[part 6 of 12: package /Cluster]
AUTOSAR XML (schema 4-3-0)
package /Cluster  (continued)
  can cluster HCP5_CANFD01: baudrate=500000, protocol-name=CAN, protocol-version=2.0, bus-off-recovery={bor-counter-l-1-to-l-2=1, bor-time-l-1=0.05, bor-time-l-2=0.2}, can-fd-baudrate=2000000  (continued)
    can physical channel CHNL: comm-connectors=CN_HCP5_CANFD01  (continued)
      frame NM_SACID_1_XIX_HCP5_CANFD01: id 0x1B00011B, to BMC_HV, frame-length=24, can-addressing-mode=EXTENDED, can-frame-rx-behavior=CAN-FD, can-frame-tx-behavior=CAN-FD, rx-identifier-range={lower-can-id=452984832, upper-can-id=452985855}
        nm pdu NM_SACID_1_XIX_HCP5_CANFD01: length=24, unused-bit-pattern=0
          signal NM_SACID_1_CBV_AWB_XIX_NM_SACID_1_XIX_HCP5_CANFD01: start 4, 1 bit, little-endian, data-type-policy=OVERRIDE, i-signal-type=PRIMITIVE, init-value=0, base-type=BT_NM_SACID_1_CBV_AWB, compu {0=Cx0_Passiver_WakeUp (CM_NM_SACID_1_CBV_AWB_Cx0_Passiver_WakeUp), 1=Cx1_Aktiver_WakeUp (CM_NM_SACID_1_CBV_AWB_Cx1_Aktiver_WakeUp)}, range raw 0..1, transfer-property=TRIGGERED  # Das Signal ist zu setzen, wenn das SG aktiv den Bus geweckt hat 0 = Passiver_WakeUp = SG hat das Netzwerk nicht aktiv geweckt 1 = Akitiver_WakeUp = SG hat das Netzwerk aktiv geweckt
          signal NM_SACID_1_CBV_CRI_XIX_NM_SACID_1_XIX_HCP5_CANFD01: start 6, 1 bit, little-endian, data-type-policy=OVERRIDE, i-signal-type=PRIMITIVE, init-value=1, base-type=BT_NM_SACID_1_CBV_CRI, compu {0=Cx0_NM_ohne_Clusteranforderungen (CM_NM_SACID_1_CBV_CRI_Cx0_NM_ohne_Clusteranforderungen), 1=Cx1_NM_mit_Clusteranforderungen (CM_NM_SACID_1_CBV_CRI_Cx1_NM_mit_Clusteranforderungen)}, range raw 0..1, transfer-property=TRIGGERED  # Das Signal ist dauerhaft gesetzt, wenn das NM-Layout Cluster- Anforderungen enthält
          signal NM_SACID_1_FCAB_XIX_NM_SACID_1_XIX_HCP5_CANFD01: start 8, 56 bit, opaque, data-type-policy=OVERRIDE, i-signal-type=ARRAY, init-value=7 x 0b00000000, base-type=BT_NM_SACID_1_FCAB, compu {0=Cx0_Init (CM_NM_SACID_1_FCAB_Cx0_Init), 1=Cx1_01_CarWakeUp (CM_NM_SACID_1_FCAB_Cx1_01_CarWakeUp), 2=Cx2_02_Basefunction_Powertrain (CM_NM_SACID_1_FCAB_Cx2_02_Basefunction_Powertrain), 4=Cx4_03_Basefunction_Chassis (CM_NM_SACID_1_FCAB_Cx4_03_Basefunction_Chassis), 8=Cx8_04_Basefunction_DrivingAssistance (CM_NM_SACID_1_FCAB_Cx8_04_Basefunction_DrivingAssistance), 16=Cx10_05_Basefunction_Infotainment (CM_NM_SACID_1_FCAB_Cx10_05_Basefunction_Infotainment), 32=Cx20_06_Basefunction_ComfortLight (CM_NM_SACID_1_FCAB_Cx20_06_Basefunction_ComfortLight), 64=Cx40_07_Basefunction_CrossSection (CM_NM_SACID_1_FCAB_Cx40_07_Basefunction_CrossSection), 128=Cx80_08_Basefunction_Connectivity (CM_NM_SACID_1_FCAB_Cx80_08_Basefunction_Connectivity), 256=Cx100_09_Basefunction_DrivingAssistanceCore (CM_NM_SACID_1_FCAB_Cx100_09_Basefunction_DrivingAssistanceCore), 512=Cx200_10_Powertrain (CM_NM_SACID_1_FCAB_Cx200_10_Powertrain), 1024=Cx400_11_Chassis (CM_NM_SACID_1_FCAB_Cx400_11_Chassis), 2048=Cx800_12_GearSelector (CM_NM_SACID_1_FCAB_Cx800_12_GearSelector), 4096=Cx1000_13_Airbag (CM_NM_SACID_1_FCAB_Cx1000_13_Airbag), 8192=Cx2000_14_InfotainmentExtensions (CM_NM_SACID_1_FCAB_Cx2000_14_InfotainmentExtensions), 16384=Cx4000_15_InstrumentclusterDisplay (CM_NM_SACID_1_FCAB_Cx4000_15_InstrumentclusterDisplay), 32768=Cx8000_16_InfotainmentDisplay (CM_NM_SACID_1_FCAB_Cx8000_16_InfotainmentDisplay), 65536=Cx10000_17_Audio (CM_NM_SACID_1_FCAB_Cx10000_17_Audio), 131072=Cx20000_18_VirtualSideMirrors (CM_NM_SACID_1_FCAB_Cx20000_18_VirtualSideMirrors), 262144=Cx40000_19_Doors_Hatches (CM_NM_SACID_1_FCAB_Cx40000_19_Doors_Hatches), 524288=Cx80000_20_OptionalComfort (CM_NM_SACID_1_FCAB_Cx80000_20_OptionalComfort), 1048576=Cx100000_21_AirSuspension (CM_NM_SACID_1_FCAB_Cx100000_21_AirSuspension), 2097152=Cx200000_22_ExteriorLights (CM_NM_SACID_1_FCAB_Cx200000_22_ExteriorLights), 4194304=Cx400000_23_Climate (CM_NM_SACID_1_FCAB_Cx400000_23_Climate), 8388608=Cx800000_24_ThermoManagement (CM_NM_SACID_1_FCAB_Cx800000_24_ThermoManagement), 16777216=Cx1000000_25_AccessSystemSensors (CM_NM_SACID_1_FCAB_Cx1000000_25_AccessSystemSensors), 33554432=Cx2000000_26_HighVoltage_Charging (CM_NM_SACID_1_FCAB_Cx2000000_26_HighVoltage_Charging), 67108864=Cx4000000_27_Timemaster_Timer (CM_NM_SACID_1_FCAB_Cx4000000_27_Timemaster_Timer), 134217728=Cx8000000_28_OnboardTester_DataCollector (CM_NM_SACID_1_FCAB_Cx8000000_28_OnboardTester_DataCollector), 268435456=Cx10000000_29_SteeringColumnLock (CM_NM_SACID_1_FCAB_Cx10000000_29_SteeringColumnLock), 536870912=Cx20000000_30_EnergyManagement (CM_NM_SACID_1_FCAB_Cx20000000_30_EnergyManagement), 1073741824=Cx40000000_31_MultifunctionalSteeringWheel (CM_NM_SACID_1_FCAB_Cx40000000_31_MultifunctionalSteeringWheel), 2147483648=Cx80000000_32_OnlineAccess (CM_NM_SACID_1_FCAB_Cx80000000_32_OnlineAccess), 4294967296=Cx100000000_33_ExternalWirelessCommunication (CM_NM_SACID_1_FCAB_Cx100000000_33_ExternalWirelessCommunication), 8589934592=Cx200000000_34_GPS_Localization (CM_NM_SACID_1_FCAB_Cx200000000_34_GPS_Localization), 17179869184=Cx400000000_35_ExteriorSound (CM_NM_SACID_1_FCAB_Cx400000000_35_ExteriorSound), 34359738368=Cx800000000_36_Preheater (CM_NM_SACID_1_FCAB_Cx800000000_36_Preheater), 68719476736=Cx1000000000_37_HighVoltage_WirelessChargingStation (CM_NM_SACID_1_FCAB_Cx1000000000_37_HighVoltage_WirelessChargingStation), 549755813888=Cx8000000000_40_Diagnosis_Energy (CM_NM_SACID_1_FCAB_Cx8000000000_40_Diagnosis_Energy), 1099511627776=Cx10000000000_41_Diagnosis_Powertrain (CM_NM_SACID_1_FCAB_Cx10000000000_41_Diagnosis_Powertrain), 2199023255552=Cx20000000000_42_Diagnosis_FlexRay (CM_NM_SACID_1_FCAB_Cx20000000000_42_Diagnosis_FlexRay), 4398046511104=Cx40000000000_43_Diagnosis_DrivingAssistance (CM_NM_SACID_1_FCAB_Cx40000000000_43_Diagnosis_DrivingAssistance), 8796093022208=Cx80000000000_44_Diagnosis_Infotainment (CM_NM_SACID_1_FCAB_Cx80000000000_44_Diagnosis_Infotainment), 17592186044416=Cx100000000000_45_Diagnosis_Comfort (CM_NM_SACID_1_FCAB_Cx100000000000_45_Diagnosis_Comfort), 35184372088832=Cx200000000000_46_Diagnosis_Light (CM_NM_SACID_1_FCAB_Cx200000000000_46_Diagnosis_Light), 70368744177664=Cx400000000000_47_Diagnosis_ComfortLINs (CM_NM_SACID_1_FCAB_Cx400000000000_47_Diagnosis_ComfortLINs), 140737488355328=Cx800000000000_48_Diagnosis_ClimateTmeLINs (CM_NM_SACID_1_FCAB_Cx800000000000_48_Diagnosis_ClimateTmeLINs), 281474976710656=Cx1000000000000_49_reserved (CM_NM_SACID_1_FCAB_Cx1000000000000_49_reserved) (49_<reserved>), 4503599627370500.0=Cx10000000000000_53_Lock_Unlock (CM_NM_SACID_1_FCAB_Cx10000000000000_53_Lock_Unlock), 9007199254740990.0=Cx20000000000000_54_reserved (CM_NM_SACID_1_FCAB_Cx20000000000000_54_reserved) (54_<reserved>), 1.8014398509482e+16=Cx40000000000000_55_Dimming (CM_NM_SACID_1_FCAB_Cx40000000000000_55_Dimming), 3.6028797018964e+16=Cx80000000000000_56_ChargingStatus (CM_NM_SACID_1_FCAB_Cx80000000000000_56_ChargingStatus)}, range raw 0..36028797018963968, transfer-property=TRIGGERED-ON-CHANGE, to BMC_HV(timeout 2 s)  # FCAB = Funktions-Cluster-Aktiv-Bits
          signal NM_SACID_1_SNI_10_XIX_NM_SACID_1_XIX_HCP5_CANFD01: start 128, 10 bit, little-endian, data-type-policy=OVERRIDE, i-signal-type=PRIMITIVE, init-value=283, base-type=BT_NM_SACID_1_SNI_10, compu {283=Cx11b_SACID_1_SNI (CM_NM_SACID_1_SNI_10_Cx11b_SACID_1_SNI)}, range raw 283, transfer-property=TRIGGERED  # Source Node-Identifier (SNI) identifiziert den Sender der NM-Botschaft (Knotenadresse) eindeutig im Fahrzeug
          signal NM_SACID_1_NM_State_XIX_NM_SACID_1_XIX_HCP5_CANFD01: start 144, 6 bit, little-endian, data-type-policy=OVERRIDE, i-signal-type=PRIMITIVE, init-value=0, base-type=BT_NM_SACID_1_NM_State, compu {0=Cx0_Init (CM_NM_SACID_1_NM_State_Cx0_Init), 1=Cx1_NM_RM_aus_BSM (CM_NM_SACID_1_NM_State_Cx1_NM_RM_aus_BSM), 2=Cx2_NM_RM_aus_PBSM (CM_NM_SACID_1_NM_State_Cx2_NM_RM_aus_PBSM), 4=Cx4_NM_NO_aus_RM (CM_NM_SACID_1_NM_State_Cx4_NM_NO_aus_RM), 8=Cx8_NM_NO_aus_RS (CM_NM_SACID_1_NM_State_Cx8_NM_NO_aus_RS), 16=Cx10_reserved (CM_NM_SACID_1_NM_State_Cx10_reserved), 32=Cx20_reserved (CM_NM_SACID_1_NM_State_Cx20_reserved)}, range raw 0..32, transfer-property=TRIGGERED  # 1 = Zustand Repeat Message (<-- Bus-Sleep Mode) 2 = Zustand Repeat Message (<-- Prepare Bus-Sleep Mode) 4 = Zustand Normal Operation (<-- Repeat Message) 8 = Zustand Normal Operation (<-- Ready Sleep)
          signal NM_SACID_1_UDS_CC_XIX_NM_SACID_1_XIX_HCP5_CANFD01: start 151, 1 bit, little-endian, data-type-policy=OVERRIDE, i-signal-type=PRIMITIVE, init-value=0, base-type=BT_NM_SACID_1_UDS_CC, compu {0=Cx0_Inaktiv (CM_NM_SACID_1_UDS_CC_Cx0_Inaktiv), 1=Cx1_CC_aktiv (CM_NM_SACID_1_UDS_CC_Cx1_CC_aktiv)}, range raw 0..1, transfer-property=TRIGGERED  # Funktionseinschränkung aufgrund aktivem UDS-Communication Control, siehe VW80124
          signal NM_SACID_1_Wakeup_V12_XIX_NM_SACID_1_XIX_HCP5_CANFD01: start 152, 8 bit, little-endian, data-type-policy=OVERRIDE, i-signal-type=PRIMITIVE, init-value=0, base-type=BT_NM_SACID_1_Wakeup_V12, compu {0=Cx0_Peripherie_Wakeup_Ursache_nicht_bekannt (CM_NM_SACID_1_Wakeup_V12_Cx0_Peripherie_Wakeup_Ursache_nicht_bekannt), 1=Cx1_Bus_Wakeup (CM_NM_SACID_1_Wakeup_V12_Cx1_Bus_Wakeup), 2=Cx2_KL15_HW (CM_NM_SACID_1_Wakeup_V12_Cx2_KL15_HW), 4=Cx4_Bedienung_an_Ladedose (CM_NM_SACID_1_Wakeup_V12_Cx4_Bedienung_an_Ladedose), 5=Cx5_Stecker_erkannt (CM_NM_SACID_1_Wakeup_V12_Cx5_Stecker_erkannt), 6=Cx6_SmartCharging_Aktualisierung (CM_NM_SACID_1_Wakeup_V12_Cx6_SmartCharging_Aktualisierung)}, range raw 0..6, transfer-property=TRIGGERED  # enthält die Weckursache; stehen mehrere Weckursachen parallel an, dann muss der kleinste Wert übertragen werden
          signal NM_SACID_1_NM_aktiv_KL15_XIX_NM_SACID_1_XIX_HCP5_CANFD01: start 160, 1 bit, little-endian, data-type-policy=OVERRIDE, i-signal-type=PRIMITIVE, init-value=0, base-type=BT_NM_SACID_1_NM_aktiv_KL15, compu {0=Cx0_Inaktiv (CM_NM_SACID_1_NM_aktiv_KL15_Cx0_Inaktiv), 1=Cx1_KL15_EIN (CM_NM_SACID_1_NM_aktiv_KL15_Cx1_KL15_EIN)}, range raw 0..1, transfer-property=TRIGGERED  # Steuergerät hat KL15-EIN erkannt
          signal NM_SACID_1_NM_aktiv_Diag_XIX_NM_SACID_1_XIX_HCP5_CANFD01: start 161, 1 bit, little-endian, data-type-policy=OVERRIDE, i-signal-type=PRIMITIVE, init-value=0, base-type=BT_NM_SACID_1_NM_aktiv_Diag, compu {0=Cx0_Inaktiv (CM_NM_SACID_1_NM_aktiv_Diag_Cx0_Inaktiv), 1=Cx1_Diagnose_aktiv (CM_NM_SACID_1_NM_aktiv_Diag_Cx1_Diagnose_aktiv)}, range raw 0..1, transfer-property=TRIGGERED  # Diagnose befindet sich nach VW80124 in einer NonDefaultDiagnostic-Session, z.B. ExtendedDiagnostic-Session
          signal NM_SACID_1_NM_aktiv_Tmin_XIX_NM_SACID_1_XIX_HCP5_CANFD01: start 162, 1 bit, little-endian, data-type-policy=OVERRIDE, i-signal-type=PRIMITIVE, init-value=0, base-type=BT_NM_SACID_1_NM_aktiv_Tmin, compu {0=Cx0_Inaktiv (CM_NM_SACID_1_NM_aktiv_Tmin_Cx0_Inaktiv), 1=Cx1_Mindestaktivzeit (CM_NM_SACID_1_NM_aktiv_Tmin_Cx1_Mindestaktivzeit)}, range raw 0..1, transfer-property=TRIGGERED  # Mindestaktivzeit ist noch nicht abgelaufen (bei jedem Weckereignis wird die Mindestaktivzeit neu gestartet)
          signal NM_aktiv_Bedienung_an_Ladedose_1_XIX_NM_SACID_1_XIX_HCP5_CANFD01: start 163, 1 bit, little-endian, data-type-policy=OVERRIDE, i-signal-type=PRIMITIVE, init-value=0, base-type=BT_NM_aktiv_Bedienung_an_Ladedose_1, compu {0=Cx0_Inaktiv (CM_NM_aktiv_Bedienung_an_Ladedose_1_Cx0_Inaktiv), 1=Cx1_Aktiv (CM_NM_aktiv_Bedienung_an_Ladedose_1_Cx1_Aktiv)}, range raw 0..1, transfer-property=TRIGGERED  # Für die verschiedenen Bedienelemente an der Ladedose muss die HV-Ladefunktion im HCP5 geweckt werden um den Status zu erhalten und ggf. weitere Steuergeräte zu wecken
          signal NM_aktiv_Ladestecker_erkannt_1_XIX_NM_SACID_1_XIX_HCP5_CANFD01: start 164, 1 bit, little-endian, data-type-policy=OVERRIDE, i-signal-type=PRIMITIVE, init-value=0, base-type=BT_NM_aktiv_Ladestecker_erkannt_1, compu {0=Cx0_Inaktiv (CM_NM_aktiv_Ladestecker_erkannt_1_Cx0_Inaktiv), 1=Cx1_Aktiv (CM_NM_aktiv_Ladestecker_erkannt_1_Cx1_Aktiv)}, range raw 0..1, transfer-property=TRIGGERED  # Ladestecker erkannt und Absetzen der Information an das Hochvolt-Lademanagement
          signal NM_aktiv_SmartCharging_Aktiv_XIX_NM_SACID_1_XIX_HCP5_CANFD01: start 165, 1 bit, little-endian, data-type-policy=OVERRIDE, i-signal-type=PRIMITIVE, init-value=0, base-type=BT_NM_aktiv_SmartCharging_Aktiv, compu {0=Cx0_Inaktiv (CM_NM_aktiv_SmartCharging_Aktiv_Cx0_Inaktiv), 1=Cx1_Aktiv (CM_NM_aktiv_SmartCharging_Aktiv_Cx1_Aktiv)}, range raw 0..1, transfer-property=TRIGGERED  # Wenn eine Verbindung zum Smart Home's HEMS über die ConMod via WLAN aufgebaut wurde, dann muss das SACID 1 die Verbindugn so lange aktiv halten bis alle Daten empfangen wurden.
      frame NM_SACID_2_XIX_HCP5_CANFD01: id 0x1B00011C, to BMC_HV, frame-length=24, can-addressing-mode=EXTENDED, can-frame-rx-behavior=CAN-FD, can-frame-tx-behavior=CAN-FD, rx-identifier-range={lower-can-id=452984832, upper-can-id=452985855}
        nm pdu NM_SACID_2_XIX_HCP5_CANFD01: length=24, unused-bit-pattern=0
          signal NM_SACID_2_CBV_AWB_XIX_NM_SACID_2_XIX_HCP5_CANFD01: start 4, 1 bit, little-endian, data-type-policy=OVERRIDE, i-signal-type=PRIMITIVE, init-value=0, base-type=BT_NM_SACID_2_CBV_AWB, compu {0=Cx0_Passiver_WakeUp (CM_NM_SACID_2_CBV_AWB_Cx0_Passiver_WakeUp), 1=Cx1_Aktiver_WakeUp (CM_NM_SACID_2_CBV_AWB_Cx1_Aktiver_WakeUp)}, range raw 0..1, transfer-property=TRIGGERED  # Das Signal ist zu setzen, wenn das SG aktiv den Bus geweckt hat 0 = Passiver_WakeUp = SG hat das Netzwerk nicht aktiv geweckt 1 = Akitiver_WakeUp = SG hat das Netzwerk aktiv geweckt
          signal NM_SACID_2_CBV_CRI_XIX_NM_SACID_2_XIX_HCP5_CANFD01: start 6, 1 bit, little-endian, data-type-policy=OVERRIDE, i-signal-type=PRIMITIVE, init-value=1, base-type=BT_NM_SACID_2_CBV_CRI, compu {0=Cx0_NM_ohne_Clusteranforderungen (CM_NM_SACID_2_CBV_CRI_Cx0_NM_ohne_Clusteranforderungen), 1=Cx1_NM_mit_Clusteranforderungen (CM_NM_SACID_2_CBV_CRI_Cx1_NM_mit_Clusteranforderungen)}, range raw 0..1, transfer-property=TRIGGERED  # Das Signal ist dauerhaft gesetzt, wenn das NM-Layout Cluster- Anforderungen enthält
          signal NM_SACID_2_FCAB_XIX_NM_SACID_2_XIX_HCP5_CANFD01: start 8, 56 bit, opaque, data-type-policy=OVERRIDE, i-signal-type=ARRAY, init-value=7 x 0b00000000, base-type=BT_NM_SACID_2_FCAB, compu {0=Cx0_Init (CM_NM_SACID_2_FCAB_Cx0_Init), 1=Cx1_01_CarWakeUp (CM_NM_SACID_2_FCAB_Cx1_01_CarWakeUp), 2=Cx2_02_Basefunction_Powertrain (CM_NM_SACID_2_FCAB_Cx2_02_Basefunction_Powertrain), 4=Cx4_03_Basefunction_Chassis (CM_NM_SACID_2_FCAB_Cx4_03_Basefunction_Chassis), 8=Cx8_04_Basefunction_DrivingAssistance (CM_NM_SACID_2_FCAB_Cx8_04_Basefunction_DrivingAssistance), 16=Cx10_05_Basefunction_Infotainment (CM_NM_SACID_2_FCAB_Cx10_05_Basefunction_Infotainment), 32=Cx20_06_Basefunction_ComfortLight (CM_NM_SACID_2_FCAB_Cx20_06_Basefunction_ComfortLight), 64=Cx40_07_Basefunction_CrossSection (CM_NM_SACID_2_FCAB_Cx40_07_Basefunction_CrossSection), 128=Cx80_08_Basefunction_Connectivity (CM_NM_SACID_2_FCAB_Cx80_08_Basefunction_Connectivity), 256=Cx100_09_Basefunction_DrivingAssistanceCore (CM_NM_SACID_2_FCAB_Cx100_09_Basefunction_DrivingAssistanceCore), 512=Cx200_10_Powertrain (CM_NM_SACID_2_FCAB_Cx200_10_Powertrain), 1024=Cx400_11_Chassis (CM_NM_SACID_2_FCAB_Cx400_11_Chassis), 2048=Cx800_12_GearSelector (CM_NM_SACID_2_FCAB_Cx800_12_GearSelector), 4096=Cx1000_13_Airbag (CM_NM_SACID_2_FCAB_Cx1000_13_Airbag), 8192=Cx2000_14_InfotainmentExtensions (CM_NM_SACID_2_FCAB_Cx2000_14_InfotainmentExtensions), 16384=Cx4000_15_InstrumentclusterDisplay (CM_NM_SACID_2_FCAB_Cx4000_15_InstrumentclusterDisplay), 32768=Cx8000_16_InfotainmentDisplay (CM_NM_SACID_2_FCAB_Cx8000_16_InfotainmentDisplay), 65536=Cx10000_17_Audio (CM_NM_SACID_2_FCAB_Cx10000_17_Audio), 131072=Cx20000_18_VirtualSideMirrors (CM_NM_SACID_2_FCAB_Cx20000_18_VirtualSideMirrors), 262144=Cx40000_19_Doors_Hatches (CM_NM_SACID_2_FCAB_Cx40000_19_Doors_Hatches), 524288=Cx80000_20_OptionalComfort (CM_NM_SACID_2_FCAB_Cx80000_20_OptionalComfort), 1048576=Cx100000_21_AirSuspension (CM_NM_SACID_2_FCAB_Cx100000_21_AirSuspension), 2097152=Cx200000_22_ExteriorLights (CM_NM_SACID_2_FCAB_Cx200000_22_ExteriorLights), 4194304=Cx400000_23_Climate (CM_NM_SACID_2_FCAB_Cx400000_23_Climate), 8388608=Cx800000_24_ThermoManagement (CM_NM_SACID_2_FCAB_Cx800000_24_ThermoManagement), 16777216=Cx1000000_25_AccessSystemSensors (CM_NM_SACID_2_FCAB_Cx1000000_25_AccessSystemSensors), 33554432=Cx2000000_26_HighVoltage_Charging (CM_NM_SACID_2_FCAB_Cx2000000_26_HighVoltage_Charging), 67108864=Cx4000000_27_Timemaster_Timer (CM_NM_SACID_2_FCAB_Cx4000000_27_Timemaster_Timer), 134217728=Cx8000000_28_OnboardTester_DataCollector (CM_NM_SACID_2_FCAB_Cx8000000_28_OnboardTester_DataCollector), 268435456=Cx10000000_29_SteeringColumnLock (CM_NM_SACID_2_FCAB_Cx10000000_29_SteeringColumnLock), 536870912=Cx20000000_30_EnergyManagement (CM_NM_SACID_2_FCAB_Cx20000000_30_EnergyManagement), 1073741824=Cx40000000_31_MultifunctionalSteeringWheel (CM_NM_SACID_2_FCAB_Cx40000000_31_MultifunctionalSteeringWheel), 2147483648=Cx80000000_32_OnlineAccess (CM_NM_SACID_2_FCAB_Cx80000000_32_OnlineAccess), 4294967296=Cx100000000_33_ExternalWirelessCommunication (CM_NM_SACID_2_FCAB_Cx100000000_33_ExternalWirelessCommunication), 8589934592=Cx200000000_34_GPS_Localization (CM_NM_SACID_2_FCAB_Cx200000000_34_GPS_Localization), 17179869184=Cx400000000_35_ExteriorSound (CM_NM_SACID_2_FCAB_Cx400000000_35_ExteriorSound), 34359738368=Cx800000000_36_Preheater (CM_NM_SACID_2_FCAB_Cx800000000_36_Preheater), 68719476736=Cx1000000000_37_HighVoltage_WirelessChargingStation (CM_NM_SACID_2_FCAB_Cx1000000000_37_HighVoltage_WirelessChargingStation), 549755813888=Cx8000000000_40_Diagnosis_Energy (CM_NM_SACID_2_FCAB_Cx8000000000_40_Diagnosis_Energy), 1099511627776=Cx10000000000_41_Diagnosis_Powertrain (CM_NM_SACID_2_FCAB_Cx10000000000_41_Diagnosis_Powertrain), 2199023255552=Cx20000000000_42_Diagnosis_FlexRay (CM_NM_SACID_2_FCAB_Cx20000000000_42_Diagnosis_FlexRay), 4398046511104=Cx40000000000_43_Diagnosis_DrivingAssistance (CM_NM_SACID_2_FCAB_Cx40000000000_43_Diagnosis_DrivingAssistance), 8796093022208=Cx80000000000_44_Diagnosis_Infotainment (CM_NM_SACID_2_FCAB_Cx80000000000_44_Diagnosis_Infotainment), 17592186044416=Cx100000000000_45_Diagnosis_Comfort (CM_NM_SACID_2_FCAB_Cx100000000000_45_Diagnosis_Comfort), 35184372088832=Cx200000000000_46_Diagnosis_Light (CM_NM_SACID_2_FCAB_Cx200000000000_46_Diagnosis_Light), 70368744177664=Cx400000000000_47_Diagnosis_ComfortLINs (CM_NM_SACID_2_FCAB_Cx400000000000_47_Diagnosis_ComfortLINs), 140737488355328=Cx800000000000_48_Diagnosis_ClimateTmeLINs (CM_NM_SACID_2_FCAB_Cx800000000000_48_Diagnosis_ClimateTmeLINs), 281474976710656=Cx1000000000000_49_reserved (CM_NM_SACID_2_FCAB_Cx1000000000000_49_reserved) (49_<reserved>), 4503599627370500.0=Cx10000000000000_53_Lock_Unlock (CM_NM_SACID_2_FCAB_Cx10000000000000_53_Lock_Unlock), 9007199254740990.0=Cx20000000000000_54_reserved (CM_NM_SACID_2_FCAB_Cx20000000000000_54_reserved) (54_<reserved>), 1.8014398509482e+16=Cx40000000000000_55_Dimming (CM_NM_SACID_2_FCAB_Cx40000000000000_55_Dimming), 3.6028797018964e+16=Cx80000000000000_56_ChargingStatus (CM_NM_SACID_2_FCAB_Cx80000000000000_56_ChargingStatus)}, range raw 0..36028797018963968, transfer-property=TRIGGERED-ON-CHANGE, to BMC_HV(timeout 2 s)  # FCAB = Funktions-Cluster-Aktiv-Bits
          signal NM_SACID_2_SNI_10_XIX_NM_SACID_2_XIX_HCP5_CANFD01: start 128, 10 bit, little-endian, data-type-policy=OVERRIDE, i-signal-type=PRIMITIVE, init-value=284, base-type=BT_NM_SACID_2_SNI_10, compu {284=Cx11c_SACID_2_SNI (CM_NM_SACID_2_SNI_10_Cx11c_SACID_2_SNI)}, range raw 284, transfer-property=TRIGGERED  # Source Node-Identifier (SNI) identifiziert den Sender der NM-Botschaft (Knotenadresse) eindeutig im Fahrzeug
          signal NM_SACID_2_NM_State_XIX_NM_SACID_2_XIX_HCP5_CANFD01: start 144, 6 bit, little-endian, data-type-policy=OVERRIDE, i-signal-type=PRIMITIVE, init-value=0, base-type=BT_NM_SACID_2_NM_State, compu {0=Cx0_Init (CM_NM_SACID_2_NM_State_Cx0_Init), 1=Cx1_NM_RM_aus_BSM (CM_NM_SACID_2_NM_State_Cx1_NM_RM_aus_BSM), 2=Cx2_NM_RM_aus_PBSM (CM_NM_SACID_2_NM_State_Cx2_NM_RM_aus_PBSM), 4=Cx4_NM_NO_aus_RM (CM_NM_SACID_2_NM_State_Cx4_NM_NO_aus_RM), 8=Cx8_NM_NO_aus_RS (CM_NM_SACID_2_NM_State_Cx8_NM_NO_aus_RS), 16=Cx10_reserved (CM_NM_SACID_2_NM_State_Cx10_reserved), 32=Cx20_reserved (CM_NM_SACID_2_NM_State_Cx20_reserved)}, range raw 0..32, transfer-property=TRIGGERED  # 1 = Zustand Repeat Message (<-- Bus-Sleep Mode) 2 = Zustand Repeat Message (<-- Prepare Bus-Sleep Mode) 4 = Zustand Normal Operation (<-- Repeat Message) 8 = Zustand Normal Operation (<-- Ready Sleep)
          signal NM_SACID_2_UDS_CC_XIX_NM_SACID_2_XIX_HCP5_CANFD01: start 151, 1 bit, little-endian, data-type-policy=OVERRIDE, i-signal-type=PRIMITIVE, init-value=0, base-type=BT_NM_SACID_2_UDS_CC, compu {0=Cx0_Inaktiv (CM_NM_SACID_2_UDS_CC_Cx0_Inaktiv), 1=Cx1_CC_aktiv (CM_NM_SACID_2_UDS_CC_Cx1_CC_aktiv)}, range raw 0..1, transfer-property=TRIGGERED  # Funktionseinschränkung aufgrund aktivem UDS-Communication Control, siehe VW80124
          signal NM_SACID_2_Wakeup_V12_XIX_NM_SACID_2_XIX_HCP5_CANFD01: start 152, 8 bit, little-endian, data-type-policy=OVERRIDE, i-signal-type=PRIMITIVE, init-value=0, base-type=BT_NM_SACID_2_Wakeup_V12, compu {0=Cx0_Peripherie_Wakeup_Ursache_nicht_bekannt (CM_NM_SACID_2_Wakeup_V12_Cx0_Peripherie_Wakeup_Ursache_nicht_bekannt), 1=Cx1_Bus_Wakeup (CM_NM_SACID_2_Wakeup_V12_Cx1_Bus_Wakeup), 2=Cx2_KL15_HW (CM_NM_SACID_2_Wakeup_V12_Cx2_KL15_HW), 4=Cx4_Bedienung_an_Ladedose (CM_NM_SACID_2_Wakeup_V12_Cx4_Bedienung_an_Ladedose), 5=Cx5_Stecker_erkannt (CM_NM_SACID_2_Wakeup_V12_Cx5_Stecker_erkannt)}, range raw 0..5, transfer-property=TRIGGERED  # enthält die Weckursache; stehen mehrere Weckursachen parallel an, dann muss der kleinste Wert übertragen werden
          signal NM_SACID_2_NM_aktiv_KL15_XIX_NM_SACID_2_XIX_HCP5_CANFD01: start 160, 1 bit, little-endian, data-type-policy=OVERRIDE, i-signal-type=PRIMITIVE, init-value=0, base-type=BT_NM_SACID_2_NM_aktiv_KL15, compu {0=Cx0_Inaktiv (CM_NM_SACID_2_NM_aktiv_KL15_Cx0_Inaktiv), 1=Cx1_KL15_EIN (CM_NM_SACID_2_NM_aktiv_KL15_Cx1_KL15_EIN)}, range raw 0..1, transfer-property=TRIGGERED  # Steuergerät hat KL15-EIN erkannt
          signal NM_SACID_2_NM_aktiv_Diag_XIX_NM_SACID_2_XIX_HCP5_CANFD01: start 161, 1 bit, little-endian, data-type-policy=OVERRIDE, i-signal-type=PRIMITIVE, init-value=0, base-type=BT_NM_SACID_2_NM_aktiv_Diag, compu {0=Cx0_Inaktiv (CM_NM_SACID_2_NM_aktiv_Diag_Cx0_Inaktiv), 1=Cx1_Diagnose_aktiv (CM_NM_SACID_2_NM_aktiv_Diag_Cx1_Diagnose_aktiv)}, range raw 0..1, transfer-property=TRIGGERED  # Diagnose befindet sich nach VW80124 in einer NonDefaultDiagnostic-Session, z.B. ExtendedDiagnostic-Session
          signal NM_SACID_2_NM_aktiv_Tmin_XIX_NM_SACID_2_XIX_HCP5_CANFD01: start 162, 1 bit, little-endian, data-type-policy=OVERRIDE, i-signal-type=PRIMITIVE, init-value=0, base-type=BT_NM_SACID_2_NM_aktiv_Tmin, compu {0=Cx0_Inaktiv (CM_NM_SACID_2_NM_aktiv_Tmin_Cx0_Inaktiv), 1=Cx1_Mindestaktivzeit (CM_NM_SACID_2_NM_aktiv_Tmin_Cx1_Mindestaktivzeit)}, range raw 0..1, transfer-property=TRIGGERED  # Mindestaktivzeit ist noch nicht abgelaufen (bei jedem Weckereignis wird die Mindestaktivzeit neu gestartet)
          signal NM_aktiv_Bedienung_an_Ladedose_2_XIX_NM_SACID_2_XIX_HCP5_CANFD01: start 163, 1 bit, little-endian, data-type-policy=OVERRIDE, i-signal-type=PRIMITIVE, init-value=0, base-type=BT_NM_aktiv_Bedienung_an_Ladedose_2, compu {0=Cx0_Inaktiv (CM_NM_aktiv_Bedienung_an_Ladedose_2_Cx0_Inaktiv), 1=Cx1_Aktiv (CM_NM_aktiv_Bedienung_an_Ladedose_2_Cx1_Aktiv)}, range raw 0..1, transfer-property=TRIGGERED  # Für die verschiedenen Bedienelemente an der Ladedose muss die HV-Ladefunktion im HCP5 geweckt werden um den Status zu erhalten und ggf. weitere Steuergeräte zu wecken
          signal NM_aktiv_Ladestecker_erkannt_2_XIX_NM_SACID_2_XIX_HCP5_CANFD01: start 164, 1 bit, little-endian, data-type-policy=OVERRIDE, i-signal-type=PRIMITIVE, init-value=0, base-type=BT_NM_aktiv_Ladestecker_erkannt_2, compu {0=Cx0_Inaktiv (CM_NM_aktiv_Ladestecker_erkannt_2_Cx0_Inaktiv), 1=Cx1_Aktiv (CM_NM_aktiv_Ladestecker_erkannt_2_Cx1_Aktiv)}, range raw 0..1, transfer-property=TRIGGERED  # Ladestecker erkannt und Absetzen der Information an das Hochvolt-Lademanagement
      frame NVEM_12_XIX_HCP5_CANFD01: id 0x237, to BMC_HV, frame-length=12, can-addressing-mode=STANDARD, can-frame-rx-behavior=CAN-FD, can-frame-tx-behavior=CAN-FD
        pdu NVEM_12_XIX_HCP5_CANFD01: length=12, transmission-mode-true-timing=cyclic-timing={time-offset=0, time-period=0.1}, unused-bit-pattern=0
          signal NVEM_12_CRC_XIX_NVEM_12_XIX_HCP5_CANFD01: start 0, 8 bit, little-endian, data-type-policy=OVERRIDE, i-signal-type=PRIMITIVE, init-value=0, base-type=BT_NVEM_12_CRC, compu {phys=raw for raw 0..255}, range phys 0..255, raw 0..255, transfer-property=PENDING  # Für MLB: Berechnung siehe Lastenheft "Kommunikationsabsicherung für FlexRay und CAN" Ab MQB und MLBevo: Berechnung siehe Lastenheft "End-to-End Kommunikationsabsicherung" Endwerte siehe Begleitdokument "S-PDU Kennungsfolgen"
          signal NVEM_12_BZ_XIX_NVEM_12_XIX_HCP5_CANFD01: start 8, 4 bit, little-endian, data-type-policy=OVERRIDE, i-signal-type=PRIMITIVE, init-value=0, base-type=BT_NVEM_12_BZ, compu {phys=raw for raw 0..15}, range phys 0..15, raw 0..15, transfer-property=PENDING  # 4bit Botschaftszähler, wird mit jeder Sendebotschaft inkrementiert
          signal NVEM_Bordnetzdiagnose_XIX_NVEM_12_XIX_HCP5_CANFD01: start 12, 2 bit, little-endian, data-type-policy=OVERRIDE, i-signal-type=PRIMITIVE, init-value=0, base-type=BT_NVEM_Bordnetzdiagnose, compu {0=Cx0_kein_Fehler (CM_NVEM_Bordnetzdiagnose_Cx0_kein_Fehler), 1=Cx1_Warnung_1 (CM_NVEM_Bordnetzdiagnose_Cx1_Warnung_1), 2=Cx2_Warnung_2 (CM_NVEM_Bordnetzdiagnose_Cx2_Warnung_2), 3=Cx3_Warnung_3 (CM_NVEM_Bordnetzdiagnose_Cx3_Warnung_3)}, range raw 0..3, transfer-property=PENDING  # Wird vom NVEM im NV-Netz ein Bordnetz-Fehler erkannt, so soll dies zu einer mehrstufigen Anzeige führen.
          signal NVEM_Last_Anf_XIX_NVEM_12_XIX_HCP5_CANFD01: start 14, 2 bit, little-endian, data-type-policy=OVERRIDE, i-signal-type=PRIMITIVE, init-value=0, base-type=BT_NVEM_Last_Anf, compu {0=Cx0_keine_Anforderung (CM_NVEM_Last_Anf_Cx0_keine_Anforderung) (keine Anforderung), 1=Cx1_Verbraucher_Anforderung_Stufe_1 (CM_NVEM_Last_Anf_Cx1_Verbraucher_Anforderung_Stufe_1), 2=Cx2_Verbraucher_Anforderung_Stufe_2 (CM_NVEM_Last_Anf_Cx2_Verbraucher_Anforderung_Stufe_2), 3=Cx3_Verbraucher_Anforderung_Stufe_3 (CM_NVEM_Last_Anf_Cx3_Verbraucher_Anforderung_Stufe_3)}, range raw 0..3, transfer-property=PENDING  # Das NVEM fordert für die Batteriediagnose einen Lastimpuls vom Fahrzeug an, der durch kontrollierte Verbraucherzuschaltungen (z. B. Aktivierung Heckscheibenheizung) generiert wird
          signal BEM_HL_Regelung_Status_XIX_NVEM_12_XIX_HCP5_CANFD01: start 16, 3 bit, little-endian, data-type-policy=OVERRIDE, i-signal-type=PRIMITIVE, init-value=0, base-type=BT_BEM_HL_Regelung_Status, compu {0=Cx0_HL_Regelung_inaktiv_vor_und_waehrend_Motorstart (CM_BEM_HL_Regelung_Status_Cx0_HL_Regelung_inaktiv_vor_und_waehrend_Motorstart) (HL_Regelung_inaktiv_(vor_und_waehrend_Motorstart)), 1=Cx1_HL_Regelung_Stufe_1 (CM_BEM_HL_Regelung_Status_Cx1_HL_Regelung_Stufe_1), 2=Cx2_HL_Regelung_Stufe_2 (CM_BEM_HL_Regelung_Status_Cx2_HL_Regelung_Stufe_2), 3=Cx3_HL_Regelung_Stufe_3 (CM_BEM_HL_Regelung_Status_Cx3_HL_Regelung_Stufe_3), 4=Cx4_Verbrauchernotabschaltung_VNA (CM_BEM_HL_Regelung_Status_Cx4_Verbrauchernotabschaltung_VNA) (Verbrauchernotabschaltung_(VNA)), 5=Cx5_HL_Regelung_Stufe_5 (CM_BEM_HL_Regelung_Status_Cx5_HL_Regelung_Stufe_5), 7=Cx7_Default (CM_BEM_HL_Regelung_Status_Cx7_Default)}, range raw 0..7, transfer-property=PENDING  # Status Regelung Heizleistung
          signal NVEM_Abschaltstufe_XIX_NVEM_12_XIX_HCP5_CANFD01: start 19, 2 bit, little-endian, data-type-policy=OVERRIDE, i-signal-type=PRIMITIVE, init-value=0, base-type=BT_NVEM_Abschaltstufe, compu {0=Cx0_Stufe_0_keine_Einschraenkung (CM_NVEM_Abschaltstufe_Cx0_Stufe_0_keine_Einschraenkung), 1=Cx1_Stufe_1 (CM_NVEM_Abschaltstufe_Cx1_Stufe_1), 2=Cx2_Stufe_2 (CM_NVEM_Abschaltstufe_Cx2_Stufe_2), 3=Cx3_Stufe_3 (CM_NVEM_Abschaltstufe_Cx3_Stufe_3)}, range raw 0..3, transfer-property=PENDING, to BMC_HV(timeout 1 s)  # Abschaltstufe aus dem Ruheenergiemanagement Maßnahmen des Empfängers werden im QLAH Ruhestrommanagement definiert
          signal NVEM_NV_BAT_ZellStatus_Index_Anf_XIX_NVEM_12_XIX_HCP5_CANFD01: start 21, 4 bit, little-endian, data-type-policy=OVERRIDE, i-signal-type=PRIMITIVE, init-value=0, base-type=BT_NVEM_NV_BAT_ZellStatus_Index_Anf, compu {0=Cx0_Cell_Nr_1 (CM_NVEM_NV_BAT_ZellStatus_Index_Anf_Cx0_Cell_Nr_1), 1=Cx1_Cell_Nr_2 (CM_NVEM_NV_BAT_ZellStatus_Index_Anf_Cx1_Cell_Nr_2), 2=Cx2_Cell_Nr_3 (CM_NVEM_NV_BAT_ZellStatus_Index_Anf_Cx2_Cell_Nr_3), 3=Cx3_Cell_Nr_4 (CM_NVEM_NV_BAT_ZellStatus_Index_Anf_Cx3_Cell_Nr_4), 4=Cx4_Cell_Nr_5 (CM_NVEM_NV_BAT_ZellStatus_Index_Anf_Cx4_Cell_Nr_5), 5=Cx5_Cell_Nr_6 (CM_NVEM_NV_BAT_ZellStatus_Index_Anf_Cx5_Cell_Nr_6), 6=Cx6_Cell_Nr_7 (CM_NVEM_NV_BAT_ZellStatus_Index_Anf_Cx6_Cell_Nr_7), 7=Cx7_Cell_Nr_8 (CM_NVEM_NV_BAT_ZellStatus_Index_Anf_Cx7_Cell_Nr_8), 8=Cx8_Cell_Nr_9 (CM_NVEM_NV_BAT_ZellStatus_Index_Anf_Cx8_Cell_Nr_9), 9=Cx9_Cell_Nr_10 (CM_NVEM_NV_BAT_ZellStatus_Index_Anf_Cx9_Cell_Nr_10), 10=Cxa_Cell_Nr_11 (CM_NVEM_NV_BAT_ZellStatus_Index_Anf_Cxa_Cell_Nr_11), 11=Cxb_Cell_Nr_12 (CM_NVEM_NV_BAT_ZellStatus_Index_Anf_Cxb_Cell_Nr_12), 12=Cxc_Cell_Nr_13 (CM_NVEM_NV_BAT_ZellStatus_Index_Anf_Cxc_Cell_Nr_13), 13=Cxd_Cell_Nr_14 (CM_NVEM_NV_BAT_ZellStatus_Index_Anf_Cxd_Cell_Nr_14), 14=Cxe_Cell_Nr_15 (CM_NVEM_NV_BAT_ZellStatus_Index_Anf_Cxe_Cell_Nr_15), 15=Cxf_Cell_Nr_16 (CM_NVEM_NV_BAT_ZellStatus_Index_Anf_Cxf_Cell_Nr_16)}, range raw 0..15, transfer-property=PENDING  # Multiplex signal for cell number of low voltage battery.
          signal NVEM_NV_BAT_ZellStatus_Typ_Anf_XIX_NVEM_12_XIX_HCP5_CANFD01: start 25, 3 bit, little-endian, data-type-policy=OVERRIDE, i-signal-type=PRIMITIVE, init-value=0, base-type=BT_NVEM_NV_BAT_ZellStatus_Typ_Anf, compu {0=Cx0_Init (CM_NVEM_NV_BAT_ZellStatus_Typ_Anf_Cx0_Init), 1=Cx1_Voltage (CM_NVEM_NV_BAT_ZellStatus_Typ_Anf_Cx1_Voltage), 2=Cx2_Temperature (CM_NVEM_NV_BAT_ZellStatus_Typ_Anf_Cx2_Temperature), 3=Cx3_Voltage_limit (CM_NVEM_NV_BAT_ZellStatus_Typ_Anf_Cx3_Voltage_limit) (Voltage limit), 4=Cx4_SoF (CM_NVEM_NV_BAT_ZellStatus_Typ_Anf_Cx4_SoF), 5=Cx5_SoH_C (CM_NVEM_NV_BAT_ZellStatus_Typ_Anf_Cx5_SoH_C), 6=Cx6_reserved (CM_NVEM_NV_BAT_ZellStatus_Typ_Anf_Cx6_reserved), 7=Cx7_reserved (CM_NVEM_NV_BAT_ZellStatus_Typ_Anf_Cx7_reserved)}, range raw 0..7, transfer-property=PENDING  # Multiplex signal for cell status of low voltage battery.
          signal NVEM_Freigabe_OTA_XIX_NVEM_12_XIX_HCP5_CANFD01: start 28, 2 bit, little-endian, data-type-policy=OVERRIDE, i-signal-type=PRIMITIVE, init-value=0, base-type=BT_NVEM_Freigabe_OTA, compu {0=Cx0_Init (CM_NVEM_Freigabe_OTA_Cx0_Init), 1=Cx1_Keine_Freigabe (CM_NVEM_Freigabe_OTA_Cx1_Keine_Freigabe), 2=Cx2_Freigabe (CM_NVEM_Freigabe_OTA_Cx2_Freigabe)}, range raw 0..2, transfer-property=PENDING  # Bestätigung oder Ablehnung eines konkreten, angefragten Online-Updates durch das Energiemangement
          signal BEM_Generatordiagnose_XIX_NVEM_12_XIX_HCP5_CANFD01: start 30, 2 bit, little-endian, data-type-policy=OVERRIDE, i-signal-type=PRIMITIVE, init-value=0, base-type=BT_BEM_Generatordiagnose, compu {0=Cx0_keine_Anzeige (CM_BEM_Generatordiagnose_Cx0_keine_Anzeige) (keine Anzeige), 1=Cx1_Ladekontrollanzeige_ein_Vorhalt (CM_BEM_Generatordiagnose_Cx1_Ladekontrollanzeige_ein_Vorhalt) (Ladekontrollanzeige ein (Vorhalt)), 2=Cx2_rotes_Batteriesymbol_und_Text_Generator_defekt (CM_BEM_Generatordiagnose_Cx2_rotes_Batteriesymbol_und_Text_Generator_defekt) (rotes Batteriesymbol und Text (Generator defekt)), 3=Cx3_Hybrid_DCDC_Wandler_defekt (CM_BEM_Generatordiagnose_Cx3_Hybrid_DCDC_Wandler_defekt)}, range raw 0..3, transfer-property=PENDING  # Ansteuerung Generatorwarnleuchte im Kombi
          signal NVEM_DC_uSoll_NV_XIX_NVEM_12_XIX_HCP5_CANFD01: start 32, 8 bit, little-endian, data-type-policy=OVERRIDE, i-signal-type=PRIMITIVE, init-value=116, base-type=BT_NVEM_DC_uSoll_NV, invalid-value=Invalid_NVEM_DC_uSoll_NV_XIX_NVEM_12_XIX_HCP5_CANFD01:255, compu {phys=raw*0.025+10.6 for raw 0..216, 255=Cxff_Fehler (CM_NVEM_DC_uSoll_NV_Cxff_Fehler); unit Unit_Volt}, range phys 10.6..16 Unit_Volt, raw 0..255, unit=Unit_Volt, transfer-property=PENDING  # Sollspannung 12V Seite des DC Wandlers, feine Auflösung
          signal NVEM_DC_iSoll_NV_XIX_NVEM_12_XIX_HCP5_CANFD01: start 40, 8 bit, little-endian, data-type-policy=OVERRIDE, i-signal-type=PRIMITIVE, init-value=254, base-type=BT_NVEM_DC_iSoll_NV, invalid-value=Invalid_NVEM_DC_iSoll_NV_XIX_NVEM_12_XIX_HCP5_CANFD01:255, compu {phys=raw-253 for raw 0..253, 254=Cxfe_Init (CM_NVEM_DC_iSoll_NV_Cxfe_Init), 255=Cxff_Fehler (CM_NVEM_DC_iSoll_NV_Cxff_Fehler); unit Unit_Amper}, range phys -253..0 Unit_Amper, raw 0..255, unit=Unit_Amper, transfer-property=PENDING  # Soll-Entladestrom 12V Seite des DCDC Wandlers
          signal BEM_Batt_Ab_XIX_NVEM_12_XIX_HCP5_CANFD01: start 48, 1 bit, little-endian, data-type-policy=OVERRIDE, i-signal-type=PRIMITIVE, init-value=0, base-type=BT_BEM_Batt_Ab, compu {0=Cx0_verbunden (CM_BEM_Batt_Ab_Cx0_verbunden), 1=Cx1_nicht_verbunden (CM_BEM_Batt_Ab_Cx1_nicht_verbunden)}, range raw 0..1, transfer-property=PENDING  # Batterieverbindungskontrolle: 0x0: Batterie am Bordnetz 0x1: Batterie ab erkannt
          signal BEM_Red_Innengeblaese_XIX_NVEM_12_XIX_HCP5_CANFD01: start 49, 2 bit, little-endian, data-type-policy=OVERRIDE, i-signal-type=PRIMITIVE, init-value=0, base-type=BT_BEM_Red_Innengeblaese, compu {0=Cx0_keine_Reduzierung (CM_BEM_Red_Innengeblaese_Cx0_keine_Reduzierung) (keine Reduzierung), 1=Cx1_Reduzierung_Stufe_1 (CM_BEM_Red_Innengeblaese_Cx1_Reduzierung_Stufe_1) (Reduzierung Stufe 1), 2=Cx2_Reduzierung_Stufe_2 (CM_BEM_Red_Innengeblaese_Cx2_Reduzierung_Stufe_2) (Reduzierung Stufe 2), 3=Cx3_Reduzierung_Stufe_2_und_Abschaltung_Kompressor (CM_BEM_Red_Innengeblaese_Cx3_Reduzierung_Stufe_2_und_Abschaltung_Kompressor) (Reduzierung Stufe 2 und Abschaltung Kompressor)}, range raw 0..3, transfer-property=PENDING  # Reduzierung Innengebläse
          signal NVEM_MV_DC_uMinLV_XIX_NVEM_12_XIX_HCP5_CANFD01: start 51, 7 bit, little-endian, data-type-policy=OVERRIDE, i-signal-type=PRIMITIVE, init-value=126, base-type=BT_NVEM_MV_DC_uMinLV, invalid-value=Invalid_NVEM_MV_DC_uMinLV_XIX_NVEM_12_XIX_HCP5_CANFD01:127, compu {phys=raw*0.1+3.5 for raw 0..125, 126=Cx7e_Init (CM_NVEM_MV_DC_uMinLV_Cx7e_Init), 127=Cx7f_Fehler (CM_NVEM_MV_DC_uMinLV_Cx7f_Fehler); unit Unit_Volt}, range phys 3.5..16 Unit_Volt, raw 0..127, unit=Unit_Volt, transfer-property=PENDING  # Abregelgrenze: minimal erlaubte Bordnetzspannung im Hochsetzbetrieb vom 12V-Bordnetz ins 48V-Netz
          signal NVEM_MV_DC_uSollLV_XIX_NVEM_12_XIX_HCP5_CANFD01: start 58, 7 bit, little-endian, data-type-policy=OVERRIDE, i-signal-type=PRIMITIVE, init-value=126, base-type=BT_NVEM_MV_DC_uSollLV, invalid-value=Invalid_NVEM_MV_DC_uSollLV_XIX_NVEM_12_XIX_HCP5_CANFD01:127, compu {phys=raw*0.05+10.6 for raw 0..108, 126=Cx7e_Init (CM_NVEM_MV_DC_uSollLV_Cx7e_Init), 127=Cx7f_Fehler (CM_NVEM_MV_DC_uSollLV_Cx7f_Fehler); unit Unit_Volt}, range phys 10.6..16 Unit_Volt, raw 0..127, unit=Unit_Volt, transfer-property=PENDING  # Sollwert für die 12V-Bordnetzspannung im Tiefsetzbetrieb vom 48V-Netz ins 12V-Bordnetz
          signal BEM_STH_Einschaltverbot_XIX_NVEM_12_XIX_HCP5_CANFD01: start 65, 1 bit, little-endian, data-type-policy=OVERRIDE, i-signal-type=PRIMITIVE, init-value=0, base-type=BT_BEM_STH_Einschaltverbot, compu {0=Cx0_volle_Verfuegbarkeit_Standheizung_lueftung (CM_BEM_STH_Einschaltverbot_Cx0_volle_Verfuegbarkeit_Standheizung_lueftung) (volle Verfuegbarkeit Standheizung/-lueftung), 1=Cx1_Standheizung_lueftung_nicht_aktivierbar (CM_BEM_STH_Einschaltverbot_Cx1_Standheizung_lueftung_nicht_aktivierbar) (Standheizung/-lueftung nicht aktivierbar)}, range raw 0..1, transfer-property=PENDING  # Einschränkung Standheizung/-lüftung durch BEM: Setzt der BEM das Bit, dann darf die Standheizung nicht mehr einschalten (Die Standheizung muss aber nicht abschalten, sondern darf weiterbrennen) (Initialisierungswert aus EEprom)
          signal BEM_STH_Zielzeit_XIX_NVEM_12_XIX_HCP5_CANFD01: start 66, 4 bit, little-endian, data-type-policy=OVERRIDE, i-signal-type=PRIMITIVE, init-value=14, base-type=BT_BEM_STH_Zielzeit, invalid-value=Invalid_BEM_STH_Zielzeit_XIX_NVEM_12_XIX_HCP5_CANFD01:15, compu {phys=raw*5 for raw 0..12, 14=Cxe_Init (CM_BEM_STH_Zielzeit_Cxe_Init), 15=Cxf_Fehler (CM_BEM_STH_Zielzeit_Cxf_Fehler); unit Unit_Minut}, range phys 0..60 Unit_Minut, raw 0..15, unit=Unit_Minut, transfer-property=PENDING  # Maximal mögliche Zeit für den Standheizungsbetrieb, um die Startfähigkeit nicht zu gefährden
          signal NVEM_Verbraucher_Information_XIX_NVEM_12_XIX_HCP5_CANFD01: start 70, 3 bit, little-endian, data-type-policy=OVERRIDE, i-signal-type=PRIMITIVE, init-value=6, base-type=BT_NVEM_Verbraucher_Information, invalid-value=Invalid_NVEM_Verbraucher_Information_XIX_NVEM_12_XIX_HCP5_CANFD01:7, compu {0=Cx0_Keine_Anzeige (CM_NVEM_Verbraucher_Information_Cx0_Keine_Anzeige), 1=Cx1_MMI_Vorwarnung (CM_NVEM_Verbraucher_Information_Cx1_MMI_Vorwarnung), 2=Cx2_Anzeige_Verbraucherabschaltung (CM_NVEM_Verbraucher_Information_Cx2_Anzeige_Verbraucherabschaltung), 3=Cx3_reserviert (CM_NVEM_Verbraucher_Information_Cx3_reserviert), 4=Cx4_reserviert (CM_NVEM_Verbraucher_Information_Cx4_reserviert), 5=Cx5_reserviert (CM_NVEM_Verbraucher_Information_Cx5_reserviert), 6=Cx6_Init (CM_NVEM_Verbraucher_Information_Cx6_Init), 7=Cx7_Fehler (CM_NVEM_Verbraucher_Information_Cx7_Fehler)}, range raw 0..7, transfer-property=PENDING  # Mit diesem Signal löst Das NVM eine Anzeige bzgl. einer bevorstehenden oder erfolgten Verbraucherabschaltung aus
          signal NVEM3_Absch_SCR_XIX_NVEM_12_XIX_HCP5_CANFD01: start 73, 1 bit, little-endian, data-type-policy=OVERRIDE, i-signal-type=PRIMITIVE, init-value=0, base-type=BT_NVEM3_Absch_SCR, compu {0=Cx0_Init (CM_NVEM3_Absch_SCR_Cx0_Init), 1=Cx1_Abschaltung_SCR (CM_NVEM3_Absch_SCR_Cx1_Abschaltung_SCR)}, range raw 0..1, transfer-property=PENDING  # Abschaltung der SCR-Heizung durch das NVEM bei energetisch kritischen Zuständen.
          signal NVEM_Bordnetz_Information_XIX_NVEM_12_XIX_HCP5_CANFD01: start 76, 4 bit, little-endian, data-type-policy=OVERRIDE, i-signal-type=PRIMITIVE, init-value=14, base-type=BT_NVEM_Bordnetz_Information, invalid-value=Invalid_NVEM_Bordnetz_Information_XIX_NVEM_12_XIX_HCP5_CANFD01:15, compu {0=Cx0_keine_Anzeige (CM_NVEM_Bordnetz_Information_Cx0_keine_Anzeige), 1=Cx1_NV_Batterie_iO (CM_NVEM_Bordnetz_Information_Cx1_NV_Batterie_iO), 2=Cx2_NV_Batterie_laden (CM_NVEM_Bordnetz_Information_Cx2_NV_Batterie_laden), 3=Cx3_NV_Batterie_pruefen (CM_NVEM_Bordnetz_Information_Cx3_NV_Batterie_pruefen), 4=Cx4_NV_Batterie_schwach (CM_NVEM_Bordnetz_Information_Cx4_NV_Batterie_schwach), 5=Cx5_NV_Batterie_Ab (CM_NVEM_Bordnetz_Information_Cx5_NV_Batterie_Ab), 6=Cx6_NV_Batterie_Service (CM_NVEM_Bordnetz_Information_Cx6_NV_Batterie_Service), 7=Cx7_NV_Energiesystem_unplausibel (CM_NVEM_Bordnetz_Information_Cx7_NV_Energiesystem_unplausibel), 8=Cx8_Ladekontrollleuchte (CM_NVEM_Bordnetz_Information_Cx8_Ladekontrollleuchte), 9=Cx9_Generator_defekt (CM_NVEM_Bordnetz_Information_Cx9_Generator_defekt), 10=Cxa_reserviert (CM_NVEM_Bordnetz_Information_Cxa_reserviert), 11=Cxb_reserviert (CM_NVEM_Bordnetz_Information_Cxb_reserviert), 12=Cxc_reserviert (CM_NVEM_Bordnetz_Information_Cxc_reserviert), 13=Cxd_reserviert (CM_NVEM_Bordnetz_Information_Cxd_reserviert), 14=Cxe_Init (CM_NVEM_Bordnetz_Information_Cxe_Init), 15=Cxf_Fehler (CM_NVEM_Bordnetz_Information_Cxf_Fehler)}, range raw 0..15, transfer-property=PENDING  # Informationsanzeigen zum 12V - Bordnetz
          signal NVEM_DC_uMin_NV_XIX_NVEM_12_XIX_HCP5_CANFD01: start 80, 8 bit, little-endian, data-type-policy=OVERRIDE, i-signal-type=PRIMITIVE, init-value=122, base-type=BT_NVEM_DC_uMin_NV, compu {phys=raw*0.1 for raw 0..255; unit Unit_Volt}, range phys 0..25.5 Unit_Volt, raw 0..255, unit=Unit_Volt, transfer-property=PENDING  # Mindestspannung des DCDC Wandlers im Hochsetzbetrieb auf 12V Seite
          signal NVEM_MV_DC_iSoll_NV_XIX_NVEM_12_XIX_HCP5_CANFD01: start 88, 8 bit, little-endian, data-type-policy=OVERRIDE, i-signal-type=PRIMITIVE, init-value=254, base-type=BT_NVEM_MV_DC_iSoll_NV, invalid-value=Invalid_NVEM_MV_DC_iSoll_NV_XIX_NVEM_12_XIX_HCP5_CANFD01:255, compu {phys=raw-253 for raw 0..253, 254=Cxfe_Init (CM_NVEM_MV_DC_iSoll_NV_Cxfe_Init), 255=Cxff_Fehler (CM_NVEM_MV_DC_iSoll_NV_Cxff_Fehler); unit Unit_Amper}, range phys -253..0 Unit_Amper, raw 0..255, unit=Unit_Amper, transfer-property=PENDING  # Sollstromvorgabe NVEM an MV - DCDC Wandler
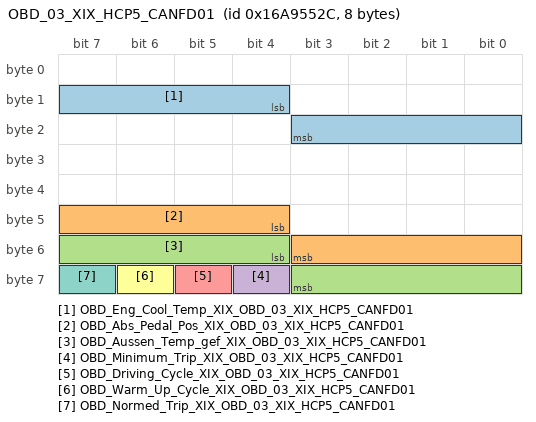
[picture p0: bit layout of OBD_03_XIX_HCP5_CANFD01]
      frame OBD_03_XIX_HCP5_CANFD01: id 0x16A9552C, to BMC_HV, frame-length=8, can-addressing-mode=EXTENDED, can-frame-rx-behavior=CAN-FD, can-frame-tx-behavior=CAN-FD
        pdu OBD_03_XIX_HCP5_CANFD01: length=8, transmission-mode-true-timing=cyclic-timing={time-offset=0, time-period=0.32}, unused-bit-pattern=0
          signal OBD_Eng_Cool_Temp_XIX_OBD_03_XIX_HCP5_CANFD01: start 12, 8 bit, little-endian, data-type-policy=OVERRIDE, i-signal-type=PRIMITIVE, init-value=255, base-type=BT_OBD_Eng_Cool_Temp, compu {phys=raw-40 for raw 0..255; unit Unit_DegreCelsi}, range phys -40..215 Unit_DegreCelsi, raw 0..255, unit=Unit_DegreCelsi, transfer-property=PENDING, to BMC_HV(timeout 3.2 s)  # Engine Coolant Temperature Übertragung von Meßgrößen an das Getriebesteuergerät für Freeze Frame Abspeicherung bei Getriebefehlern PID $05 Engine Coolant Temperature; -40 .. +215°C mit 1°C/bit und 40°C Offset
          signal OBD_Abs_Pedal_Pos_XIX_OBD_03_XIX_HCP5_CANFD01: start 44, 8 bit, little-endian, data-type-policy=OVERRIDE, i-signal-type=PRIMITIVE, init-value=255, base-type=BT_OBD_Abs_Pedal_Pos, compu {phys=raw*0.3921568627 for raw 0..255; unit Unit_PerCent}, range phys 0..100 Unit_PerCent, raw 0..255, unit=Unit_PerCent, transfer-property=PENDING, to BMC_HV(timeout 3.2 s)  # Absolute Pedal Position Übertragung von Meßgrößen an das Getriebesteuergerät für Freeze Frame Abspeicherung bei Getriebefehlern PID $49 Accelerator Pedal Position D; 0 .. 100% mit 100/255 %/bit
          signal OBD_Aussen_Temp_gef_XIX_OBD_03_XIX_HCP5_CANFD01: start 52, 8 bit, little-endian, data-type-policy=OVERRIDE, i-signal-type=PRIMITIVE, init-value=254, base-type=BT_OBD_Aussen_Temp_gef, invalid-value=Invalid_OBD_Aussen_Temp_gef_XIX_OBD_03_XIX_HCP5_CANFD01:255, compu {phys=raw-40 for raw 0..253, 254=Cxfe_Initwert (CM_OBD_Aussen_Temp_gef_Cxfe_Initwert), 255=Cxff_Fehler (CM_OBD_Aussen_Temp_gef_Cxff_Fehler); unit Unit_DegreCelsi}, range phys -40..213 Unit_DegreCelsi, raw 0..255, unit=Unit_DegreCelsi, transfer-property=PENDING, to BMC_HV(timeout 3.2 s)  # Gefilterte Aussentemperatur vom Motor für OBD Funktionen.
          signal OBD_Minimum_Trip_XIX_OBD_03_XIX_HCP5_CANFD01: start 60, 1 bit, little-endian, data-type-policy=OVERRIDE, i-signal-type=PRIMITIVE, init-value=0, base-type=BT_OBD_Minimum_Trip, compu {0=Cx0_kein_Min_Normed_Trip (CM_OBD_Minimum_Trip_Cx0_kein_Min_Normed_Trip), 1=Cx1_Min_Normed_Trip (CM_OBD_Minimum_Trip_Cx1_Min_Normed_Trip)}, range raw 0..1, transfer-property=PENDING, to BMC_HV(timeout 3.2 s)  # Grundlage OBD-Gesetz CCR 1968.2 (d)(4.3) Denominator Specifications Bildung des General Denominator "Normed Trip": 600 sec. (kumulativ) Zeit nach Motorstart 300 sec. (kumulativ) mit Fahrzeuggeschwindigkeit > 25 mph (40 km/h) 30 sec. (kontinuierlich) Leerlauf Wenn alle diese Bedingungen erfüllt wurden ist ein OBD_Min_Normed_Trip erfüllt
          signal OBD_Driving_Cycle_XIX_OBD_03_XIX_HCP5_CANFD01: start 61, 1 bit, little-endian, data-type-policy=OVERRIDE, i-signal-type=PRIMITIVE, init-value=0, base-type=BT_OBD_Driving_Cycle, compu {0=Cx0_kein_Driving_Cycle_erkannt (CM_OBD_Driving_Cycle_Cx0_kein_Driving_Cycle_erkannt), 1=Cx1_Driving_Cycle_erkannt (CM_OBD_Driving_Cycle_Cx1_Driving_Cycle_erkannt)}, range raw 0..1, transfer-property=PENDING, to BMC_HV(timeout 3.2 s)  # Signalisierung Driving Cycle Qualifizierung - Trigger Ignition Cycle Counter
          signal OBD_Warm_Up_Cycle_XIX_OBD_03_XIX_HCP5_CANFD01: start 62, 1 bit, little-endian, data-type-policy=OVERRIDE, i-signal-type=PRIMITIVE, init-value=0, base-type=BT_OBD_Warm_Up_Cycle, compu {0=Cx0_kein_Warm_Up_Cycle_erkannt (CM_OBD_Warm_Up_Cycle_Cx0_kein_Warm_Up_Cycle_erkannt), 1=Cx1_Warm_Up_Cycle_erkannt (CM_OBD_Warm_Up_Cycle_Cx1_Warm_Up_Cycle_erkannt)}, range raw 0..1, transfer-property=PENDING, to BMC_HV(timeout 3.2 s)  # Mit dem Warm-Up-Cycle wird der zentrale Verlernzähler vom Gateway inkrementiert
          signal OBD_Normed_Trip_XIX_OBD_03_XIX_HCP5_CANFD01: start 63, 1 bit, little-endian, data-type-policy=OVERRIDE, i-signal-type=PRIMITIVE, init-value=0, base-type=BT_OBD_Normed_Trip, compu {0=Cx0_kein_Normed_Trip (CM_OBD_Normed_Trip_Cx0_kein_Normed_Trip), 1=Cx1_Normed_Trip (CM_OBD_Normed_Trip_Cx1_Normed_Trip)}, range raw 0..1, transfer-property=PENDING, to BMC_HV(timeout 3.2 s)  # Gesetzlich definierte "Normed Condition" erfüllt, "General Denominator" darf erhöht werden
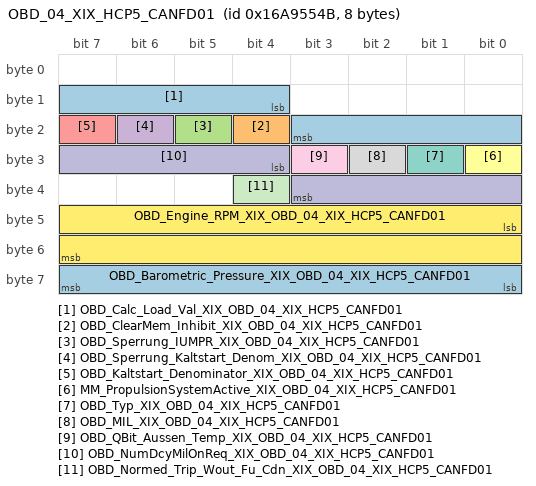
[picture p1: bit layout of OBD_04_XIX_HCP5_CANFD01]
      frame OBD_04_XIX_HCP5_CANFD01: id 0x16A9554B, to BMC_HV, frame-length=8, can-addressing-mode=EXTENDED, can-frame-rx-behavior=CAN-FD, can-frame-tx-behavior=CAN-FD
        pdu OBD_04_XIX_HCP5_CANFD01: length=8, minimum-delay=0.08, transmission-mode-true-timing={cyclic-timing={time-offset=0, time-period=0.32}, event-controlled-timing={number-of-repetitions=0, repetition-period=0}}, unused-bit-pattern=0
          signal OBD_Calc_Load_Val_XIX_OBD_04_XIX_HCP5_CANFD01: start 12, 8 bit, little-endian, data-type-policy=OVERRIDE, i-signal-type=PRIMITIVE, init-value=255, base-type=BT_OBD_Calc_Load_Val, compu {phys=raw*0.3921568627 for raw 0..255; unit Unit_PerCent}, range phys 0..100 Unit_PerCent, raw 0..255, unit=Unit_PerCent, transfer-property=PENDING, to BMC_HV(timeout 3.2 s)  # Calculated Load Value Übertragung von Meßgrößen an das Getriebesteuergerät für Freeze Frame Abspeicherung bei Getriebefehlern PID $04 Calculated Load Value; 0 .. 100% mit 100/255 % per bit
          signal OBD_ClearMem_Inhibit_XIX_OBD_04_XIX_HCP5_CANFD01: start 20, 1 bit, little-endian, data-type-policy=OVERRIDE, i-signal-type=PRIMITIVE, init-value=0, base-type=BT_OBD_ClearMem_Inhibit, compu {0=Cx0_FSP_Loeschen_zulaessig (CM_OBD_ClearMem_Inhibit_Cx0_FSP_Loeschen_zulaessig), 1=Cx1_FSP_Loeschen_nicht_zulaessig (CM_OBD_ClearMem_Inhibit_Cx1_FSP_Loeschen_nicht_zulaessig)}, range raw 0..1, transfer-property=PENDING, to BMC_HV(timeout 3.2 s)  # Bei FSP_Loeschen_zulässig müssen alle OBD-ECUs im Gesamtfahrzeug einen Service 04hex Request (Ereignisspeicher löschen) korrekt ausführen. In MLB-, MLBevo-, MQB-Fahrzeugkonzepten muss der MIL-Master/Motorsteuergerät bei Kl.15 ein, projektabhängig, konstant OBD_ClearMem_Inhibit = 0 senden, sofern das Löschen des Ereignisspeichers noch in jedem Betriebszustand (auch bei laufendem Motor, etc.) gefordert ist. Projektspezifisch im MLB-, MLBevo-, und MQB-Fahrzeugkonzepten und vollumfänglich in MQB_37W- und MLB3-Fahrzeugkonzepten wird das Ereignisspeicher löschen in allen OBD-ECUs auf den Betriebszustand stehendes Fahrzeug und stehender Motor beschränkt und die entsprechende Freigabe das Ereignisspeicher Löschens vom MIL-Master über das Bussignal OBD_ClearMem_Inhibit für alle anderen OBD-ECUs im Gesamtfahrzeug signalisiert. Hinweis: Steuergerät- oder Komponentenspezifische Randbedingungen sind unter Abhängigkeit des Sicherheitskonzepts zu prüfen und zu bewerten.
          signal OBD_Sperrung_IUMPR_XIX_OBD_04_XIX_HCP5_CANFD01: start 21, 1 bit, little-endian, data-type-policy=OVERRIDE, i-signal-type=PRIMITIVE, init-value=0, base-type=BT_OBD_Sperrung_IUMPR, compu {0=Cx0_IUMPR_Berechnung_freigegeben (CM_OBD_Sperrung_IUMPR_Cx0_IUMPR_Berechnung_freigegeben), 1=Cx1_IUMPR_Berechnung_gesperrt (CM_OBD_Sperrung_IUMPR_Cx1_IUMPR_Berechnung_gesperrt)}, range raw 0..1, transfer-property=PENDING, to BMC_HV(timeout 3.2 s)  # Wenn der General Denominator auf Grund eines Fehlers in den Eingangsgrößen gesperrt wird, wird diese Information über Bussystem als OBD-Statusinformation OBD_Sperrung_IUMPR für andere OBD-Steuergeräte bereitgestellt. Das MSG (MIL-Master) setzt dieses Bit, wenn auf Grund vorliegender Sperrbedingungen keine Inkrementierung des GeneralDenominator mehr stattfindet. Im Empfänger-SG ist entsprechend die Inkrementierung des oder der Numeratoren einzufrieren.
          signal OBD_Sperrung_Kaltstart_Denom_XIX_OBD_04_XIX_HCP5_CANFD01: start 22, 1 bit, little-endian, data-type-policy=OVERRIDE, i-signal-type=PRIMITIVE, init-value=0, base-type=BT_OBD_Sperrung_Kaltstart_Denom, compu {0=Cx0_EVAP_Berechnung_freigegeben (CM_OBD_Sperrung_Kaltstart_Denom_Cx0_EVAP_Berechnung_freigegeben), 1=Cx1_EVAP_Berechnung_gesperrt (CM_OBD_Sperrung_Kaltstart_Denom_Cx1_EVAP_Berechnung_gesperrt)}, range raw 0..1, transfer-property=PENDING, to BMC_HV(timeout 3.2 s)  # Information vom MIL Master, dass die Bildung des EVAP Denominators im Motor nicht möglich ist und damit der noECM-Denominator gesperrt werden darf.
          signal OBD_Kaltstart_Denominator_XIX_OBD_04_XIX_HCP5_CANFD01: start 23, 1 bit, little-endian, data-type-policy=OVERRIDE, i-signal-type=PRIMITIVE, init-value=0, base-type=BT_OBD_Kaltstart_Denominator, compu {0=Cx0_Denominator_nicht_hochzaehlen (CM_OBD_Kaltstart_Denominator_Cx0_Denominator_nicht_hochzaehlen), 1=Cx1_Bedingungen_zum_Inkr_des_Kaltstart_Denom_erf (CM_OBD_Kaltstart_Denominator_Cx1_Bedingungen_zum_Inkr_des_Kaltstart_Denom_erf)}, range raw 0..1, transfer-property=PENDING, to BMC_HV(timeout 3.2 s)  # Bestimmte Diagnosen werden nur unter Kaltstartbedingungen durchgeführt, der entsprechende Denominator bei IUMPR-pflichtigen Systemen wird anhand dieses vom MSG gebildeten Signals inkrementiert. (Entspricht EVAP-Denominator)
          signal MM_PropulsionSystemActive_XIX_OBD_04_XIX_HCP5_CANFD01: start 24, 1 bit, little-endian, data-type-policy=OVERRIDE, i-signal-type=PRIMITIVE, init-value=0, base-type=BT_MM_PropulsionSystemActive, compu {0=Cx0_PropulsionSystemNotActive (CM_MM_PropulsionSystemActive_Cx0_PropulsionSystemNotActive), 1=Cx1_PropulsionSystemActive (CM_MM_PropulsionSystemActive_Cx1_PropulsionSystemActive)}, range raw 0..1, transfer-property=TRIGGERED-ON-CHANGE-WITHOUT-REPETITION, to BMC_HV(timeout 3.2 s)  # Fahrzeug ist fahrbereit
          signal OBD_Typ_XIX_OBD_04_XIX_HCP5_CANFD01: start 25, 1 bit, little-endian, data-type-policy=OVERRIDE, i-signal-type=PRIMITIVE, init-value=0, base-type=BT_OBD_Typ, compu {0=Cx0_OBDReady (CM_OBD_Typ_Cx0_OBDReady), 1=Cx1_FullOBD (CM_OBD_Typ_Cx1_FullOBD)}, range raw 0..1, transfer-property=PENDING, to BMC_HV(timeout 3.2 s)  # Abgastyp OBD Hinweis: In Fahrzeugen mit dem Zielmarkt China und einer Zertifizierung ab China 6 muss auf dem Signal "OBD_Typ" der Wert "US_OBD" gesendet werden."
          signal OBD_MIL_XIX_OBD_04_XIX_HCP5_CANFD01: start 26, 1 bit, little-endian, data-type-policy=OVERRIDE, i-signal-type=PRIMITIVE, init-value=0, base-type=BT_OBD_MIL, invalid-value=Invalid_OBD_MIL_XIX_OBD_04_XIX_HCP5_CANFD01:1, compu {0=Cx0_Lampe_aus (CM_OBD_MIL_Cx0_Lampe_aus), 1=Cx1_Fehler (CM_OBD_MIL_Cx1_Fehler)}, range raw 0..1, transfer-property=TRIGGERED-ON-CHANGE-WITHOUT-REPETITION  # Ansteuerung der MIL
          signal OBD_QBit_Aussen_Temp_XIX_OBD_04_XIX_HCP5_CANFD01: start 27, 1 bit, little-endian, data-type-policy=OVERRIDE, i-signal-type=PRIMITIVE, init-value=1, base-type=BT_OBD_QBit_Aussen_Temp, compu {0=Cx0_gueltiger_Wert (CM_OBD_QBit_Aussen_Temp_Cx0_gueltiger_Wert), 1=Cx1_Ersatz_Init_oder_Fehlerwert (CM_OBD_QBit_Aussen_Temp_Cx1_Ersatz_Init_oder_Fehlerwert)}, range raw 0..1, transfer-property=TRIGGERED-ON-CHANGE-WITHOUT-REPETITION, to BMC_HV(timeout 3.2 s)  # QBit der Aussentemperatur. Gesetzt bei Ersatzwert, Init oder Fehler.
          signal OBD_NumDcyMilOnReq_XIX_OBD_04_XIX_HCP5_CANFD01: start 28, 8 bit, little-endian, data-type-policy=OVERRIDE, i-signal-type=PRIMITIVE, init-value=0, base-type=BT_OBD_NumDcyMilOnReq, compu {phys=raw for raw 0..255; unit Unit_None}, range phys 0..255 Unit_None, raw 0..255, unit=Unit_None, transfer-property=PENDING, to BMC_HV(timeout 3.2 s)  # Anzahl der DrivingCycle für MIL-Entprellung von MIL-Master
          signal OBD_Normed_Trip_Wout_Fu_Cdn_XIX_OBD_04_XIX_HCP5_CANFD01: start 36, 1 bit, little-endian, data-type-policy=OVERRIDE, i-signal-type=PRIMITIVE, init-value=0, base-type=BT_OBD_Normed_Trip_Wout_Fu_Cdn, compu {0=Cx0_kein_Normed_Trip_wo_Fu_Cdn (CM_OBD_Normed_Trip_Wout_Fu_Cdn_Cx0_kein_Normed_Trip_wo_Fu_Cdn), 1=Cx1_Normed_Trip_wo_Fu_Cdn (CM_OBD_Normed_Trip_Wout_Fu_Cdn_Cx1_Normed_Trip_wo_Fu_Cdn)}, range raw 0..1, transfer-property=PENDING  # Bedingung für General Denominator-Inkrementierung ohne FueledEngine-Operation -> wird für die Berechnung des General Denominators in der Motorsteuerung (ScanTool-Ausgabe Mode$09, InfoType$08, OBDCOND) benötigt
          signal OBD_Engine_RPM_XIX_OBD_04_XIX_HCP5_CANFD01: start 40, 16 bit, little-endian, data-type-policy=OVERRIDE, i-signal-type=PRIMITIVE, init-value=0, base-type=BT_OBD_Engine_RPM, compu {phys=raw*0.25 for raw 0..65535; unit Unit_MinutInver}, range phys 0..16383.75 Unit_MinutInver, raw 0..65535, unit=Unit_MinutInver, transfer-property=PENDING, to BMC_HV(timeout 3.2 s)  # Motordrehzahl des Verbrennungsmotors für OBD freeze frame
          signal OBD_Barometric_Pressure_XIX_OBD_04_XIX_HCP5_CANFD01: start 56, 8 bit, little-endian, data-type-policy=OVERRIDE, i-signal-type=PRIMITIVE, init-value=0, base-type=BT_OBD_Barometric_Pressure, compu {phys=raw for raw 0..255; unit Unit_KiloPascal}, range phys 0..255 Unit_KiloPascal, raw 0..255, unit=Unit_KiloPascal, transfer-property=PENDING, to BMC_HV(timeout 3.2 s)  # Umgebungsdruck für OBD freeze frame
      frame OBD_HCP1_SOK_XIX_HCP5_CANFD01: id 0x17E4000F, to BMC_HV, frame-length=6, can-addressing-mode=EXTENDED, can-frame-rx-behavior=CAN-FD, can-frame-tx-behavior=CAN-FD
        secured i pdu OBD_HCP1_SOK_XIX_HCP5_CANFD01:
          length=6
          authentication-props=SecureCommunicationAuthenticationProps_XIX_32
          freshness-props=SecureCommunicationFreshnessProps
          payload=PT_OBD_HCP1
          secure-communication-props={auth-data-freshness-length=0, auth-data-freshness-start-position=0, auth-info-tx-length=32, authentication-build-attempts=1, authentication-retries=4, data-id=864, freshness-value-id=2, freshness-value-length=64, freshness-value-tx-length=0}
          use-as-cryptographic-i-pdu=false
      frame OBD_Hybrid_01_SOK_XIX_HCP5_CANFD01: id 0x17E40005, from BMC_HV, frame-length=6, can-addressing-mode=EXTENDED, can-frame-rx-behavior=CAN-FD, can-frame-tx-behavior=CAN-FD
        secured i pdu OBD_Hybrid_01_SOK_XIX_HCP5_CANFD01:
          length=6
          authentication-props=SecureCommunicationAuthenticationProps_XIX_32
          freshness-props=SecureCommunicationFreshnessProps
          payload=PT_OBD_Hybrid_01
          secure-communication-props={auth-data-freshness-length=0, auth-data-freshness-start-position=0, auth-info-tx-length=32, authentication-build-attempts=1, authentication-retries=4, data-id=865, freshness-value-id=7, freshness-value-length=64, freshness-value-tx-length=0}
          use-as-cryptographic-i-pdu=false
      frame OBDC_Funktionaler_Req_All_FD_XIX_HCP5_CANFD01: id 0x1C410200, to BMC_HV, frame-length=64, can-addressing-mode=EXTENDED, can-frame-rx-behavior=CAN-FD, can-frame-tx-behavior=CAN-FD
        n pdu OBDC_Funktionaler_Req_All_FD_XIX_HCP5_CANFD01: length=64
      frame OBDC_Hybrid_01_Req_FD_XIX_HCP5_CANFD01: id 0x1C40027B, to BMC_HV, frame-length=64, can-addressing-mode=EXTENDED, can-frame-rx-behavior=CAN-FD, can-frame-tx-behavior=CAN-FD
        n pdu OBDC_Hybrid_01_Req_FD_XIX_HCP5_CANFD01: length=64
      frame OBDC_Hybrid_01_Resp_FD_XIX_HCP5_CANFD01: id 0x1C42027B, from BMC_HV, frame-length=64, can-addressing-mode=EXTENDED, can-frame-rx-behavior=CAN-FD, can-frame-tx-behavior=CAN-FD
        n pdu OBDC_Hybrid_01_Resp_FD_XIX_HCP5_CANFD01: length=64
      frame OBDC_SSN_BJB_Req_XIX_HCP5_CANFD01: id 0x17FC70D0, to BMC_HV, frame-length=8, can-addressing-mode=EXTENDED, can-frame-rx-behavior=CAN-FD, can-frame-tx-behavior=CAN-FD
        n pdu OBDC_SSN_BJB_Req_XIX_HCP5_CANFD01: length=8
      frame OBDC_SSN_BJB_Resp_XIX_HCP5_CANFD01: id 0x17FE70D0, from BMC_HV, frame-length=8, can-addressing-mode=EXTENDED, can-frame-rx-behavior=CAN-FD, can-frame-tx-behavior=CAN-FD
        n pdu OBDC_SSN_BJB_Resp_XIX_HCP5_CANFD01: length=8
      frame OBDC_SSN_UI2Sens01_Req_XIX_HCP5_CANFD01: id 0x17FC71B1, to BMC_HV, frame-length=8, can-addressing-mode=EXTENDED, can-frame-rx-behavior=CAN-FD, can-frame-tx-behavior=CAN-FD
        n pdu OBDC_SSN_UI2Sens01_Req_XIX_HCP5_CANFD01: length=8
      frame OBDC_SSN_UI2Sens01_Resp_XIX_HCP5_CANFD01: id 0x17FE71B1, from BMC_HV, frame-length=8, can-addressing-mode=EXTENDED, can-frame-rx-behavior=CAN-FD, can-frame-tx-behavior=CAN-FD
        n pdu OBDC_SSN_UI2Sens01_Resp_XIX_HCP5_CANFD01: length=8
      frame OBDC_SSN_UI2Sens02_Req_XIX_HCP5_CANFD01: id 0x17FC71B2, to BMC_HV, frame-length=8, can-addressing-mode=EXTENDED, can-frame-rx-behavior=CAN-FD, can-frame-tx-behavior=CAN-FD
        n pdu OBDC_SSN_UI2Sens02_Req_XIX_HCP5_CANFD01: length=8
      frame OBDC_SSN_UI2Sens02_Resp_XIX_HCP5_CANFD01: id 0x17FE71B2, from BMC_HV, frame-length=8, can-addressing-mode=EXTENDED, can-frame-rx-behavior=CAN-FD, can-frame-tx-behavior=CAN-FD
        n pdu OBDC_SSN_UI2Sens02_Resp_XIX_HCP5_CANFD01: length=8
      frame OBDx_allOBD_Req_XIX_HCP5_CANFD01: id 0x18DB33F1, to BMC_HV, frame-length=8, can-addressing-mode=EXTENDED, can-frame-rx-behavior=CAN-FD, can-frame-tx-behavior=CAN-FD
        n pdu OBDx_allOBD_Req_XIX_HCP5_CANFD01: length=8
      frame OBDx_Hybrid_01_Req_XIX_HCP5_CANFD01: id 0x18DA05F1, to BMC_HV, frame-length=8, can-addressing-mode=EXTENDED, can-frame-rx-behavior=CAN-FD, can-frame-tx-behavior=CAN-FD
        n pdu OBDx_Hybrid_01_Req_XIX_HCP5_CANFD01: length=8
      frame OBDx_Hybrid_01_Resp_XIX_HCP5_CANFD01: id 0x18DAF105, from BMC_HV, frame-length=8, can-addressing-mode=EXTENDED, can-frame-rx-behavior=CAN-FD, can-frame-tx-behavior=CAN-FD
        n pdu OBDx_Hybrid_01_Resp_XIX_HCP5_CANFD01: length=8
      frame OBG_01_XIX_HCP5_CANFD01: id 0x12DD5518, to BMC_HV, frame-length=64, can-addressing-mode=EXTENDED, can-frame-rx-behavior=CAN-FD, can-frame-tx-behavior=CAN-FD
        pdu OBG_01_XIX_HCP5_CANFD01: length=60, transmission-mode-true-timing=cyclic-timing={time-offset=0, time-period=0.1}, unused-bit-pattern=0
          signal OBG_01_BZ_XIX_OBG_01_XIX_HCP5_CANFD01: start 8, 4 bit, little-endian, data-type-policy=OVERRIDE, i-signal-type=PRIMITIVE, init-value=0, base-type=BT_OBG_01_BZ, compu {phys=raw for raw 0..15}, range phys 0..15, raw 0..15, transfer-property=PENDING  # 4bit Botschaftszähler, wird mit jeder Sendebotschaft inkrementiert
          signal HVLE_IstSpannung_HV_XIX_OBG_01_XIX_HCP5_CANFD01: start 12, 10 bit, little-endian, data-type-policy=OVERRIDE, i-signal-type=PRIMITIVE, init-value=1022, base-type=BT_HVLE_IstSpannung_HV, invalid-value=Invalid_HVLE_IstSpannung_HV_XIX_OBG_01_XIX_HCP5_CANFD01:1023, compu {phys=raw for raw 0..1021, 1022=Cx3fe_Init (CM_HVLE_IstSpannung_HV_Cx3fe_Init), 1023=Cx3ff_Fehler (CM_HVLE_IstSpannung_HV_Cx3ff_Fehler); unit Unit_Volt}, range phys 0..1021 Unit_Volt, raw 0..1023, unit=Unit_Volt, transfer-property=PENDING, to BMC_HV(timeout 1 s)  # aktuelle DC-Ausgangsspannung des Ladegeraet
          signal HVLE_Ist_Wirkungsgrad_XIX_OBG_01_XIX_HCP5_CANFD01: start 22, 7 bit, little-endian, data-type-policy=OVERRIDE, i-signal-type=PRIMITIVE, init-value=126, base-type=BT_HVLE_Ist_Wirkungsgrad, invalid-value=Invalid_HVLE_Ist_Wirkungsgrad_XIX_OBG_01_XIX_HCP5_CANFD01:127, compu {phys=raw for raw 0..100, 126=Cx7e_Init (CM_HVLE_Ist_Wirkungsgrad_Cx7e_Init), 127=Cx7f_Fehler (CM_HVLE_Ist_Wirkungsgrad_Cx7f_Fehler); unit Unit_PerCent}, range phys 0..100 Unit_PerCent, raw 0..127, unit=Unit_PerCent, transfer-property=PENDING  # aktueller Wirkungsgrad des Ladegeraet
          signal HVLE_Netzfrequenz_EVU_XIX_OBG_01_XIX_HCP5_CANFD01: start 29, 9 bit, little-endian, data-type-policy=OVERRIDE, i-signal-type=PRIMITIVE, init-value=510, base-type=BT_HVLE_Netzfrequenz_EVU, invalid-value=Invalid_HVLE_Netzfrequenz_EVU_XIX_OBG_01_XIX_HCP5_CANFD01:511, compu {phys=raw*0.1+40 for raw 0..400, 509=Cx1fd_kein_Frequenz_erkannt (CM_HVLE_Netzfrequenz_EVU_Cx1fd_kein_Frequenz_erkannt), 510=Cx1fe_Init (CM_HVLE_Netzfrequenz_EVU_Cx1fe_Init), 511=Cx1ff_Fehler (CM_HVLE_Netzfrequenz_EVU_Cx1ff_Fehler); unit Unit_Hertz}, range phys 40..80 Unit_Hertz, raw 0..511, unit=Unit_Hertz, transfer-property=PENDING  # aktuelle AC-Netzfrequenz im Eingangskreis des Ladegeraet
          signal HVLE_Energiemenge_Laden_XIX_OBG_01_XIX_HCP5_CANFD01: start 38, 14 bit, little-endian, data-type-policy=OVERRIDE, i-signal-type=PRIMITIVE, init-value=0, base-type=BT_HVLE_Energiemenge_Laden, compu {phys=raw*40 for raw 0..16370; unit Unit_WattHour}, range phys 0..654800 Unit_WattHour, raw 0..16370, unit=Unit_WattHour, transfer-property=PENDING  # Energiemenge, die von dem Ladegeraet ueber einen definierten Zeitraum an das Fahrzeug geliefert wurde
          signal HVLE_I_istAC_Netz_L1_XIX_OBG_01_XIX_HCP5_CANFD01: start 52, 9 bit, little-endian, data-type-policy=OVERRIDE, i-signal-type=PRIMITIVE, init-value=510, base-type=BT_HVLE_I_istAC_Netz_L1, invalid-value=Invalid_HVLE_I_istAC_Netz_L1_XIX_OBG_01_XIX_HCP5_CANFD01:511, compu {phys=raw*0.1 for raw 0..508, 509=Cx1fd_nicht_vorhanden (CM_HVLE_I_istAC_Netz_L1_Cx1fd_nicht_vorhanden), 510=Cx1fe_Init (CM_HVLE_I_istAC_Netz_L1_Cx1fe_Init), 511=Cx1ff_Fehler (CM_HVLE_I_istAC_Netz_L1_Cx1ff_Fehler); unit Unit_Amper}, range phys 0..50.8 Unit_Amper, raw 0..511, unit=Unit_Amper, transfer-property=PENDING  # aktueller AC-Iststrom am Eingangskreis Phase 1 des Ladegeraet
          signal HVLE_I_istAC_Netz_L2_XIX_OBG_01_XIX_HCP5_CANFD01: start 61, 9 bit, little-endian, data-type-policy=OVERRIDE, i-signal-type=PRIMITIVE, init-value=510, base-type=BT_HVLE_I_istAC_Netz_L2, invalid-value=Invalid_HVLE_I_istAC_Netz_L2_XIX_OBG_01_XIX_HCP5_CANFD01:511, compu {phys=raw*0.1 for raw 0..508, 509=Cx1fd_nicht_vorhanden (CM_HVLE_I_istAC_Netz_L2_Cx1fd_nicht_vorhanden), 510=Cx1fe_Init (CM_HVLE_I_istAC_Netz_L2_Cx1fe_Init), 511=Cx1ff_Fehler (CM_HVLE_I_istAC_Netz_L2_Cx1ff_Fehler); unit Unit_Amper}, range phys 0..50.8 Unit_Amper, raw 0..511, unit=Unit_Amper, transfer-property=PENDING  # aktueller AC-Iststrom am Eingangskreis Phase 2 des Ladegeraet
          signal HVLE_I_istAC_Netz_L3_XIX_OBG_01_XIX_HCP5_CANFD01: start 70, 9 bit, little-endian, data-type-policy=OVERRIDE, i-signal-type=PRIMITIVE, init-value=510, base-type=BT_HVLE_I_istAC_Netz_L3, invalid-value=Invalid_HVLE_I_istAC_Netz_L3_XIX_OBG_01_XIX_HCP5_CANFD01:511, compu {phys=raw*0.1 for raw 0..508, 509=Cx1fd_nicht_vorhanden (CM_HVLE_I_istAC_Netz_L3_Cx1fd_nicht_vorhanden), 510=Cx1fe_Init (CM_HVLE_I_istAC_Netz_L3_Cx1fe_Init), 511=Cx1ff_Fehler (CM_HVLE_I_istAC_Netz_L3_Cx1ff_Fehler); unit Unit_Amper}, range phys 0..50.8 Unit_Amper, raw 0..511, unit=Unit_Amper, transfer-property=PENDING  # aktueller AC-Iststrom am Eingangskreis Phase 3 des Ladegeraet
          signal HVLE_U_istAC_Netz_L1_XIX_OBG_01_XIX_HCP5_CANFD01: start 79, 9 bit, little-endian, data-type-policy=OVERRIDE, i-signal-type=PRIMITIVE, init-value=510, base-type=BT_HVLE_U_istAC_Netz_L1, invalid-value=Invalid_HVLE_U_istAC_Netz_L1_XIX_OBG_01_XIX_HCP5_CANFD01:511, compu {phys=raw for raw 0..508, 509=Cx1fd_nicht_vorhanden (CM_HVLE_U_istAC_Netz_L1_Cx1fd_nicht_vorhanden), 510=Cx1fe_Init (CM_HVLE_U_istAC_Netz_L1_Cx1fe_Init), 511=Cx1ff_Fehler (CM_HVLE_U_istAC_Netz_L1_Cx1ff_Fehler); unit Unit_Volt}, range phys 0..508 Unit_Volt, raw 0..511, unit=Unit_Volt, transfer-property=PENDING  # aktuelle AC-Istspannung am Eingangskreis Phase 1 des Ladegeraet
          signal HVLE_U_istAC_Netz_L2_XIX_OBG_01_XIX_HCP5_CANFD01: start 88, 9 bit, little-endian, data-type-policy=OVERRIDE, i-signal-type=PRIMITIVE, init-value=510, base-type=BT_HVLE_U_istAC_Netz_L2, invalid-value=Invalid_HVLE_U_istAC_Netz_L2_XIX_OBG_01_XIX_HCP5_CANFD01:511, compu {phys=raw for raw 0..508, 509=Cx1fd_nicht_vorhanden (CM_HVLE_U_istAC_Netz_L2_Cx1fd_nicht_vorhanden), 510=Cx1fe_Init (CM_HVLE_U_istAC_Netz_L2_Cx1fe_Init), 511=Cx1ff_Fehler (CM_HVLE_U_istAC_Netz_L2_Cx1ff_Fehler); unit Unit_Volt}, range phys 0..508 Unit_Volt, raw 0..511, unit=Unit_Volt, transfer-property=PENDING  # aktuelle AC-Istspannung am Eingangskreis Phase 2 des Ladegeraet
          signal HVLE_U_istAC_Netz_L3_XIX_OBG_01_XIX_HCP5_CANFD01: start 97, 9 bit, little-endian, data-type-policy=OVERRIDE, i-signal-type=PRIMITIVE, init-value=510, base-type=BT_HVLE_U_istAC_Netz_L3, invalid-value=Invalid_HVLE_U_istAC_Netz_L3_XIX_OBG_01_XIX_HCP5_CANFD01:511, compu {phys=raw for raw 0..508, 509=Cx1fd_nicht_vorhanden (CM_HVLE_U_istAC_Netz_L3_Cx1fd_nicht_vorhanden), 510=Cx1fe_Init (CM_HVLE_U_istAC_Netz_L3_Cx1fe_Init), 511=Cx1ff_Fehler (CM_HVLE_U_istAC_Netz_L3_Cx1ff_Fehler); unit Unit_Volt}, range phys 0..508 Unit_Volt, raw 0..511, unit=Unit_Volt, transfer-property=PENDING  # aktuelle AC-Istspannung am Eingangskreis Phase 3 des Ladegeraet
          signal HVLE_OBG_DC_MaxStrom_XIX_OBG_01_XIX_HCP5_CANFD01: start 106, 11 bit, little-endian, data-type-policy=OVERRIDE, i-signal-type=PRIMITIVE, init-value=2046, base-type=BT_HVLE_OBG_DC_MaxStrom, invalid-value=Invalid_HVLE_OBG_DC_MaxStrom_XIX_OBG_01_XIX_HCP5_CANFD01:2047, compu {phys=raw*0.1 for raw 0..2045, 2046=Cx7fe_Init (CM_HVLE_OBG_DC_MaxStrom_Cx7fe_Init), 2047=Cx7ff_Fehler (CM_HVLE_OBG_DC_MaxStrom_Cx7ff_Fehler); unit Unit_Amper}, range phys 0..204.5 Unit_Amper, raw 0..2047, unit=Unit_Amper, transfer-property=PENDING  # maximaler Strom den das Ladegeraet bei der aktuellen Spannungslage und des vorgegebenen AC-Aufnahmenstrom stellen kann
          signal HVLE_OBG_DC_IstStrom_XIX_OBG_01_XIX_HCP5_CANFD01: start 117, 11 bit, little-endian, data-type-policy=OVERRIDE, i-signal-type=PRIMITIVE, init-value=2046, base-type=BT_HVLE_OBG_DC_IstStrom, invalid-value=Invalid_HVLE_OBG_DC_IstStrom_XIX_OBG_01_XIX_HCP5_CANFD01:2047, compu {phys=raw*0.1 for raw 0..2045, 2046=Cx7fe_Init (CM_HVLE_OBG_DC_IstStrom_Cx7fe_Init), 2047=Cx7ff_Fehler (CM_HVLE_OBG_DC_IstStrom_Cx7ff_Fehler); unit Unit_Amper}, range phys 0..204.5 Unit_Amper, raw 0..2047, unit=Unit_Amper, transfer-property=PENDING  # aktueller Iststrom des OCC
          signal HVLE_Netzmodus_XIX_OBG_01_XIX_HCP5_CANFD01: start 128, 4 bit, little-endian, data-type-policy=OVERRIDE, i-signal-type=PRIMITIVE, init-value=0, base-type=BT_HVLE_Netzmodus, invalid-value=Invalid_HVLE_Netzmodus_XIX_OBG_01_XIX_HCP5_CANFD01:15, compu {0=Cx0_Init (CM_HVLE_Netzmodus_Cx0_Init), 1=Cx1_no_grid (CM_HVLE_Netzmodus_Cx1_no_grid), 2=Cx2_one_phase_L1 (CM_HVLE_Netzmodus_Cx2_one_phase_L1), 3=Cx3_one_phase_not_L1 (CM_HVLE_Netzmodus_Cx3_one_phase_not_L1), 4=Cx4_two_phase (CM_HVLE_Netzmodus_Cx4_two_phase), 5=Cx5_three_phase (CM_HVLE_Netzmodus_Cx5_three_phase), 6=Cx6_delta_grid (CM_HVLE_Netzmodus_Cx6_delta_grid), 7=Cx7_parallel_phases (CM_HVLE_Netzmodus_Cx7_parallel_phases), 15=Cxf_Fehler (CM_HVLE_Netzmodus_Cxf_Fehler)}, range raw 0..15, transfer-property=PENDING  # Das Ladegeraet signalisiert hier den aktuellen Netzmodus. (1-phasig, 2-phasig, 3phasig, usw.)
          signal HVLE_Derating_Temperatur_XIX_OBG_01_XIX_HCP5_CANFD01: start 132, 1 bit, little-endian, data-type-policy=OVERRIDE, i-signal-type=PRIMITIVE, init-value=0, base-type=BT_HVLE_Derating_Temperatur, compu {0=Cx0_kein_Derating_aktiv (CM_HVLE_Derating_Temperatur_Cx0_kein_Derating_aktiv), 1=Cx1_Derating_aktiv (CM_HVLE_Derating_Temperatur_Cx1_Derating_aktiv)}, range raw 0..1, transfer-property=PENDING  # Derating-Status aufgrund von Temperaturbegrenzungen des Ladegeraet
          signal HVLE_OBG_IstModus_XIX_OBG_01_XIX_HCP5_CANFD01: start 133, 3 bit, little-endian, data-type-policy=OVERRIDE, i-signal-type=PRIMITIVE, init-value=6, base-type=BT_HVLE_OBG_IstModus, invalid-value=Invalid_HVLE_OBG_IstModus_XIX_OBG_01_XIX_HCP5_CANFD01:7, compu {0=Cx0_Standby (CM_HVLE_OBG_IstModus_Cx0_Standby), 1=Cx1_Netzladung_aktiv (CM_HVLE_OBG_IstModus_Cx1_Netzladung_aktiv), 2=Cx2_Rueckspeisung_aktiv (CM_HVLE_OBG_IstModus_Cx2_Rueckspeisung_aktiv), 3=Cx3_Vorladen_aktiv (CM_HVLE_OBG_IstModus_Cx3_Vorladen_aktiv), 4=Cx4_Vorladespannung_erreicht_und_halten (CM_HVLE_OBG_IstModus_Cx4_Vorladespannung_erreicht_und_halten), 5=Cx5_reserve (CM_HVLE_OBG_IstModus_Cx5_reserve), 6=Cx6_Init (CM_HVLE_OBG_IstModus_Cx6_Init), 7=Cx7_Fehler (CM_HVLE_OBG_IstModus_Cx7_Fehler)}, range raw 0..7, transfer-property=PENDING, to BMC_HV(timeout 1 s)  # aktueller Funktionszustand des Ladegeraet
          signal HVLE_OBG_Warnzustand_XIX_OBG_01_XIX_HCP5_CANFD01: start 136, 4 bit, little-endian, data-type-policy=OVERRIDE, i-signal-type=PRIMITIVE, init-value=0, base-type=BT_HVLE_OBG_Warnzustand, compu {0=Cx0_keine_Warnung_aktiv (CM_HVLE_OBG_Warnzustand_Cx0_keine_Warnung_aktiv), 1=Cx1_Leistungsbegrenzung_maxDCAusgangsstrom (CM_HVLE_OBG_Warnzustand_Cx1_Leistungsbegrenzung_maxDCAusgangsstrom), 2=Cx2_Leistungsbegrenzung_maxDCAusgangsspannung (CM_HVLE_OBG_Warnzustand_Cx2_Leistungsbegrenzung_maxDCAusgangsspannung), 3=Cx3_Leistungsbegrenzung_Spanungsnetz (CM_HVLE_OBG_Warnzustand_Cx3_Leistungsbegrenzung_Spanungsnetz), 4=Cx4_Ueberspannung (CM_HVLE_OBG_Warnzustand_Cx4_Ueberspannung), 5=Cx5_minStromLimit (CM_HVLE_OBG_Warnzustand_Cx5_minStromLimit), 6=Cx6_Ueberstrom_aktuell (CM_HVLE_OBG_Warnzustand_Cx6_Ueberstrom_aktuell), 7=Cx7_Ueberstrom_Ladegeraet (CM_HVLE_OBG_Warnzustand_Cx7_Ueberstrom_Ladegeraet), 8=Cx8_Netzausfall (CM_HVLE_OBG_Warnzustand_Cx8_Netzausfall), 9=Cx9_Komponentenschutz_aktiv (CM_HVLE_OBG_Warnzustand_Cx9_Komponentenschutz_aktiv)}, range raw 0..9, transfer-property=PENDING  # Zeigt an, ob eine Warnung für das Ladegerät aufgetreten ist.
          signal HVLE_OBG_Fehlerstatus_XIX_OBG_01_XIX_HCP5_CANFD01: start 140, 1 bit, little-endian, data-type-policy=OVERRIDE, i-signal-type=PRIMITIVE, init-value=0, base-type=BT_HVLE_OBG_Fehlerstatus, compu {0=Cx0_kein_Fehler_aktiv (CM_HVLE_OBG_Fehlerstatus_Cx0_kein_Fehler_aktiv), 1=Cx1_Fehler_aktiv_Laden_beendet (CM_HVLE_OBG_Fehlerstatus_Cx1_Fehler_aktiv_Laden_beendet)}, range raw 0..1, transfer-property=PENDING  # Gibt an, ob bei dem Ladegerät ein Fehler anliegt.
          signal HVLE_OBG_Fehlerstrom_XIX_OBG_01_XIX_HCP5_CANFD01: start 143, 1 bit, little-endian, data-type-policy=OVERRIDE, i-signal-type=PRIMITIVE, init-value=0, base-type=BT_HVLE_OBG_Fehlerstrom, compu {0=Cx0_Kein_Fehlerstrom (CM_HVLE_OBG_Fehlerstrom_Cx0_Kein_Fehlerstrom), 1=Cx1_Fehlerstrom (CM_HVLE_OBG_Fehlerstrom_Cx1_Fehlerstrom)}, range raw 0..1, transfer-property=PENDING  # Fehlerstrom der durch einen Isolationsfehler (z.B. schadhafte Isolierung, Berührung) vom Betriebsmittel zum Erdungssystem abfließt. Dies können hier AC- oder DC-Ströme sein.
          signal HVLE_OBG_ACDC_IstLeistung_XIX_OBG_01_XIX_HCP5_CANFD01: start 144, 11 bit, little-endian, data-type-policy=OVERRIDE, i-signal-type=PRIMITIVE, init-value=2046, base-type=BT_HVLE_OBG_ACDC_IstLeistung, invalid-value=Invalid_HVLE_OBG_ACDC_IstLeistung_XIX_OBG_01_XIX_HCP5_CANFD01:2047, compu {phys=raw*25 for raw 0..1800, 2046=Cx7fe_Init (CM_HVLE_OBG_ACDC_IstLeistung_Cx7fe_Init), 2047=Cx7ff_Fehler (CM_HVLE_OBG_ACDC_IstLeistung_Cx7ff_Fehler); unit Unit_Watt}, range phys 0..45000 Unit_Watt, raw 0..2047, unit=Unit_Watt, transfer-property=PENDING  # Aktuelle Ist-Leistung des Onboardgleichrichters nach der AC-DC-Umwandlung inkl. Verluste des Wirkungsgrades
          signal HVLE_OBG_ACDC_MaxLeistung_XIX_OBG_01_XIX_HCP5_CANFD01: start 155, 11 bit, little-endian, data-type-policy=OVERRIDE, i-signal-type=PRIMITIVE, init-value=2046, base-type=BT_HVLE_OBG_ACDC_MaxLeistung, invalid-value=Invalid_HVLE_OBG_ACDC_MaxLeistung_XIX_OBG_01_XIX_HCP5_CANFD01:2047, compu {phys=raw*25 for raw 0..1800, 2046=Cx7fe_Init (CM_HVLE_OBG_ACDC_MaxLeistung_Cx7fe_Init), 2047=Cx7ff_Fehler (CM_HVLE_OBG_ACDC_MaxLeistung_Cx7ff_Fehler); unit Unit_Watt}, range phys 0..45000 Unit_Watt, raw 0..2047, unit=Unit_Watt, transfer-property=PENDING  # Maximale mögliche Leistung des Onboardgleichrichters nach der AC-DC-Umwandlung inkl. Verluste des Wirkungsgrades
          signal HVLE_OBG_AC_maxStrom_XIX_OBG_01_XIX_HCP5_CANFD01: start 166, 10 bit, little-endian, data-type-policy=OVERRIDE, i-signal-type=PRIMITIVE, init-value=1022, base-type=BT_HVLE_OBG_AC_maxStrom, invalid-value=Invalid_HVLE_OBG_AC_maxStrom_XIX_OBG_01_XIX_HCP5_CANFD01:1023, compu {phys=raw*0.1 for raw 0..1000, 1022=Cx3fe_Init (CM_HVLE_OBG_AC_maxStrom_Cx3fe_Init), 1023=Cx3ff_Fehler (CM_HVLE_OBG_AC_maxStrom_Cx3ff_Fehler); unit Unit_Amper}, range phys 0..100 Unit_Amper, raw 0..1023, unit=Unit_Amper, transfer-property=PENDING  # auteiltechnischer Grenzwert des maximalen Stroms pro Phase welches vom Ladegerät unterstützt wird.
          signal HVLE_OBG_AC_maxSpannung_XIX_OBG_01_XIX_HCP5_CANFD01: start 176, 10 bit, little-endian, data-type-policy=OVERRIDE, i-signal-type=PRIMITIVE, init-value=1022, base-type=BT_HVLE_OBG_AC_maxSpannung, invalid-value=Invalid_HVLE_OBG_AC_maxSpannung_XIX_OBG_01_XIX_HCP5_CANFD01:1023, compu {phys=raw for raw 0..1000, 1022=Cx3fe_Init (CM_HVLE_OBG_AC_maxSpannung_Cx3fe_Init), 1023=Cx3ff_Fehler (CM_HVLE_OBG_AC_maxSpannung_Cx3ff_Fehler); unit Unit_Volt}, range phys 0..1000 Unit_Volt, raw 0..1023, unit=Unit_Volt, transfer-property=PENDING  # Bauteiltechnischer Grenzwert der maximalen nominellen Spannung gemessen zwischen Phase und Neutral.
          signal HVLE_AnzahlVerwendeterPhasen_XIX_OBG_01_XIX_HCP5_CANFD01: start 186, 2 bit, little-endian, data-type-policy=OVERRIDE, i-signal-type=PRIMITIVE, init-value=0, base-type=BT_HVLE_AnzahlVerwendeterPhasen, invalid-value=Invalid_HVLE_AnzahlVerwendeterPhasen_XIX_OBG_01_XIX_HCP5_CANFD01:3, compu {0=Cx0_eine_phase_verwendet (CM_HVLE_AnzahlVerwendeterPhasen_Cx0_eine_phase_verwendet), 1=Cx1_zwei_phasen_verwendet (CM_HVLE_AnzahlVerwendeterPhasen_Cx1_zwei_phasen_verwendet), 2=Cx2_drei_phasen_verwendet (CM_HVLE_AnzahlVerwendeterPhasen_Cx2_drei_phasen_verwendet), 3=Cx3_Fehler (CM_HVLE_AnzahlVerwendeterPhasen_Cx3_Fehler)}, range raw 0..3, transfer-property=PENDING  # Gibt die Anzahl der verwendeten Phasen für das AC Laden an
          signal HVLE_AsymmetrischLadenMoeglich_XIX_OBG_01_XIX_HCP5_CANFD01: start 188, 1 bit, little-endian, data-type-policy=OVERRIDE, i-signal-type=PRIMITIVE, init-value=0, base-type=BT_HVLE_AsymmetrischLadenMoeglich, compu {0=Cx0_moeglich (CM_HVLE_AsymmetrischLadenMoeglich_Cx0_moeglich), 1=Cx1_nicht_moeglich (CM_HVLE_AsymmetrischLadenMoeglich_Cx1_nicht_moeglich)}, range raw 0..1, transfer-property=PENDING  # Information ob das Ladegerät ein asymetrisches Laden bauartbedingt unterstützt
          signal HVLE_OBG_Typ_verbaut_XIX_OBG_01_XIX_HCP5_CANFD01: start 189, 3 bit, little-endian, data-type-policy=OVERRIDE, i-signal-type=PRIMITIVE, init-value=7, base-type=BT_HVLE_OBG_Typ_verbaut, compu {0=Cx0_IPB_galvanisch_nichtGetrennt (CM_HVLE_OBG_Typ_verbaut_Cx0_IPB_galvanisch_nichtGetrennt), 1=Cx1_SAC (CM_HVLE_OBG_Typ_verbaut_Cx1_SAC), 2=Cx2_OCC (CM_HVLE_OBG_Typ_verbaut_Cx2_OCC), 3=Cx3_IPB_galvanisch_getrennt (CM_HVLE_OBG_Typ_verbaut_Cx3_IPB_galvanisch_getrennt), 4=Cx4_SAC_galvanisch_getrennt (CM_HVLE_OBG_Typ_verbaut_Cx4_SAC_galvanisch_getrennt), 5=Cx5_Reserve (CM_HVLE_OBG_Typ_verbaut_Cx5_Reserve), 6=Cx6_Reserve (CM_HVLE_OBG_Typ_verbaut_Cx6_Reserve), 7=Cx7_Init (CM_HVLE_OBG_Typ_verbaut_Cx7_Init)}, range raw 0..7, transfer-property=PENDING  # Typ des verbauten Onboard-Gleichrichters
          signal HVLE_PE_Monitor_XIX_OBG_01_XIX_HCP5_CANFD01: start 192, 3 bit, little-endian, data-type-policy=OVERRIDE, i-signal-type=PRIMITIVE, init-value=0, base-type=BT_HVLE_PE_Monitor, invalid-value=Invalid_HVLE_PE_Monitor_XIX_OBG_01_XIX_HCP5_CANFD01:7, compu {0=Cx0_keine_PE_Messung_aktiv (CM_HVLE_PE_Monitor_Cx0_keine_PE_Messung_aktiv), 1=Cx1_PE_erkannt (CM_HVLE_PE_Monitor_Cx1_PE_erkannt), 2=Cx2_IT_Netz_erkannt (CM_HVLE_PE_Monitor_Cx2_IT_Netz_erkannt) (IT-Netz_erkannt), 3=Cx3_PE_nicht_erkannt (CM_HVLE_PE_Monitor_Cx3_PE_nicht_erkannt), 7=Cx7_Fehler (CM_HVLE_PE_Monitor_Cx7_Fehler)}, range raw 0..7, transfer-property=PENDING  # Messung des PE-Leiters der Infrastruktur bei galvanisch nicht getrennten Onboard Gleichrichtern.
      frame ORU_01_XIX_HCP5_CANFD01: id 0x1A555548, to BMC_HV, frame-length=8, can-addressing-mode=EXTENDED, can-frame-rx-behavior=CAN-FD, can-frame-tx-behavior=CAN-FD
        pdu ORU_01_XIX_HCP5_CANFD01: length=8, transmission-mode-true-timing=cyclic-timing={time-offset=0, time-period=0.5}, unused-bit-pattern=0
          signal ORU_AgLgtSdsl_XIX_ORU_01_XIX_HCP5_CANFD01: start 12, 11 bit, little-endian, data-type-policy=OVERRIDE, i-signal-type=PRIMITIVE, init-value=2001, base-type=BT_ORU_AgLgtSdsl, invalid-value=Invalid_ORU_AgLgtSdsl_XIX_ORU_01_XIX_HCP5_CANFD01:2002, compu {phys=raw*0.1-100 for raw 0..2000, 2001=Cx7d1_InitWert (CM_ORU_AgLgtSdsl_Cx7d1_InitWert), 2002=Cx7d2_Fehler (CM_ORU_AgLgtSdsl_Cx7d2_Fehler); unit Unit_PerCent}, range phys -100..100 Unit_PerCent, raw 0..2002, unit=Unit_PerCent, transfer-property=PENDING  # Vehicle inclination angle at standstill in percent
          signal ORU_Status_XIX_ORU_01_XIX_HCP5_CANFD01: start 61, 3 bit, little-endian, data-type-policy=OVERRIDE, i-signal-type=PRIMITIVE, init-value=0, base-type=BT_ORU_Status, compu {0=Cx0_IDLE (CM_ORU_Status_Cx0_IDLE), 1=Cx1_PENDING (CM_ORU_Status_Cx1_PENDING), 2=Cx2_PREPARATION (CM_ORU_Status_Cx2_PREPARATION), 3=Cx3_PREPARATION_HV (CM_ORU_Status_Cx3_PREPARATION_HV), 4=Cx4_RUNNING (CM_ORU_Status_Cx4_RUNNING), 5=Cx5_RUNNING_HV (CM_ORU_Status_Cx5_RUNNING_HV), 6=Cx6_PENDING_NOTREADY (CM_ORU_Status_Cx6_PENDING_NOTREADY), 7=Cx7_FAILURE_POWERTRAIN_DISABLED (CM_ORU_Status_Cx7_FAILURE_POWERTRAIN_DISABLED)}, range raw 0..7, transfer-property=PENDING, to BMC_HV(timeout 5 s)  # Verteilung des internen ORU Zustandes
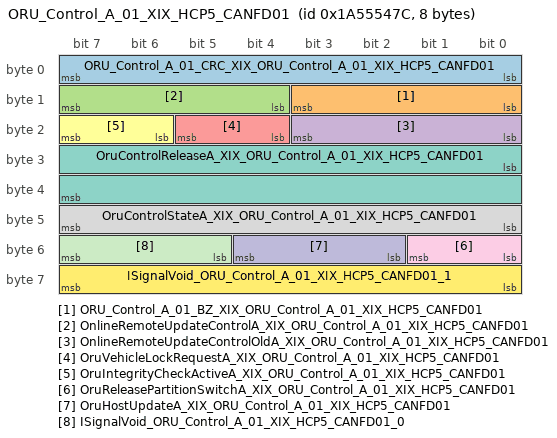
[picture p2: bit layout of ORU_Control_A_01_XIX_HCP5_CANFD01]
      frame ORU_Control_A_01_XIX_HCP5_CANFD01: id 0x1A55547C, to BMC_HV, frame-length=8, can-addressing-mode=EXTENDED, can-frame-rx-behavior=CAN-FD, can-frame-tx-behavior=CAN-FD
        pdu ORU_Control_A_01_XIX_HCP5_CANFD01_E2E: length=8, transmission-mode-true-timing=event-controlled-timing={number-of-repetitions=0, repetition-period=0}, unused-bit-pattern=0  # Fuer die Botschaft ist das Cyclic-Timing 0.5 zu verwenden.
          signal ORU_Control_A_01_CRC_XIX_ORU_Control_A_01_XIX_HCP5_CANFD01: start 0, 8 bit, little-endian, data-type-policy=OVERRIDE, i-signal-type=PRIMITIVE, init-value=0, base-type=BT_ORU_Control_A_01_CRC, compu {phys=raw for raw 0..255}, range phys 0..255, raw 0..255, to BMC_HV(timeout 5 s)
          signal ORU_Control_A_01_BZ_XIX_ORU_Control_A_01_XIX_HCP5_CANFD01: start 8, 4 bit, little-endian, data-type-policy=OVERRIDE, i-signal-type=PRIMITIVE, init-value=0, base-type=BT_ORU_Control_A_01_BZ, compu {phys=raw for raw 0..15}, range phys 0..15, raw 0..15, to BMC_HV(timeout 5 s)
          signal OnlineRemoteUpdateControlA_XIX_ORU_Control_A_01_XIX_HCP5_CANFD01: start 12, 4 bit, little-endian, data-type-policy=OVERRIDE, i-signal-type=PRIMITIVE, init-value=0, base-type=BT_OnlineRemoteUpdateControlA, invalid-value=Invalid_OnlineRemoteUpdateControlA_XIX_ORU_Control_A_01_XIX_HCP5_CANFD01:15, compu {0=Cx0_IDLE (CM_OnlineRemoteUpdateControlA_Cx0_IDLE), 1=Cx1_PENDING (CM_OnlineRemoteUpdateControlA_Cx1_PENDING), 2=Cx2_PREPARATION (CM_OnlineRemoteUpdateControlA_Cx2_PREPARATION), 3=Cx3_PREPARATION_HV (CM_OnlineRemoteUpdateControlA_Cx3_PREPARATION_HV), 4=Cx4_RUNNING (CM_OnlineRemoteUpdateControlA_Cx4_RUNNING), 5=Cx5_RUNNING_HV (CM_OnlineRemoteUpdateControlA_Cx5_RUNNING_HV), 6=Cx6_PENDING_NOTREADY (CM_OnlineRemoteUpdateControlA_Cx6_PENDING_NOTREADY), 7=Cx7_OTA_FAILURE_POWERTRAIN_DISABLED (CM_OnlineRemoteUpdateControlA_Cx7_OTA_FAILURE_POWERTRAIN_DISABLED), 8=Cx8_FUNCTIONAL_SAFETY_RELEASED (CM_OnlineRemoteUpdateControlA_Cx8_FUNCTIONAL_SAFETY_RELEASED), 9=Cx9_PREPARATION_SG (CM_OnlineRemoteUpdateControlA_Cx9_PREPARATION_SG), 15=Cxf_Fehler (CM_OnlineRemoteUpdateControlA_Cxf_Fehler)}, range raw 0..15, to BMC_HV(timeout 5 s)  # Current state of the oru control component
          signal OnlineRemoteUpdateControlOldA_XIX_ORU_Control_A_01_XIX_HCP5_CANFD01: start 16, 4 bit, little-endian, data-type-policy=OVERRIDE, i-signal-type=PRIMITIVE, init-value=0, base-type=BT_OnlineRemoteUpdateControlOldA, invalid-value=Invalid_OnlineRemoteUpdateControlOldA_XIX_ORU_Control_A_01_XIX_HCP5_CANFD01:15, compu {0=Cx0_IDLE (CM_OnlineRemoteUpdateControlOldA_Cx0_IDLE), 1=Cx1_PENDING (CM_OnlineRemoteUpdateControlOldA_Cx1_PENDING), 2=Cx2_PREPARATION (CM_OnlineRemoteUpdateControlOldA_Cx2_PREPARATION), 3=Cx3_PREPARATION_HV (CM_OnlineRemoteUpdateControlOldA_Cx3_PREPARATION_HV), 4=Cx4_RUNNING (CM_OnlineRemoteUpdateControlOldA_Cx4_RUNNING), 5=Cx5_RUNNING_HV (CM_OnlineRemoteUpdateControlOldA_Cx5_RUNNING_HV), 6=Cx6_PENDING_NOTREADY (CM_OnlineRemoteUpdateControlOldA_Cx6_PENDING_NOTREADY), 7=Cx7_OTA_FAILURE_POWERTRAIN_DISABLED (CM_OnlineRemoteUpdateControlOldA_Cx7_OTA_FAILURE_POWERTRAIN_DISABLED), 8=Cx8_FUNCTIONAL_SAFETY_RELEASE (CM_OnlineRemoteUpdateControlOldA_Cx8_FUNCTIONAL_SAFETY_RELEASE), 9=Cx9_PREPARATION_SG (CM_OnlineRemoteUpdateControlOldA_Cx9_PREPARATION_SG), 15=Cxf_Fehler (CM_OnlineRemoteUpdateControlOldA_Cxf_Fehler)}, range raw 0..15, to BMC_HV(timeout 5 s)  # Old state of the ORU control A signal (state 5 cycles before)
          signal OruVehicleLockRequestA_XIX_ORU_Control_A_01_XIX_HCP5_CANFD01: start 20, 2 bit, little-endian, data-type-policy=OVERRIDE, i-signal-type=PRIMITIVE, init-value=0, base-type=BT_OruVehicleLockRequestA, invalid-value=Invalid_OruVehicleLockRequestA_XIX_ORU_Control_A_01_XIX_HCP5_CANFD01:3, compu {0=Cx0_Init (CM_OruVehicleLockRequestA_Cx0_Init), 1=Cx1_Lock (CM_OruVehicleLockRequestA_Cx1_Lock), 2=Cx2_Release (CM_OruVehicleLockRequestA_Cx2_Release), 3=Cx3_Fehler (CM_OruVehicleLockRequestA_Cx3_Fehler)}, range raw 0..3  # Releases or locks one or more ECUs with their specific functions (e.g. immobilizer)
          signal OruIntegrityCheckActiveA_XIX_ORU_Control_A_01_XIX_HCP5_CANFD01: start 22, 2 bit, little-endian, data-type-policy=OVERRIDE, i-signal-type=PRIMITIVE, init-value=0, base-type=BT_OruIntegrityCheckActiveA, invalid-value=Invalid_OruIntegrityCheckActiveA_XIX_ORU_Control_A_01_XIX_HCP5_CANFD01:3, compu {0=Cx0_Init (CM_OruIntegrityCheckActiveA_Cx0_Init), 1=Cx1_Inactive (CM_OruIntegrityCheckActiveA_Cx1_Inactive), 2=Cx2_Active (CM_OruIntegrityCheckActiveA_Cx2_Active), 3=Cx3_Fehler (CM_OruIntegrityCheckActiveA_Cx3_Fehler)}, range raw 0..3  # Signal to indicate if the integrity check is active
          signal OruControlReleaseA_XIX_ORU_Control_A_01_XIX_HCP5_CANFD01: start 24, 16 bit, little-endian, data-type-policy=OVERRIDE, i-signal-type=PRIMITIVE, init-value=0, base-type=BT_OruControlReleaseA, compu {phys=raw for raw 0..65535; unit Unit_None}, range phys 0..65535 Unit_None, raw 0..65535, unit=Unit_None, to BMC_HV(timeout 5 s)  # Release of an ecu to be flashed by oru
          signal OruControlStateA_XIX_ORU_Control_A_01_XIX_HCP5_CANFD01: start 40, 8 bit, little-endian, data-type-policy=OVERRIDE, i-signal-type=PRIMITIVE, init-value=0, base-type=BT_OruControlStateA, invalid-value=Invalid_OruControlStateA_XIX_ORU_Control_A_01_XIX_HCP5_CANFD01:129, compu {0=Cx0_Idle (CM_OruControlStateA_Cx0_Idle), 1=Cx1_Check (CM_OruControlStateA_Cx1_Check), 3=Cx3_DataPresent (CM_OruControlStateA_Cx3_DataPresent), 7=Cx7_LockActive (CM_OruControlStateA_Cx7_LockActive), 15=Cxf_Running (CM_OruControlStateA_Cxf_Running), 31=Cx1f_Save (CM_OruControlStateA_Cx1f_Save), 63=Cx3f_Done (CM_OruControlStateA_Cx3f_Done), 65=Cx41_Fail (CM_OruControlStateA_Cx41_Fail), 129=Cx81_Fehler (CM_OruControlStateA_Cx81_Fehler)}, range raw 0..129  # Internal State of ORU Control component.
          signal OruReleasePartitionSwitchA_XIX_ORU_Control_A_01_XIX_HCP5_CANFD01: start 48, 2 bit, little-endian, data-type-policy=OVERRIDE, i-signal-type=PRIMITIVE, init-value=0, base-type=BT_OruReleasePartitionSwitchA, invalid-value=Invalid_OruReleasePartitionSwitchA_XIX_ORU_Control_A_01_XIX_HCP5_CANFD01:3, compu {0=Cx0_Init (CM_OruReleasePartitionSwitchA_Cx0_Init), 1=Cx1_Lock (CM_OruReleasePartitionSwitchA_Cx1_Lock), 2=Cx2_Release (CM_OruReleasePartitionSwitchA_Cx2_Release), 3=Cx3_Fehler (CM_OruReleasePartitionSwitchA_Cx3_Fehler)}, range raw 0..3  # Release to switch the partition in case of an A/B partition update
          signal OruHostUpdateA_XIX_ORU_Control_A_01_XIX_HCP5_CANFD01: start 50, 3 bit, little-endian, data-type-policy=OVERRIDE, i-signal-type=PRIMITIVE, init-value=0, base-type=BT_OruHostUpdateA, invalid-value=Invalid_OruHostUpdateA_XIX_ORU_Control_A_01_XIX_HCP5_CANFD01:4, compu {0=Cx0_Init (CM_OruHostUpdateA_Cx0_Init), 1=Cx1_HostControl1 (CM_OruHostUpdateA_Cx1_HostControl1), 2=Cx2_HostControl2 (CM_OruHostUpdateA_Cx2_HostControl2), 3=Cx3_HostControlOther (CM_OruHostUpdateA_Cx3_HostControlOther), 4=Cx4_Fehler (CM_OruHostUpdateA_Cx4_Fehler)}, range raw 0..4  # Releases an update of an critical funcion's host (due to functional safety)
          signal ISignalVoid_ORU_Control_A_01_XIX_HCP5_CANFD01_0: start 53, 3 bit, little-endian, system signal SignalVoid_ORU_Control_A_01_0, data-type-policy=OVERRIDE, i-signal-type=PRIMITIVE, base-type=BT_SignalVoid
          signal ISignalVoid_ORU_Control_A_01_XIX_HCP5_CANFD01_1: start 56, 8 bit, little-endian, system signal SignalVoid_ORU_Control_A_01_1, data-type-policy=OVERRIDE, i-signal-type=PRIMITIVE, base-type=BT_SignalVoid
          mapping SG_ORU_Control_A_01_XIX_HCP5_CANFD01: i-signal-group=SG_ORU_Control_A_01_XIX_HCP5_CANFD01, transfer-property=TRIGGERED-WITHOUT-REPETITION
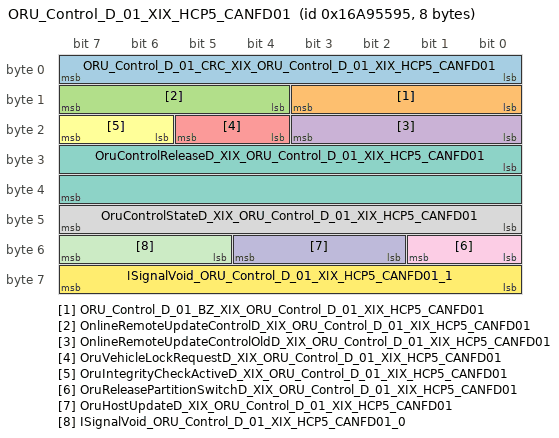
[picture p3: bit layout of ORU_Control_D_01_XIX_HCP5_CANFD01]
      frame ORU_Control_D_01_XIX_HCP5_CANFD01: id 0x16A95595, to BMC_HV, frame-length=8, can-addressing-mode=EXTENDED, can-frame-rx-behavior=CAN-FD, can-frame-tx-behavior=CAN-FD
        pdu ORU_Control_D_01_XIX_HCP5_CANFD01_E2E: length=8, transmission-mode-true-timing=event-controlled-timing={number-of-repetitions=0, repetition-period=0}, unused-bit-pattern=0  # Fuer die Botschaft ist das Cyclic-Timing 0.32 zu verwenden.
          signal ORU_Control_D_01_CRC_XIX_ORU_Control_D_01_XIX_HCP5_CANFD01: start 0, 8 bit, little-endian, data-type-policy=OVERRIDE, i-signal-type=PRIMITIVE, init-value=0, base-type=BT_ORU_Control_D_01_CRC, compu {phys=raw for raw 0..255}, range phys 0..255, raw 0..255, to BMC_HV(timeout 3.2 s)
          signal ORU_Control_D_01_BZ_XIX_ORU_Control_D_01_XIX_HCP5_CANFD01: start 8, 4 bit, little-endian, data-type-policy=OVERRIDE, i-signal-type=PRIMITIVE, init-value=0, base-type=BT_ORU_Control_D_01_BZ, compu {phys=raw for raw 0..15}, range phys 0..15, raw 0..15, to BMC_HV(timeout 3.2 s)
          signal OnlineRemoteUpdateControlD_XIX_ORU_Control_D_01_XIX_HCP5_CANFD01: start 12, 4 bit, little-endian, data-type-policy=OVERRIDE, i-signal-type=PRIMITIVE, init-value=0, base-type=BT_OnlineRemoteUpdateControlD, invalid-value=Invalid_OnlineRemoteUpdateControlD_XIX_ORU_Control_D_01_XIX_HCP5_CANFD01:15, compu {0=Cx0_IDLE (CM_OnlineRemoteUpdateControlD_Cx0_IDLE), 1=Cx1_PENDING (CM_OnlineRemoteUpdateControlD_Cx1_PENDING), 2=Cx2_PREPARATION (CM_OnlineRemoteUpdateControlD_Cx2_PREPARATION), 3=Cx3_PREPARATION_HV (CM_OnlineRemoteUpdateControlD_Cx3_PREPARATION_HV), 4=Cx4_RUNNING (CM_OnlineRemoteUpdateControlD_Cx4_RUNNING), 5=Cx5_RUNNING_HV (CM_OnlineRemoteUpdateControlD_Cx5_RUNNING_HV), 6=Cx6_PENDING_NOTREADY (CM_OnlineRemoteUpdateControlD_Cx6_PENDING_NOTREADY), 7=Cx7_OTA_FAILURE_POWERTRAIN_DISABLED (CM_OnlineRemoteUpdateControlD_Cx7_OTA_FAILURE_POWERTRAIN_DISABLED), 8=Cx8_FUNCTIONAL_SAFETY_RELEASE (CM_OnlineRemoteUpdateControlD_Cx8_FUNCTIONAL_SAFETY_RELEASE), 9=Cx9_PREPARATION_SG (CM_OnlineRemoteUpdateControlD_Cx9_PREPARATION_SG), 15=Cxf_Fehler (CM_OnlineRemoteUpdateControlD_Cxf_Fehler)}, range raw 0..15, to BMC_HV(timeout 3.2 s)  # This signal is part of the ORU functional safety concept to inform ECUs, if an update is possible
          signal OnlineRemoteUpdateControlOldD_XIX_ORU_Control_D_01_XIX_HCP5_CANFD01: start 16, 4 bit, little-endian, data-type-policy=OVERRIDE, i-signal-type=PRIMITIVE, init-value=0, base-type=BT_OnlineRemoteUpdateControlOldD, invalid-value=Invalid_OnlineRemoteUpdateControlOldD_XIX_ORU_Control_D_01_XIX_HCP5_CANFD01:15, compu {0=Cx0_IDLE (CM_OnlineRemoteUpdateControlOldD_Cx0_IDLE), 1=Cx1_PENDING (CM_OnlineRemoteUpdateControlOldD_Cx1_PENDING), 2=Cx2_PREPARATION (CM_OnlineRemoteUpdateControlOldD_Cx2_PREPARATION), 3=Cx3_PREPARATION_HV (CM_OnlineRemoteUpdateControlOldD_Cx3_PREPARATION_HV), 4=Cx4_RUNNING (CM_OnlineRemoteUpdateControlOldD_Cx4_RUNNING), 5=Cx5_RUNNING_HV (CM_OnlineRemoteUpdateControlOldD_Cx5_RUNNING_HV), 6=Cx6_PENDING_NOTREADY (CM_OnlineRemoteUpdateControlOldD_Cx6_PENDING_NOTREADY), 7=Cx7_OTA_FAILURE_POWERTRAIN_DISABLED (CM_OnlineRemoteUpdateControlOldD_Cx7_OTA_FAILURE_POWERTRAIN_DISABLED), 8=Cx8_FUNCTIONAL_SAFETY_RELEASE (CM_OnlineRemoteUpdateControlOldD_Cx8_FUNCTIONAL_SAFETY_RELEASE), 9=Cx9_PREPARATION_SG (CM_OnlineRemoteUpdateControlOldD_Cx9_PREPARATION_SG), 15=Cxf_Fehler (CM_OnlineRemoteUpdateControlOldD_Cxf_Fehler)}, range raw 0..15, to BMC_HV(timeout 3.2 s)  # Old state of the ORU control C component (state as of 5 previous cycles)
          signal OruVehicleLockRequestD_XIX_ORU_Control_D_01_XIX_HCP5_CANFD01: start 20, 2 bit, little-endian, data-type-policy=OVERRIDE, i-signal-type=PRIMITIVE, init-value=0, base-type=BT_OruVehicleLockRequestD, invalid-value=Invalid_OruVehicleLockRequestD_XIX_ORU_Control_D_01_XIX_HCP5_CANFD01:3, compu {0=Cx0_Init (CM_OruVehicleLockRequestD_Cx0_Init), 1=Cx1_Lock (CM_OruVehicleLockRequestD_Cx1_Lock), 2=Cx2_Release (CM_OruVehicleLockRequestD_Cx2_Release), 3=Cx3_Fehler (CM_OruVehicleLockRequestD_Cx3_Fehler)}, range raw 0..3  # Releases or locks one or more ECUs with their specific functions (e.g. immobilizer)
          signal OruIntegrityCheckActiveD_XIX_ORU_Control_D_01_XIX_HCP5_CANFD01: start 22, 2 bit, little-endian, data-type-policy=OVERRIDE, i-signal-type=PRIMITIVE, init-value=0, base-type=BT_OruIntegrityCheckActiveD, invalid-value=Invalid_OruIntegrityCheckActiveD_XIX_ORU_Control_D_01_XIX_HCP5_CANFD01:3, compu {0=Cx0_Init (CM_OruIntegrityCheckActiveD_Cx0_Init), 1=Cx1_Inactive (CM_OruIntegrityCheckActiveD_Cx1_Inactive), 2=Cx2_Active (CM_OruIntegrityCheckActiveD_Cx2_Active), 3=Cx3_Fehler (CM_OruIntegrityCheckActiveD_Cx3_Fehler)}, range raw 0..3  # Signal to indicate if the integrity check is active
          signal OruControlReleaseD_XIX_ORU_Control_D_01_XIX_HCP5_CANFD01: start 24, 16 bit, little-endian, data-type-policy=OVERRIDE, i-signal-type=PRIMITIVE, init-value=0, base-type=BT_OruControlReleaseD, compu {phys=raw for raw 0..65535; unit Unit_None}, range phys 0..65535 Unit_None, raw 0..65535, unit=Unit_None, to BMC_HV(timeout 3.2 s)  # This signal is used to allow an ECU to start an update session. As this is a critical point, 2 components have to approve this
          signal OruControlStateD_XIX_ORU_Control_D_01_XIX_HCP5_CANFD01: start 40, 8 bit, little-endian, data-type-policy=OVERRIDE, i-signal-type=PRIMITIVE, init-value=0, base-type=BT_OruControlStateD, invalid-value=Invalid_OruControlStateD_XIX_ORU_Control_D_01_XIX_HCP5_CANFD01:129, compu {0=Cx0_Idle (CM_OruControlStateD_Cx0_Idle), 1=Cx1_Check (CM_OruControlStateD_Cx1_Check), 3=Cx3_DataPresent (CM_OruControlStateD_Cx3_DataPresent), 7=Cx7_LockActive (CM_OruControlStateD_Cx7_LockActive), 15=Cxf_Running (CM_OruControlStateD_Cxf_Running), 31=Cx1f_Save (CM_OruControlStateD_Cx1f_Save), 63=Cx3f_Done (CM_OruControlStateD_Cx3f_Done), 65=Cx41_Fail (CM_OruControlStateD_Cx41_Fail), 129=Cx81_Fehler (CM_OruControlStateD_Cx81_Fehler)}, range raw 0..129  # This signal is used to allow an ECU to start an update session.
          signal OruReleasePartitionSwitchD_XIX_ORU_Control_D_01_XIX_HCP5_CANFD01: start 48, 2 bit, little-endian, data-type-policy=OVERRIDE, i-signal-type=PRIMITIVE, init-value=0, base-type=BT_OruReleasePartitionSwitchD, invalid-value=Invalid_OruReleasePartitionSwitchD_XIX_ORU_Control_D_01_XIX_HCP5_CANFD01:3, compu {0=Cx0_Init (CM_OruReleasePartitionSwitchD_Cx0_Init), 1=Cx1_Lock (CM_OruReleasePartitionSwitchD_Cx1_Lock), 2=Cx2_Release (CM_OruReleasePartitionSwitchD_Cx2_Release), 3=Cx3_Fehler (CM_OruReleasePartitionSwitchD_Cx3_Fehler)}, range raw 0..3  # Release to switch the partition in case of an A/B partition update
          signal OruHostUpdateD_XIX_ORU_Control_D_01_XIX_HCP5_CANFD01: start 50, 3 bit, little-endian, data-type-policy=OVERRIDE, i-signal-type=PRIMITIVE, init-value=0, base-type=BT_OruHostUpdateD, invalid-value=Invalid_OruHostUpdateD_XIX_ORU_Control_D_01_XIX_HCP5_CANFD01:4, compu {0=Cx0_Init (CM_OruHostUpdateD_Cx0_Init), 1=Cx1_HostControl1 (CM_OruHostUpdateD_Cx1_HostControl1), 2=Cx2_HostControl2 (CM_OruHostUpdateD_Cx2_HostControl2), 3=Cx3_HostControlOther (CM_OruHostUpdateD_Cx3_HostControlOther), 4=Cx4_Fehler (CM_OruHostUpdateD_Cx4_Fehler)}, range raw 0..4  # Releases an update of an critical funcion's host (due to functional safety)
          signal ISignalVoid_ORU_Control_D_01_XIX_HCP5_CANFD01_0: start 53, 3 bit, little-endian, system signal SignalVoid_ORU_Control_D_01_0, data-type-policy=OVERRIDE, i-signal-type=PRIMITIVE, base-type=BT_SignalVoid
          signal ISignalVoid_ORU_Control_D_01_XIX_HCP5_CANFD01_1: start 56, 8 bit, little-endian, system signal SignalVoid_ORU_Control_D_01_1, data-type-policy=OVERRIDE, i-signal-type=PRIMITIVE, base-type=BT_SignalVoid
          mapping SG_ORU_Control_D_01_XIX_HCP5_CANFD01: i-signal-group=SG_ORU_Control_D_01_XIX_HCP5_CANFD01, transfer-property=TRIGGERED-WITHOUT-REPETITION
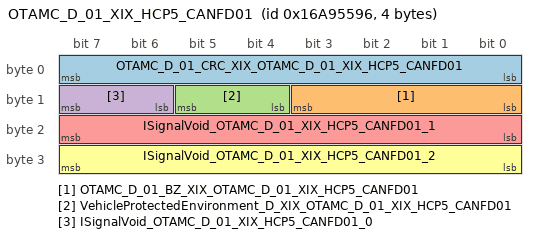
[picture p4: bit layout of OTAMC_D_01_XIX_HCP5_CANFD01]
      frame OTAMC_D_01_XIX_HCP5_CANFD01: id 0x16A95596, to BMC_HV, frame-length=4, can-addressing-mode=EXTENDED, can-frame-rx-behavior=CAN-FD, can-frame-tx-behavior=CAN-FD
        pdu OTAMC_D_01_XIX_HCP5_CANFD01_E2E: length=4, transmission-mode-true-timing=event-controlled-timing={number-of-repetitions=0, repetition-period=0}, unused-bit-pattern=0  # Fuer die Botschaft ist das Cyclic-Timing 0.32 zu verwenden.
          signal OTAMC_D_01_CRC_XIX_OTAMC_D_01_XIX_HCP5_CANFD01: start 0, 8 bit, little-endian, data-type-policy=OVERRIDE, i-signal-type=PRIMITIVE, init-value=0, base-type=BT_OTAMC_D_01_CRC, compu {phys=raw for raw 0..255}, range phys 0..255, raw 0..255, to BMC_HV(timeout 3.2 s)
          signal OTAMC_D_01_BZ_XIX_OTAMC_D_01_XIX_HCP5_CANFD01: start 8, 4 bit, little-endian, data-type-policy=OVERRIDE, i-signal-type=PRIMITIVE, init-value=0, base-type=BT_OTAMC_D_01_BZ, compu {phys=raw for raw 0..15}, range phys 0..15, raw 0..15, to BMC_HV(timeout 3.2 s)
          signal VehicleProtectedEnvironment_D_XIX_OTAMC_D_01_XIX_HCP5_CANFD01: start 12, 2 bit, little-endian, data-type-policy=OVERRIDE, i-signal-type=PRIMITIVE, init-value=0, base-type=BT_VehicleProtectedEnvironment_D, compu {0=Cx0_VPE_none (CM_VehicleProtectedEnvironment_D_Cx0_VPE_none), 1=Cx1_VPE_production (CM_VehicleProtectedEnvironment_D_Cx1_VPE_production), 2=Cx2_VPE_aftersales (CM_VehicleProtectedEnvironment_D_Cx2_VPE_aftersales)}, range raw 0..2, to BMC_HV(timeout 3.2 s)  # Environment of vehicle in case of Remote Production
          signal ISignalVoid_OTAMC_D_01_XIX_HCP5_CANFD01_0: start 14, 2 bit, little-endian, system signal SignalVoid_OTAMC_D_01_0, data-type-policy=OVERRIDE, i-signal-type=PRIMITIVE, base-type=BT_SignalVoid
          signal ISignalVoid_OTAMC_D_01_XIX_HCP5_CANFD01_1: start 16, 8 bit, little-endian, system signal SignalVoid_OTAMC_D_01_1, data-type-policy=OVERRIDE, i-signal-type=PRIMITIVE, base-type=BT_SignalVoid
          signal ISignalVoid_OTAMC_D_01_XIX_HCP5_CANFD01_2: start 24, 8 bit, little-endian, system signal SignalVoid_OTAMC_D_01_2, data-type-policy=OVERRIDE, i-signal-type=PRIMITIVE, base-type=BT_SignalVoid
          mapping SG_OTAMC_D_01_XIX_HCP5_CANFD01: i-signal-group=SG_OTAMC_D_01_XIX_HCP5_CANFD01, transfer-property=TRIGGERED-WITHOUT-REPETITION
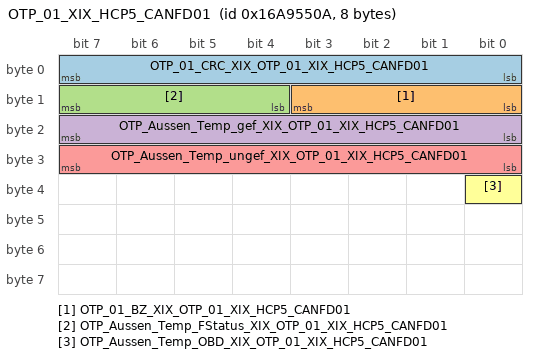
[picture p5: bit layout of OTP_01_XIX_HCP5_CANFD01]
      frame OTP_01_XIX_HCP5_CANFD01: id 0x16A9550A, to BMC_HV, frame-length=8, can-addressing-mode=EXTENDED, can-frame-rx-behavior=CAN-FD, can-frame-tx-behavior=CAN-FD
        pdu OTP_01_XIX_HCP5_CANFD01: length=8, transmission-mode-true-timing=cyclic-timing={time-offset=0, time-period=0.2}, unused-bit-pattern=0
          signal OTP_01_CRC_XIX_OTP_01_XIX_HCP5_CANFD01: start 0, 8 bit, little-endian, data-type-policy=OVERRIDE, i-signal-type=PRIMITIVE, init-value=0, base-type=BT_OTP_01_CRC, compu {phys=raw for raw 0..255}, range phys 0..255, raw 0..255, transfer-property=PENDING  # Für MLB: Berechnung siehe Lastenheft "Kommunikationsabsicherung für FlexRay und CAN" Ab MQB und MLBevo: Berechnung siehe Lastenheft "End-to-End Kommunikationsabsicherung" Endwerte siehe Begleitdokument "S-PDU Kennungsfolgen"
          signal OTP_01_BZ_XIX_OTP_01_XIX_HCP5_CANFD01: start 8, 4 bit, little-endian, data-type-policy=OVERRIDE, i-signal-type=PRIMITIVE, init-value=0, base-type=BT_OTP_01_BZ, compu {phys=raw for raw 0..15}, range phys 0..15, raw 0..15, transfer-property=PENDING  # 4bit Botschaftszähler, wird mit jeder Sendebotschaft inkrementiert
          signal OTP_Aussen_Temp_FStatus_XIX_OTP_01_XIX_HCP5_CANFD01: start 12, 4 bit, little-endian, data-type-policy=OVERRIDE, i-signal-type=PRIMITIVE, init-value=0, base-type=BT_OTP_Aussen_Temp_FStatus, compu {0=Cx0_kein_Fehler_Init_nicht_verbaut (CM_OTP_Aussen_Temp_FStatus_Cx0_kein_Fehler_Init_nicht_verbaut) (kein Fehler / Init / nicht verbaut), 1=Cx1_KS_Kurzschluss_nach_minus (CM_OTP_Aussen_Temp_FStatus_Cx1_KS_Kurzschluss_nach_minus) (KS- (Kurzschluss nach minus)), 2=Cx2_KS_Kurzschluss_nach_plus (CM_OTP_Aussen_Temp_FStatus_Cx2_KS_Kurzschluss_nach_plus) (KS+ (Kurzschluss nach plus)), 3=Cx3_OC_Leitungsunterbrechung (CM_OTP_Aussen_Temp_FStatus_Cx3_OC_Leitungsunterbrechung) (OC (Leitungsunterbrechung)), 4=Cx4_OOR_Signal_zu_gross (CM_OTP_Aussen_Temp_FStatus_Cx4_OOR_Signal_zu_gross) (OOR+ (Signal zu gross)), 5=Cx5_OOR_Signal_zu_klein (CM_OTP_Aussen_Temp_FStatus_Cx5_OOR_Signal_zu_klein) (OOR- (Signal zu klein)), 6=Cx6_RC_Signal_unplausibel_zu_gross (CM_OTP_Aussen_Temp_FStatus_Cx6_RC_Signal_unplausibel_zu_gross) (RC+ (Signal unplausibel zu gross)), 7=Cx7_RC_Signal_unplausibel_zu_klein (CM_OTP_Aussen_Temp_FStatus_Cx7_RC_Signal_unplausibel_zu_klein) (RC- (Signal unplausibel zu klein)), 8=Cx8_KS_OC_Kurzschluss_nach_plus_Unterbrechung (CM_OTP_Aussen_Temp_FStatus_Cx8_KS_OC_Kurzschluss_nach_plus_Unterbrechung) (KS+/OC (Kurzschluss nach plus/Unterbrechung)), 9=Cx9_KS_OC_Kurzschluss_nach_minus_Unterbrechung (CM_OTP_Aussen_Temp_FStatus_Cx9_KS_OC_Kurzschluss_nach_minus_Unterbrechung) (KS-/OC (Kurzschluss nach minus/Unterbrechung)), 10=Cxa_KS_KS_Kurzschluss_nach_minus_plus (CM_OTP_Aussen_Temp_FStatus_Cxa_KS_KS_Kurzschluss_nach_minus_plus) (KS-/KS+ (Kurzschluss nach minus/plus)), 11=Cxb_KS_KS_OC_Kurzschluss_nach_minus_plus_Unterbrechung (CM_OTP_Aussen_Temp_FStatus_Cxb_KS_KS_OC_Kurzschluss_nach_minus_plus_Unterbrechung) (KS-/KS+/OC (Kurzschluss nach minus/plus/Unterbrechung)), 12=Cxc_frei (CM_OTP_Aussen_Temp_FStatus_Cxc_frei), 13=Cxd_frei (CM_OTP_Aussen_Temp_FStatus_Cxd_frei), 14=Cxe_frei (CM_OTP_Aussen_Temp_FStatus_Cxe_frei), 15=Cxf_frei (CM_OTP_Aussen_Temp_FStatus_Cxf_frei)}, range raw 0..15, transfer-property=PENDING  # Fehlerstatus Umgebungstemperatursensor
          signal OTP_Aussen_Temp_gef_XIX_OTP_01_XIX_HCP5_CANFD01: start 16, 8 bit, little-endian, data-type-policy=OVERRIDE, i-signal-type=PRIMITIVE, init-value=254, base-type=BT_OTP_Aussen_Temp_gef, invalid-value=Invalid_OTP_Aussen_Temp_gef_XIX_OTP_01_XIX_HCP5_CANFD01:255, compu {phys=raw*0.5-50 for raw 0..250, 253=Cxfd_nicht_verbaut (CM_OTP_Aussen_Temp_gef_Cxfd_nicht_verbaut), 254=Cxfe_Init (CM_OTP_Aussen_Temp_gef_Cxfe_Init), 255=Cxff_Fehler (CM_OTP_Aussen_Temp_gef_Cxff_Fehler); unit Unit_DegreCelsi}, range phys -50..75 Unit_DegreCelsi, raw 0..255, unit=Unit_DegreCelsi, transfer-property=PENDING  # Gefilterte Aussentemperatur. Es werden hier Einflüsse durch Abwärme ausgefiltert.
          signal OTP_Aussen_Temp_ungef_XIX_OTP_01_XIX_HCP5_CANFD01: start 24, 8 bit, little-endian, data-type-policy=OVERRIDE, i-signal-type=PRIMITIVE, init-value=254, base-type=BT_OTP_Aussen_Temp_ungef, invalid-value=Invalid_OTP_Aussen_Temp_ungef_XIX_OTP_01_XIX_HCP5_CANFD01:255, compu {phys=raw*0.5-50 for raw 0..252, 253=Cxfd_nicht_verbaut (CM_OTP_Aussen_Temp_ungef_Cxfd_nicht_verbaut), 254=Cxfe_Initwert (CM_OTP_Aussen_Temp_ungef_Cxfe_Initwert), 255=Cxff_Fehler (CM_OTP_Aussen_Temp_ungef_Cxff_Fehler); unit Unit_DegreCelsi}, range phys -50..76 Unit_DegreCelsi, raw 0..255, unit=Unit_DegreCelsi, transfer-property=PENDING, to BMC_HV(timeout 2 s)  # ungefilterter Wert des Aussentemperatursensors
          signal OTP_Aussen_Temp_OBD_XIX_OTP_01_XIX_HCP5_CANFD01: start 32, 1 bit, little-endian, data-type-policy=OVERRIDE, i-signal-type=PRIMITIVE, init-value=1, base-type=BT_OTP_Aussen_Temp_OBD, compu {0=Cx0_gueltiger_Wert (CM_OTP_Aussen_Temp_OBD_Cx0_gueltiger_Wert), 1=Cx1_Ersatz_Init_oder_Fehlerwert (CM_OTP_Aussen_Temp_OBD_Cx1_Ersatz_Init_oder_Fehlerwert)}, range raw 0..1, transfer-property=PENDING, to BMC_HV(timeout 2 s)  # OBD-QBit der Aussentemperatur. Gesetzt bei Ersatzwert, Init oder Fehler.
      frame SOK_NoAuthenticTime_01_XIX_HCP5_CANFD01: id 0x1A5555AC, to BMC_HV, frame-length=8, can-addressing-mode=EXTENDED, can-frame-rx-behavior=CAN-FD, can-frame-tx-behavior=CAN-FD
        pdu SOK_NoAuthenticTime_01_XIX_HCP5_CANFD01: length=8, transmission-mode-true-timing=event-controlled-timing={number-of-repetitions=0, repetition-period=0}, unused-bit-pattern=0
          signal SOK_ungeschuetzte_Zeit_XIX_SOK_NoAuthenticTime_01_XIX_HCP5_CANFD01: start 8, 56 bit, opaque, data-type-policy=OVERRIDE, i-signal-type=ARRAY, init-value=7 x 0, base-type=BT_SOK_ungeschuetzte_Zeit, compu {0=Cx0_Init (CM_SOK_ungeschuetzte_Zeit_Cx0_Init), phys=raw for raw 1..7.20575940379279e+16; unit Unit_None}, range phys 1..72057594037927935 Unit_None, raw 0..72057594037927935, unit=Unit_None, transfer-property=TRIGGERED-ON-CHANGE-WITHOUT-REPETITION, to BMC_HV  # Periodisch verschickter SOK Zeitwert des SOK Zeitmasters als Referenzzeit zur Erkennung von Clockjitter durch andere SOK Teilnehmer. Der Empfang dieses Signals ist verpflichtend für jedes Steuergerät, das durch die authentische Broadcast Funktionalität von SOK geschützte Daten versendet oder empfängt.
      frame SOK_Zeit_Hybrid_01_Chal_01_XIX_HCP5_CANFD01: id 0x12E0007B, from BMC_HV, frame-length=8, can-addressing-mode=EXTENDED, can-frame-rx-behavior=CAN-FD, can-frame-tx-behavior=CAN-FD
        pdu SOK_Zeit_Hybrid_01_Chal_01_XIX_HCP5_CANFD01: length=8, minimum-delay=0.1, transmission-mode-true-timing=event-controlled-timing={number-of-repetitions=0, repetition-period=0}, unused-bit-pattern=0
          signal SOK_Zeit_Hybrid_01_Challenge_XIX_SOK_Zeit_Hybrid_01_Chal_01_XIX_HCP5_CANFD01: start 0, 64 bit, opaque, data-type-policy=OVERRIDE, i-signal-type=ARRAY, base-type=BT_SOK_Zeit_Hybrid_01_Challenge, compu {phys=raw for raw 0..1.84467440737096e+19; unit Unit_None}, range phys 0..18446744073709551615 Unit_None, raw 0..18446744073709551615, unit=Unit_None, transfer-property=TRIGGERED-ON-CHANGE-WITHOUT-REPETITION  # Challenge of SOK participant BMC_HV to SOK time server for requesting authentic SOK time
      frame SOK_Zeit_Hybrid_01_Resp_01_SOK_XIX_HCP5_CANFD01: id 0x12E2007B, to BMC_HV, frame-length=16, can-addressing-mode=EXTENDED, can-frame-rx-behavior=CAN-FD, can-frame-tx-behavior=CAN-FD
        secured i pdu SOK_Zeit_Hybrid_01_Resp_01_SOK_XIX_HCP5_CANFD01:
          length=16
          authentication-props=SecureCommunicationAuthenticationProps_XIX_64
          freshness-props=SecureCommunicationFreshnessProps
          payload=PT_SOK_Zeit_Hybrid_01_Resp_01
          secure-communication-props={auth-data-freshness-length=0, auth-data-freshness-start-position=0, auth-info-tx-length=64, authentication-build-attempts=1, authentication-retries=1, data-id=402, freshness-value-id=0, freshness-value-length=64, freshness-value-tx-length=0}
          use-as-cryptographic-i-pdu=false
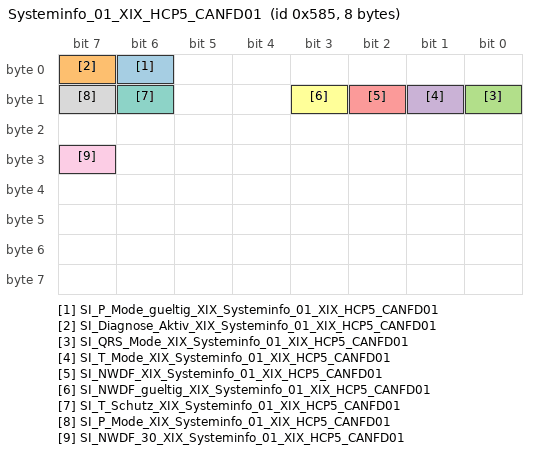
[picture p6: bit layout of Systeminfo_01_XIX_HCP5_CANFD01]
      frame Systeminfo_01_XIX_HCP5_CANFD01: id 0x585, to BMC_HV, frame-length=8, can-addressing-mode=STANDARD, can-frame-rx-behavior=CAN-FD, can-frame-tx-behavior=CAN-FD
        pdu Systeminfo_01_XIX_HCP5_CANFD01: length=8, minimum-delay=0.01, transmission-mode-true-timing={cyclic-timing={time-offset=0, time-period=1}, event-controlled-timing={number-of-repetitions=0, repetition-period=0}}, unused-bit-pattern=0  # MQB, MLBevo
          signal SI_P_Mode_gueltig_XIX_Systeminfo_01_XIX_HCP5_CANFD01: start 6, 1 bit, little-endian, data-type-policy=OVERRIDE, i-signal-type=PRIMITIVE, init-value=0, base-type=BT_SI_P_Mode_gueltig, compu {0=Cx0_dezentraler_Produktionsmode (CM_SI_P_Mode_gueltig_Cx0_dezentraler_Produktionsmode), 1=Cx1_zentraler_Produktionsmode (CM_SI_P_Mode_gueltig_Cx1_zentraler_Produktionsmode)}, range raw 0..1, transfer-property=PENDING, to BMC_HV(timeout 5 s)  # zeigt an, ob es sich um ein Fahrzeug mit zentraler oder dezentraler Steu-erung des Produktionsmodes handelt Siehe Q-LAH Produktionsmode (LAH.DUM.907.AS)
          signal SI_Diagnose_Aktiv_XIX_Systeminfo_01_XIX_HCP5_CANFD01: start 7, 1 bit, little-endian, data-type-policy=OVERRIDE, i-signal-type=PRIMITIVE, init-value=0, base-type=BT_SI_Diagnose_Aktiv, compu {0=Cx0_inaktiv (CM_SI_Diagnose_Aktiv_Cx0_inaktiv), 1=Cx1_aktiv (CM_SI_Diagnose_Aktiv_Cx1_aktiv)}, range raw 0..1, transfer-property=PENDING  # Gibt an ob Diagnose-Botschaften empfangen werden und somit eine Diagnose aktiv ist. MQB: Gibt an ob Diagnose-Bus Botschaften empfangen werden und somit eine Diagnose aktiv ist.
          signal SI_QRS_Mode_XIX_Systeminfo_01_XIX_HCP5_CANFD01: start 8, 1 bit, little-endian, data-type-policy=OVERRIDE, i-signal-type=PRIMITIVE, init-value=0, base-type=BT_SI_QRS_Mode, compu {0=Cx0_QRS_Messmodus_nicht_aktiv (CM_SI_QRS_Mode_Cx0_QRS_Messmodus_nicht_aktiv), 1=Cx1_QRS_Messmodus_aktiv (CM_SI_QRS_Mode_Cx1_QRS_Messmodus_aktiv)}, range raw 0..1, transfer-property=PENDING  # Messmodus Quick-Ruhestrom
          signal SI_T_Mode_XIX_Systeminfo_01_XIX_HCP5_CANFD01: start 9, 1 bit, little-endian, data-type-policy=OVERRIDE, i-signal-type=PRIMITIVE, init-value=0, base-type=BT_SI_T_Mode, compu {0=Cx0_Transportmodus_nicht_aktiv (CM_SI_T_Mode_Cx0_Transportmodus_nicht_aktiv), 1=Cx1_Transportmodus_aktiv (CM_SI_T_Mode_Cx1_Transportmodus_aktiv)}, range raw 0..1, transfer-property=PENDING, to BMC_HV(timeout 5 s)  # 0x0: Transportmodus nicht aktiv 0x1: Transportmodus aktiv
          signal SI_NWDF_XIX_Systeminfo_01_XIX_HCP5_CANFD01: start 10, 1 bit, little-endian, data-type-policy=OVERRIDE, i-signal-type=PRIMITIVE, init-value=0, base-type=BT_SI_NWDF, compu {0=Cx0_Ueberwachung_nicht_freigegeben (CM_SI_NWDF_Cx0_Ueberwachung_nicht_freigegeben), 1=Cx1_Ueberwachung_freigegeben (CM_SI_NWDF_Cx1_Ueberwachung_freigegeben)}, range raw 0..1, transfer-property=TRIGGERED-ON-CHANGE-WITHOUT-REPETITION, to BMC_HV(timeout 5 s)  # Netzwerk-Diagnose Freigebe zur zentralen Aktivierung der Netzwerkdiagnose
          signal SI_NWDF_gueltig_XIX_Systeminfo_01_XIX_HCP5_CANFD01: start 11, 1 bit, little-endian, data-type-policy=OVERRIDE, i-signal-type=PRIMITIVE, init-value=1, base-type=BT_SI_NWDF_gueltig, compu {0=Cx0_NWDF_wird_nicht_unterstuetzt (CM_SI_NWDF_gueltig_Cx0_NWDF_wird_nicht_unterstuetzt), 1=Cx1_NWDF_wird_unterstuetzt (CM_SI_NWDF_gueltig_Cx1_NWDF_wird_unterstuetzt)}, range raw 0..1, transfer-property=PENDING  # Gültigkeitsbit zu SI_NWDF gemäß Lastenheft: Zentrale Aktivierung Netzwerkdiagnose
          signal SI_T_Schutz_XIX_Systeminfo_01_XIX_HCP5_CANFD01: start 14, 1 bit, little-endian, data-type-policy=OVERRIDE, i-signal-type=PRIMITIVE, init-value=0, base-type=BT_SI_T_Schutz, compu {0=Cx0_Transportschutz_nicht_aktiv (CM_SI_T_Schutz_Cx0_Transportschutz_nicht_aktiv), 1=Cx1_Transportschutz_aktiv (CM_SI_T_Schutz_Cx1_Transportschutz_aktiv)}, range raw 0..1, transfer-property=PENDING  # Transportschutz-Signal, das bei Transportmodus und Motorlauf aktiv bleibt 0x0: Transportschutz nicht aktiv 0x1: Transportschutz aktiv
          signal SI_P_Mode_XIX_Systeminfo_01_XIX_HCP5_CANFD01: start 15, 1 bit, little-endian, data-type-policy=OVERRIDE, i-signal-type=PRIMITIVE, init-value=0, base-type=BT_SI_P_Mode, compu {0=Cx0_inaktiv (CM_SI_P_Mode_Cx0_inaktiv), 1=Cx1_aktiv (CM_SI_P_Mode_Cx1_aktiv)}, range raw 0..1, transfer-property=PENDING, to BMC_HV(timeout 5 s)  # Zentrale Steuerung des Produktionsmodes gemäß Q-LAH-Produktionsmode (LAH.DUM.907.AS)
          signal SI_NWDF_30_XIX_Systeminfo_01_XIX_HCP5_CANFD01: start 31, 1 bit, little-endian, data-type-policy=OVERRIDE, i-signal-type=PRIMITIVE, init-value=0, base-type=BT_SI_NWDF_30, compu {0=Cx0_Ueberwachung_nicht_freigegeben (CM_SI_NWDF_30_Cx0_Ueberwachung_nicht_freigegeben), 1=Cx1_Ueberwachung_freigegeben (CM_SI_NWDF_30_Cx1_Ueberwachung_freigegeben)}, range raw 0..1, transfer-property=TRIGGERED-ON-CHANGE-WITHOUT-REPETITION, to BMC_HV(timeout 5 s)  # Netzwerk-Diagnose Freigabe zur zentralen Aktivierung der Netzwerkdiagnose (keine Ausblendbedingung aktiv)
      frame Thermomanagement_01_XIX_HCP5_CANFD01: id 0x12DD5516, to BMC_HV, frame-length=64, can-addressing-mode=EXTENDED, can-frame-rx-behavior=CAN-FD, can-frame-tx-behavior=CAN-FD
        pdu Thermomanagement_01_XIX_HCP5_CANFD01: length=64, minimum-delay=0.01, transmission-mode-true-timing={cyclic-timing={time-offset=0, time-period=0.1}, event-controlled-timing={number-of-repetitions=5, repetition-period=0.02}}, unused-bit-pattern=0
          signal TME_EKK_Istmodus_XIX_Thermomanagement_01_XIX_HCP5_CANFD01: start 12, 3 bit, little-endian, data-type-policy=OVERRIDE, i-signal-type=PRIMITIVE, init-value=7, base-type=BT_TME_EKK_Istmodus, invalid-value=Invalid_TME_EKK_Istmodus_XIX_Thermomanagement_01_XIX_HCP5_CANFD01:5, compu {0=Cx0_Standby (CM_TME_EKK_Istmodus_Cx0_Standby), 1=Cx1_Regelung_aktiv (CM_TME_EKK_Istmodus_Cx1_Regelung_aktiv), 2=Cx2_Freigabe_ausgesetzt (CM_TME_EKK_Istmodus_Cx2_Freigabe_ausgesetzt), 5=Cx5_Fehler (CM_TME_EKK_Istmodus_Cx5_Fehler), 7=Cx7_Init (CM_TME_EKK_Istmodus_Cx7_Init)}, range raw 0..7, transfer-property=PENDING  # aktuelle IstModus des elektrischen Klimakompressors
          signal TME_IPB_Status_Kuehlung_XIX_Thermomanagement_01_XIX_HCP5_CANFD01: start 15, 1 bit, little-endian, data-type-policy=OVERRIDE, i-signal-type=PRIMITIVE, init-value=0, base-type=BT_TME_IPB_Status_Kuehlung, invalid-value=Invalid_TME_IPB_Status_Kuehlung_XIX_Thermomanagement_01_XIX_HCP5_CANFD01:1, compu {0=Cx0_kein_Fehler (CM_TME_IPB_Status_Kuehlung_Cx0_kein_Fehler), 1=Cx1_Fehler (CM_TME_IPB_Status_Kuehlung_Cx1_Fehler)}, range raw 0..1, transfer-property=PENDING  # Statuss seitens Thermomanagement, ob die Kühlung der IPB funktional i.O. ist
          signal TME_HVHW_Ansteuerung_Soll_XIX_Thermomanagement_01_XIX_HCP5_CANFD01: start 24, 8 bit, little-endian, data-type-policy=OVERRIDE, i-signal-type=PRIMITIVE, init-value=254, base-type=BT_TME_HVHW_Ansteuerung_Soll, invalid-value=Invalid_TME_HVHW_Ansteuerung_Soll_XIX_Thermomanagement_01_XIX_HCP5_CANFD01:255, compu {phys=raw for raw 0..100, 254=Cxfe_Init (CM_TME_HVHW_Ansteuerung_Soll_Cxfe_Init), 255=Cxff_Fehler (CM_TME_HVHW_Ansteuerung_Soll_Cxff_Fehler); unit Unit_PerCent}, range phys 0..100 Unit_PerCent, raw 0..255, unit=Unit_PerCent, transfer-property=PENDING  # Soll Ansteuerung für den HV-Heizer-Wasser
          signal KL_Verdampfertemperatur_XIX_Thermomanagement_01_XIX_HCP5_CANFD01: start 32, 10 bit, little-endian, data-type-policy=OVERRIDE, i-signal-type=PRIMITIVE, init-value=1022, base-type=BT_KL_Verdampfertemperatur, invalid-value=Invalid_KL_Verdampfertemperatur_XIX_Thermomanagement_01_XIX_HCP5_CANFD01:1023, compu {phys=raw*0.1-20 for raw 0..900, 1022=Cx3fe_Init (CM_KL_Verdampfertemperatur_Cx3fe_Init), 1023=Cx3ff_Fehler (CM_KL_Verdampfertemperatur_Cx3ff_Fehler); unit Unit_DegreCelsi}, range phys -20..70 Unit_DegreCelsi, raw 0..1023, unit=Unit_DegreCelsi, transfer-property=PENDING  # Istwert der Verdampfertemperatur
          signal TME_HVHL_Istmodus_XIX_Thermomanagement_01_XIX_HCP5_CANFD01: start 42, 3 bit, little-endian, data-type-policy=OVERRIDE, i-signal-type=PRIMITIVE, init-value=7, base-type=BT_TME_HVHL_Istmodus, invalid-value=Invalid_TME_HVHL_Istmodus_XIX_Thermomanagement_01_XIX_HCP5_CANFD01:5, compu {0=Cx0_Standby (CM_TME_HVHL_Istmodus_Cx0_Standby), 1=Cx1_Regelung_aktiv (CM_TME_HVHL_Istmodus_Cx1_Regelung_aktiv), 2=Cx2_Freigabe_ausgesetzt (CM_TME_HVHL_Istmodus_Cx2_Freigabe_ausgesetzt), 5=Cx5_Fehler (CM_TME_HVHL_Istmodus_Cx5_Fehler), 7=Cx7_Init (CM_TME_HVHL_Istmodus_Cx7_Init)}, range raw 0..7, transfer-property=PENDING  # aktueller Status des HV-Heizer-Wasser
          signal TME_PTC_Verbauinfo_XIX_Thermomanagement_01_XIX_HCP5_CANFD01: start 45, 2 bit, little-endian, data-type-policy=OVERRIDE, i-signal-type=PRIMITIVE, init-value=0, base-type=BT_TME_PTC_Verbauinfo, compu {0=Cx0_kein_PTC (CM_TME_PTC_Verbauinfo_Cx0_kein_PTC), 1=Cx1_600W_geschaltet (CM_TME_PTC_Verbauinfo_Cx1_600W_geschaltet), 2=Cx2_1000W_geschaltet (CM_TME_PTC_Verbauinfo_Cx2_1000W_geschaltet), 3=Cx3_1400W_LIN (CM_TME_PTC_Verbauinfo_Cx3_1400W_LIN)}, range raw 0..3, transfer-property=PENDING  # Im Thermomanagement wird der Verbau eines PTCs und dessen elektr. Leistungsklasse codiert
          signal TME_HV_IstLeistung_XIX_Thermomanagement_01_XIX_HCP5_CANFD01: start 47, 9 bit, little-endian, data-type-policy=OVERRIDE, i-signal-type=PRIMITIVE, init-value=510, base-type=BT_TME_HV_IstLeistung, invalid-value=Invalid_TME_HV_IstLeistung_XIX_Thermomanagement_01_XIX_HCP5_CANFD01:511, compu {phys=raw*50 for raw 0..509, 510=Cx1fe_Init (CM_TME_HV_IstLeistung_Cx1fe_Init), 511=Cx1ff_Fehler (CM_TME_HV_IstLeistung_Cx1ff_Fehler); unit Unit_Watt}, range phys 0..25450 Unit_Watt, raw 0..511, unit=Unit_Watt, transfer-property=PENDING  # Aktuelle HV Leistung aller HV-Komponenten des Thermomanagements
          signal TME_HVEM_HV_Anf_XIX_Thermomanagement_01_XIX_HCP5_CANFD01: start 56, 2 bit, little-endian, data-type-policy=OVERRIDE, i-signal-type=PRIMITIVE, init-value=0, base-type=BT_TME_HVEM_HV_Anf, invalid-value=Invalid_TME_HVEM_HV_Anf_XIX_Thermomanagement_01_XIX_HCP5_CANFD01:3, compu {0=Cx0_INIT (CM_TME_HVEM_HV_Anf_Cx0_INIT), 1=Cx1_HV_Netz_nicht_angefordert (CM_TME_HVEM_HV_Anf_Cx1_HV_Netz_nicht_angefordert), 2=Cx2_HV_Netz_angefordert (CM_TME_HVEM_HV_Anf_Cx2_HV_Netz_angefordert), 3=Cx3_Fehler (CM_TME_HVEM_HV_Anf_Cx3_Fehler)}, range raw 0..3, transfer-property=PENDING  # Anforderung "HV-Netz aktivieren" wegen Innenraumkonditionierung mit HV-Komponente
          signal EKK_HVK_EoHVL_Status_XIX_Thermomanagement_01_XIX_HCP5_CANFD01: start 58, 2 bit, little-endian, data-type-policy=OVERRIDE, i-signal-type=PRIMITIVE, init-value=0, base-type=BT_EKK_HVK_EoHVL_Status, invalid-value=Invalid_EKK_HVK_EoHVL_Status_XIX_Thermomanagement_01_XIX_HCP5_CANFD01:3, compu {0=Cx0_Init (CM_EKK_HVK_EoHVL_Status_Cx0_Init), 1=Cx1_Uzwkr_kleiner_UEoHVL_Schwell (CM_EKK_HVK_EoHVL_Status_Cx1_Uzwkr_kleiner_UEoHVL_Schwell), 2=Cx2_Uzwkr_groesgleich_UEoHVL_Schwell (CM_EKK_HVK_EoHVL_Status_Cx2_Uzwkr_groesgleich_UEoHVL_Schwell), 3=Cx3_Fehler (CM_EKK_HVK_EoHVL_Status_Cx3_Fehler)}, range raw 0..3, transfer-property=PENDING, to BMC_HV(timeout 1 s)  # Status - Erkennung offener HV-Leitung des elektrischen Klimakompressors
          signal HVHL_HVK_EoHVL_Status_XIX_Thermomanagement_01_XIX_HCP5_CANFD01: start 60, 2 bit, little-endian, data-type-policy=OVERRIDE, i-signal-type=PRIMITIVE, init-value=0, base-type=BT_HVHL_HVK_EoHVL_Status, invalid-value=Invalid_HVHL_HVK_EoHVL_Status_XIX_Thermomanagement_01_XIX_HCP5_CANFD01:3, compu {0=Cx0_Init (CM_HVHL_HVK_EoHVL_Status_Cx0_Init), 1=Cx1_Uzwkr_kleiner_UEoHVL_Schwell (CM_HVHL_HVK_EoHVL_Status_Cx1_Uzwkr_kleiner_UEoHVL_Schwell), 2=Cx2_Uzwkr_groesgleich_UEoHVL_Schwell (CM_HVHL_HVK_EoHVL_Status_Cx2_Uzwkr_groesgleich_UEoHVL_Schwell), 3=Cx3_Fehler (CM_HVHL_HVK_EoHVL_Status_Cx3_Fehler)}, range raw 0..3, transfer-property=PENDING  # Status - Erkennung offener HV-Leitung desHV-Heizer-Wasser
          signal TME_HVHW_SollModus_XIX_Thermomanagement_01_XIX_HCP5_CANFD01: start 62, 2 bit, little-endian, data-type-policy=OVERRIDE, i-signal-type=PRIMITIVE, init-value=3, base-type=BT_TME_HVHW_SollModus, compu {0=Cx0_Keine_Freigabe (CM_TME_HVHW_SollModus_Cx0_Keine_Freigabe), 1=Cx1_Freigabe (CM_TME_HVHW_SollModus_Cx1_Freigabe), 2=Cx2_Freigabe_ausgesetzt (CM_TME_HVHW_SollModus_Cx2_Freigabe_ausgesetzt), 3=Cx3_Init (CM_TME_HVHW_SollModus_Cx3_Init)}, range raw 0..3, transfer-property=PENDING  # Freigabesignal seitens Thermomanagement für den HV-Heizer-Wasser
          signal TME_Klimaanforderung_XIX_Thermomanagement_01_XIX_HCP5_CANFD01: start 64, 3 bit, little-endian, data-type-policy=OVERRIDE, i-signal-type=PRIMITIVE, init-value=0, base-type=BT_TME_Klimaanforderung, compu {0=Cx0_keine_Anforderung_durch_TME (CM_TME_Klimaanforderung_Cx0_keine_Anforderung_durch_TME), 1=Cx1_Klimaleistungspraediktion_aktiv (CM_TME_Klimaanforderung_Cx1_Klimaleistungspraediktion_aktiv), 2=Cx2_berechnung_Vorkonditionierung_aktiv (CM_TME_Klimaanforderung_Cx2_berechnung_Vorkonditionierung_aktiv), 3=Cx3_Vorkonditionierung_aktiv (CM_TME_Klimaanforderung_Cx3_Vorkonditionierung_aktiv)}, range raw 0..3, transfer-property=PENDING  # Anforderungsgrund der Klimaapplikation durch die TME
          signal HVHL_HVK_Fehler_intern_XIX_Thermomanagement_01_XIX_HCP5_CANFD01: start 67, 1 bit, little-endian, data-type-policy=OVERRIDE, i-signal-type=PRIMITIVE, init-value=0, base-type=BT_HVHL_HVK_Fehler_intern, compu {0=Cx0_kein_Fehler (CM_HVHL_HVK_Fehler_intern_Cx0_kein_Fehler) (kein Fehler), 1=Cx1_Fehler_aktiv (CM_HVHL_HVK_Fehler_intern_Cx1_Fehler_aktiv)}, range raw 0..1, transfer-property=PENDING  # HVK relevanter Fehler des elektrischen HV-Heizer-Wasser
          signal HV_Heizer_Status_XIX_Thermomanagement_01_XIX_HCP5_CANFD01: start 68, 2 bit, little-endian, data-type-policy=OVERRIDE, i-signal-type=PRIMITIVE, init-value=0, base-type=BT_HV_Heizer_Status, compu {0=Cx0_nicht_aktiv (CM_HV_Heizer_Status_Cx0_nicht_aktiv), 1=Cx1_aktiv (CM_HV_Heizer_Status_Cx1_aktiv), 3=Cx3_nicht_verfuegbar (CM_HV_Heizer_Status_Cx3_nicht_verfuegbar)}, range raw 0..3, transfer-property=TRIGGERED-ON-CHANGE-WITHOUT-REPETITION  # Ansteuerstatus Hochvoltheizer
          signal Kompressor_Status_XIX_Thermomanagement_01_XIX_HCP5_CANFD01: start 70, 2 bit, little-endian, data-type-policy=OVERRIDE, i-signal-type=PRIMITIVE, init-value=0, base-type=BT_Kompressor_Status, compu {0=Cx0_nicht_aktiv (CM_Kompressor_Status_Cx0_nicht_aktiv), 1=Cx1_aktiv (CM_Kompressor_Status_Cx1_aktiv), 3=Cx3_nicht_verfuegbar (CM_Kompressor_Status_Cx3_nicht_verfuegbar)}, range raw 0..3, transfer-property=TRIGGERED-ON-CHANGE-WITHOUT-REPETITION  # Ansteuerstatus Klimakompressor
          signal EKK_HVK_Fehler_intern_XIX_Thermomanagement_01_XIX_HCP5_CANFD01: start 72, 1 bit, little-endian, data-type-policy=OVERRIDE, i-signal-type=PRIMITIVE, init-value=0, base-type=BT_EKK_HVK_Fehler_intern, compu {0=Cx0_kein_Fehler (CM_EKK_HVK_Fehler_intern_Cx0_kein_Fehler) (kein Fehler), 1=Cx1_Fehler_aktiv (CM_EKK_HVK_Fehler_intern_Cx1_Fehler_aktiv)}, range raw 0..1, transfer-property=PENDING  # HVK relevanter Fehler des elektrischen Klimakompressors
          signal Waermepumpe_Status_XIX_Thermomanagement_01_XIX_HCP5_CANFD01: start 73, 2 bit, little-endian, data-type-policy=OVERRIDE, i-signal-type=PRIMITIVE, init-value=0, base-type=BT_Waermepumpe_Status, compu {0=Cx0_nicht_aktiv (CM_Waermepumpe_Status_Cx0_nicht_aktiv), 1=Cx1_aktiv (CM_Waermepumpe_Status_Cx1_aktiv), 3=Cx3_nicht_verfuegbar (CM_Waermepumpe_Status_Cx3_nicht_verfuegbar)}, range raw 0..3, transfer-property=TRIGGERED-ON-CHANGE-WITHOUT-REPETITION  # Ansteuerstatus Wärmepumpe
          signal Thermo_Verbrauch_BTL_XIX_Thermomanagement_01_XIX_HCP5_CANFD01: start 75, 13 bit, little-endian, data-type-policy=OVERRIDE, i-signal-type=PRIMITIVE, init-value=0, base-type=BT_Thermo_Verbrauch_BTL, compu {phys=raw for raw 0..8191; unit Unit_WattSecond}, range phys 0..8191 Unit_WattSecond, raw 0..8191, unit=Unit_WattSecond, transfer-property=PENDING  # Verbrauch für Heizen und Kühlen der Bauteile
          signal Thermo_Verbrauch_BTL_Ueberlauf_XIX_Thermomanagement_01_XIX_HCP5_CANFD01: start 88, 1 bit, little-endian, data-type-policy=OVERRIDE, i-signal-type=PRIMITIVE, init-value=0, base-type=BT_Thermo_Verbrauch_BTL_Ueberlauf, compu {0=Cx0_kein_Ueberlauf (CM_Thermo_Verbrauch_BTL_Ueberlauf_Cx0_kein_Ueberlauf), 1=Cx1_Ueberlauf (CM_Thermo_Verbrauch_BTL_Ueberlauf_Cx1_Ueberlauf)}, range raw 0..1, transfer-property=PENDING  # Überlauf-Bit Verbrauch Bauteil
          signal Thermo_Verbrauch_Innen_Ueberlauf_XIX_Thermomanagement_01_XIX_HCP5_CANFD01: start 89, 1 bit, little-endian, data-type-policy=OVERRIDE, i-signal-type=PRIMITIVE, init-value=0, base-type=BT_Thermo_Verbrauch_Innen_Ueberlauf, compu {0=Cx0_kein_Ueberlauf (CM_Thermo_Verbrauch_Innen_Ueberlauf_Cx0_kein_Ueberlauf), 1=Cx1_Ueberlauf (CM_Thermo_Verbrauch_Innen_Ueberlauf_Cx1_Ueberlauf)}, range raw 0..1, transfer-property=PENDING  # Überlauf-Bit Verbrauch Innenraum
          signal Thermo_Verbrauch_Innen_XIX_Thermomanagement_01_XIX_HCP5_CANFD01: start 90, 13 bit, little-endian, data-type-policy=OVERRIDE, i-signal-type=PRIMITIVE, init-value=0, base-type=BT_Thermo_Verbrauch_Innen, compu {phys=raw for raw 0..8191; unit Unit_WattSecond}, range phys 0..8191 Unit_WattSecond, raw 0..8191, unit=Unit_WattSecond, transfer-property=PENDING  # Verbrauch für Heizen und Kühlen Innenraum
          signal TME_HVHW_HVK_Fehler_intern_XIX_Thermomanagement_01_XIX_HCP5_CANFD01: start 103, 1 bit, little-endian, data-type-policy=OVERRIDE, i-signal-type=PRIMITIVE, init-value=0, base-type=BT_TME_HVHW_HVK_Fehler_intern, compu {0=Cx0_kein_Fehler (CM_TME_HVHW_HVK_Fehler_intern_Cx0_kein_Fehler), 1=Cx1_Fehler_aktiv (CM_TME_HVHW_HVK_Fehler_intern_Cx1_Fehler_aktiv)}, range raw 0..1, transfer-property=PENDING  # HVK relevanter Fehler des HV-Heizers
          signal TME_Min_Fahrdrehzahl_XIX_Thermomanagement_01_XIX_HCP5_CANFD01: start 104, 7 bit, little-endian, data-type-policy=OVERRIDE, i-signal-type=PRIMITIVE, init-value=126, base-type=BT_TME_Min_Fahrdrehzahl, invalid-value=Invalid_TME_Min_Fahrdrehzahl_XIX_Thermomanagement_01_XIX_HCP5_CANFD01:127, compu {phys=raw*10+500 for raw 0..125, 126=Cx7e_Init (CM_TME_Min_Fahrdrehzahl_Cx7e_Init), 127=Cx7f_Fehler (CM_TME_Min_Fahrdrehzahl_Cx7f_Fehler); unit Unit_MinutInver}, range phys 500..1750 Unit_MinutInver, raw 0..127, unit=Unit_MinutInver, transfer-property=PENDING  # Minimale Motordrehzahl während der Fahrt
          signal TME_HVHW_HVK_IstModus_XIX_Thermomanagement_01_XIX_HCP5_CANFD01: start 111, 3 bit, little-endian, data-type-policy=OVERRIDE, i-signal-type=PRIMITIVE, init-value=7, base-type=BT_TME_HVHW_HVK_IstModus, invalid-value=Invalid_TME_HVHW_HVK_IstModus_XIX_Thermomanagement_01_XIX_HCP5_CANFD01:5, compu {0=Cx0_Standby (CM_TME_HVHW_HVK_IstModus_Cx0_Standby), 1=Cx1_Regelung_aktiv (CM_TME_HVHW_HVK_IstModus_Cx1_Regelung_aktiv), 2=Cx2_Freigabe_ausgesetzt (CM_TME_HVHW_HVK_IstModus_Cx2_Freigabe_ausgesetzt), 5=Cx5_Fehler (CM_TME_HVHW_HVK_IstModus_Cx5_Fehler), 7=Cx7_Init (CM_TME_HVHW_HVK_IstModus_Cx7_Init)}, range raw 0..7, transfer-property=PENDING  # Istmodus des HV-Heizers
          signal TME_HVHW_HVK_EoHVL_Status_XIX_Thermomanagement_01_XIX_HCP5_CANFD01: start 114, 2 bit, little-endian, data-type-policy=OVERRIDE, i-signal-type=PRIMITIVE, init-value=0, base-type=BT_TME_HVHW_HVK_EoHVL_Status, invalid-value=Invalid_TME_HVHW_HVK_EoHVL_Status_XIX_Thermomanagement_01_XIX_HCP5_CANFD01:3, compu {0=Cx0_Init (CM_TME_HVHW_HVK_EoHVL_Status_Cx0_Init), 1=Cx1_Uzwkr_kleiner_UEoHVL_Schwell (CM_TME_HVHW_HVK_EoHVL_Status_Cx1_Uzwkr_kleiner_UEoHVL_Schwell), 2=Cx2_Uzwkr_groesgleich_UEoHVL_Schwell (CM_TME_HVHW_HVK_EoHVL_Status_Cx2_Uzwkr_groesgleich_UEoHVL_Schwell), 3=Cx3_Fehler (CM_TME_HVHW_HVK_EoHVL_Status_Cx3_Fehler)}, range raw 0..3, transfer-property=PENDING  # HV-Heizer Erkennung offene HV-Leitung
          signal TME_HVHW_HVK_Fehler_HVIL_XIX_Thermomanagement_01_XIX_HCP5_CANFD01: start 116, 2 bit, little-endian, data-type-policy=OVERRIDE, i-signal-type=PRIMITIVE, init-value=3, base-type=BT_TME_HVHW_HVK_Fehler_HVIL, invalid-value=Invalid_TME_HVHW_HVK_Fehler_HVIL_XIX_Thermomanagement_01_XIX_HCP5_CANFD01:2, compu {0=Cx0_HVIL_geschlossen (CM_TME_HVHW_HVK_Fehler_HVIL_Cx0_HVIL_geschlossen), 1=Cx1_HVIL_offen (CM_TME_HVHW_HVK_Fehler_HVIL_Cx1_HVIL_offen), 2=Cx2_Fehler (CM_TME_HVHW_HVK_Fehler_HVIL_Cx2_Fehler), 3=Cx3_Init (CM_TME_HVHW_HVK_Fehler_HVIL_Cx3_Init)}, range raw 0..3, transfer-property=PENDING  # HV-Interlock-Status des HV-Heizers
          signal TME_HVHW_HVK_Status_Spgfreiheit_XIX_Thermomanagement_01_XIX_HCP5_CANFD01: start 118, 2 bit, little-endian, data-type-policy=OVERRIDE, i-signal-type=PRIMITIVE, init-value=0, base-type=BT_TME_HVHW_HVK_Status_Spgfreiheit, invalid-value=Invalid_TME_HVHW_HVK_Status_Spgfreiheit_XIX_Thermomanagement_01_XIX_HCP5_CANFD01:3, compu {0=Cx0_Init (CM_TME_HVHW_HVK_Status_Spgfreiheit_Cx0_Init), 1=Cx1_HV_Komponente_spannungsfrei (CM_TME_HVHW_HVK_Status_Spgfreiheit_Cx1_HV_Komponente_spannungsfrei), 2=Cx2_HV_Komp_nicht_spannungsfrei (CM_TME_HVHW_HVK_Status_Spgfreiheit_Cx2_HV_Komp_nicht_spannungsfrei), 3=Cx3_Fehler (CM_TME_HVHW_HVK_Status_Spgfreiheit_Cx3_Fehler)}, range raw 0..3, transfer-property=PENDING  # Status ueber Spannungsfreiheit des HV-Heizers
          signal TME_Batt_Kond_Verf_XIX_Thermomanagement_01_XIX_HCP5_CANFD01: start 120, 3 bit, little-endian, data-type-policy=OVERRIDE, i-signal-type=PRIMITIVE, init-value=0, base-type=BT_TME_Batt_Kond_Verf, compu {0=Cx0_nicht_verfuegbar (CM_TME_Batt_Kond_Verf_Cx0_nicht_verfuegbar) (nicht verfügbar), 1=Cx1_passive_Kuehlung (CM_TME_Batt_Kond_Verf_Cx1_passive_Kuehlung) (passive Kühlung), 2=Cx2_aktive_Kuehlung (CM_TME_Batt_Kond_Verf_Cx2_aktive_Kuehlung) (aktive Kühlung), 4=Cx4_Heizen (CM_TME_Batt_Kond_Verf_Cx4_Heizen)}, range raw 0..4, transfer-property=PENDING, to BMC_HV(timeout 1 s)  # Verfügbarkeit der Vorkonditionierung der Batterie
          signal TME_HVHL_NTC_Warnung_XIX_Thermomanagement_01_XIX_HCP5_CANFD01: start 123, 1 bit, little-endian, data-type-policy=OVERRIDE, i-signal-type=PRIMITIVE, init-value=0, base-type=BT_TME_HVHL_NTC_Warnung, compu {0=Cx0_keine_Warnung (CM_TME_HVHL_NTC_Warnung_Cx0_keine_Warnung), 1=Cx1_Warnung_aktiv (CM_TME_HVHL_NTC_Warnung_Cx1_Warnung_aktiv)}, range raw 0..1, transfer-property=PENDING  # Warnung vor Leistungsreduzierung des HVHL und möglichem NTC-Verhalten
          signal TME_HVHW_HVK_Fehler_AE_XIX_Thermomanagement_01_XIX_HCP5_CANFD01: start 124, 2 bit, little-endian, data-type-policy=OVERRIDE, i-signal-type=PRIMITIVE, init-value=2, base-type=BT_TME_HVHW_HVK_Fehler_AE, invalid-value=Invalid_TME_HVHW_HVK_Fehler_AE_XIX_Thermomanagement_01_XIX_HCP5_CANFD01:1, compu {0=Cx0_kein_Fehler_AE (CM_TME_HVHW_HVK_Fehler_AE_Cx0_kein_Fehler_AE), 1=Cx1_Fehler (CM_TME_HVHW_HVK_Fehler_AE_Cx1_Fehler), 2=Cx2_Init (CM_TME_HVHW_HVK_Fehler_AE_Cx2_Init)}, range raw 0..2, transfer-property=TRIGGERED-ON-CHANGE  # Fehlerstatus aktive Entladung HV-PTC Wertebelegung
          signal TME_Klima_Red_Heizleistung_HVHL_XIX_Thermomanagement_01_XIX_HCP5_CANFD01: start 126, 2 bit, little-endian, data-type-policy=OVERRIDE, i-signal-type=PRIMITIVE, init-value=0, base-type=BT_TME_Klima_Red_Heizleistung_HVHL, compu {0=Cx0_keine_Reduzierung (CM_TME_Klima_Red_Heizleistung_HVHL_Cx0_keine_Reduzierung), 1=Cx1_Reduzierung_aktiv (CM_TME_Klima_Red_Heizleistung_HVHL_Cx1_Reduzierung_aktiv), 2=Cx2_Bankweises_Laden (CM_TME_Klima_Red_Heizleistung_HVHL_Cx2_Bankweises_Laden), 3=Cx3_Bankweises_Laden_PTC_kaltgeblasen (CM_TME_Klima_Red_Heizleistung_HVHL_Cx3_Bankweises_Laden_PTC_kaltgeblasen)}, range raw 0..3, transfer-property=PENDING  # Status reduzierte Heizleistung des HV-Luftheizers für die Innenraumklimatisierung
          signal TME_Verbrauch_gesamt_XIX_Thermomanagement_01_XIX_HCP5_CANFD01: start 128, 12 bit, little-endian, data-type-policy=OVERRIDE, i-signal-type=PRIMITIVE, init-value=0, base-type=BT_TME_Verbrauch_gesamt, compu {phys=raw for raw 0..4095; unit Unit_WattSecond}, range phys 0..4095 Unit_WattSecond, raw 0..4095, unit=Unit_WattSecond, transfer-property=TRIGGERED-ON-CHANGE-WITHOUT-REPETITION  # Energieverbrauch vom TME für Komfort- und Thermo-Bereich
          signal TME_Verbrauch_gesamt_Ueberlauf_XIX_Thermomanagement_01_XIX_HCP5_CANFD01: start 140, 1 bit, little-endian, data-type-policy=OVERRIDE, i-signal-type=PRIMITIVE, init-value=0, base-type=BT_TME_Verbrauch_gesamt_Ueberlauf, compu {0=Cx0_kein_Ueberlauf (CM_TME_Verbrauch_gesamt_Ueberlauf_Cx0_kein_Ueberlauf), 1=Cx1_Ueberlauf (CM_TME_Verbrauch_gesamt_Ueberlauf_Cx1_Ueberlauf)}, range raw 0..1, transfer-property=TRIGGERED-ON-CHANGE-WITHOUT-REPETITION  # Überlauf-Bit für das Signal TME_Verbrauch_gesamt
          signal EKK_HVK_Status_Spgfreiheit_XIX_Thermomanagement_01_XIX_HCP5_CANFD01: start 141, 2 bit, little-endian, data-type-policy=OVERRIDE, i-signal-type=PRIMITIVE, init-value=0, base-type=BT_EKK_HVK_Status_Spgfreiheit, invalid-value=Invalid_EKK_HVK_Status_Spgfreiheit_XIX_Thermomanagement_01_XIX_HCP5_CANFD01:3, compu {0=Cx0_Init (CM_EKK_HVK_Status_Spgfreiheit_Cx0_Init), 1=Cx1_HV_Komponente_spannungsfrei (CM_EKK_HVK_Status_Spgfreiheit_Cx1_HV_Komponente_spannungsfrei), 2=Cx2_HV_Komp_nicht_spannungsfrei (CM_EKK_HVK_Status_Spgfreiheit_Cx2_HV_Komp_nicht_spannungsfrei), 3=Cx3_Fehler (CM_EKK_HVK_Status_Spgfreiheit_Cx3_Fehler)}, range raw 0..3, transfer-property=TRIGGERED-ON-CHANGE-WITHOUT-REPETITION  # Status ueber Spannungsfreiheit des elektrischen Klimakompressors
          signal TME_HVHL_verfuegbar_XIX_Thermomanagement_01_XIX_HCP5_CANFD01: start 143, 1 bit, little-endian, data-type-policy=OVERRIDE, i-signal-type=PRIMITIVE, init-value=0, base-type=BT_TME_HVHL_verfuegbar, compu {0=Cx0_nicht_verfuegbar (CM_TME_HVHL_verfuegbar_Cx0_nicht_verfuegbar), 1=Cx1_verfuegbar (CM_TME_HVHL_verfuegbar_Cx1_verfuegbar)}, range raw 0..1, transfer-property=PENDING  # HV-Luftheizer verfuegbar
          signal HVHL_HVK_Status_Spgfreiheit_XIX_Thermomanagement_01_XIX_HCP5_CANFD01: start 144, 2 bit, little-endian, data-type-policy=OVERRIDE, i-signal-type=PRIMITIVE, init-value=0, base-type=BT_HVHL_HVK_Status_Spgfreiheit, invalid-value=Invalid_HVHL_HVK_Status_Spgfreiheit_XIX_Thermomanagement_01_XIX_HCP5_CANFD01:3, compu {0=Cx0_Init (CM_HVHL_HVK_Status_Spgfreiheit_Cx0_Init), 1=Cx1_HV_Komponente_spannungsfrei (CM_HVHL_HVK_Status_Spgfreiheit_Cx1_HV_Komponente_spannungsfrei), 2=Cx2_HV_Komp_nicht_spannungsfrei (CM_HVHL_HVK_Status_Spgfreiheit_Cx2_HV_Komp_nicht_spannungsfrei), 3=Cx3_Fehler (CM_HVHL_HVK_Status_Spgfreiheit_Cx3_Fehler)}, range raw 0..3, transfer-property=TRIGGERED-ON-CHANGE-WITHOUT-REPETITION  # Status ueber Spannungsfreiheit des HV-Luftheizers
          signal TME_NT_Kreis_Status_XIX_Thermomanagement_01_XIX_HCP5_CANFD01: start 146, 1 bit, little-endian, data-type-policy=OVERRIDE, i-signal-type=PRIMITIVE, init-value=0, base-type=BT_TME_NT_Kreis_Status, invalid-value=Invalid_TME_NT_Kreis_Status_XIX_Thermomanagement_01_XIX_HCP5_CANFD01:1, compu {0=Cx0_kein_Fehler (CM_TME_NT_Kreis_Status_Cx0_kein_Fehler), 1=Cx1_Fehler (CM_TME_NT_Kreis_Status_Cx1_Fehler)}, range raw 0..1, transfer-property=PENDING  # Status gibt an ob der NT Kreis funktional i.O ist. (Komponenten i.O)
          signal TME_ELM1_IstVolumenstrom_XIX_Thermomanagement_01_XIX_HCP5_CANFD01: start 147, 5 bit, little-endian, data-type-policy=OVERRIDE, i-signal-type=PRIMITIVE, init-value=30, base-type=BT_TME_ELM1_IstVolumenstrom, invalid-value=Invalid_TME_ELM1_IstVolumenstrom_XIX_Thermomanagement_01_XIX_HCP5_CANFD01:31, compu {phys=raw*0.5 for raw 0..29, 30=Cx1e_Init (CM_TME_ELM1_IstVolumenstrom_Cx1e_Init), 31=Cx1f_Fehler (CM_TME_ELM1_IstVolumenstrom_Cx1f_Fehler); unit Unit_LiterPerMinut}, range phys 0..14.5 Unit_LiterPerMinut, raw 0..31, unit=Unit_LiterPerMinut, transfer-property=PENDING  # Ist-Volumenstrom Kuehlkreis Leistungselektronik
          signal TME_ELM2_IstVolumenstrom_XIX_Thermomanagement_01_XIX_HCP5_CANFD01: start 152, 5 bit, little-endian, data-type-policy=OVERRIDE, i-signal-type=PRIMITIVE, init-value=30, base-type=BT_TME_ELM2_IstVolumenstrom, invalid-value=Invalid_TME_ELM2_IstVolumenstrom_XIX_Thermomanagement_01_XIX_HCP5_CANFD01:31, compu {phys=raw*0.5 for raw 0..29, 30=Cx1e_Init (CM_TME_ELM2_IstVolumenstrom_Cx1e_Init), 31=Cx1f_Fehler (CM_TME_ELM2_IstVolumenstrom_Cx1f_Fehler); unit Unit_LiterPerMinut}, range phys 0..14.5 Unit_LiterPerMinut, raw 0..31, unit=Unit_LiterPerMinut, transfer-property=PENDING  # Ist-Volumenstrom Kuehlkreis Leistungselektronik
          signal TME_ELM3_IstVolumenstrom_XIX_Thermomanagement_01_XIX_HCP5_CANFD01: start 157, 5 bit, little-endian, data-type-policy=OVERRIDE, i-signal-type=PRIMITIVE, init-value=30, base-type=BT_TME_ELM3_IstVolumenstrom, invalid-value=Invalid_TME_ELM3_IstVolumenstrom_XIX_Thermomanagement_01_XIX_HCP5_CANFD01:31, compu {phys=raw*0.5 for raw 0..29, 30=Cx1e_Init (CM_TME_ELM3_IstVolumenstrom_Cx1e_Init), 31=Cx1f_Fehler (CM_TME_ELM3_IstVolumenstrom_Cx1f_Fehler); unit Unit_LiterPerMinut}, range phys 0..14.5 Unit_LiterPerMinut, raw 0..31, unit=Unit_LiterPerMinut, transfer-property=PENDING  # Ist-Volumenstrom Kuehlkreis Leistungselektronik
          signal TME_Temp_KM_vor_LE_XIX_Thermomanagement_01_XIX_HCP5_CANFD01: start 162, 8 bit, little-endian, data-type-policy=OVERRIDE, i-signal-type=PRIMITIVE, init-value=254, base-type=BT_TME_Temp_KM_vor_LE, invalid-value=Invalid_TME_Temp_KM_vor_LE_XIX_Thermomanagement_01_XIX_HCP5_CANFD01:255, compu {phys=raw*0.75-48 for raw 0..253, 254=Cxfe_Init (CM_TME_Temp_KM_vor_LE_Cxfe_Init), 255=Cxff_Fehler (CM_TME_Temp_KM_vor_LE_Cxff_Fehler); unit Unit_DegreCelsi}, range phys -48..141.75 Unit_DegreCelsi, raw 0..255, unit=Unit_DegreCelsi, transfer-property=PENDING  # Kuehlmittelvorlauftemperatur vor der Leistungselektronik
          signal TME_Temp_nach_Heizung_Front_XIX_Thermomanagement_01_XIX_HCP5_CANFD01: start 170, 10 bit, little-endian, data-type-policy=OVERRIDE, i-signal-type=PRIMITIVE, init-value=1022, base-type=BT_TME_Temp_nach_Heizung_Front, invalid-value=Invalid_TME_Temp_nach_Heizung_Front_XIX_Thermomanagement_01_XIX_HCP5_CANFD01:1023, compu {phys=raw*0.1-20 for raw 0..1021, 1022=Cx3fe_Init (CM_TME_Temp_nach_Heizung_Front_Cx3fe_Init), 1023=Cx3ff_Fehler (CM_TME_Temp_nach_Heizung_Front_Cx3ff_Fehler); unit Unit_DegreCelsi}, range phys -20..82.1 Unit_DegreCelsi, raw 0..1023, unit=Unit_DegreCelsi, transfer-property=PENDING  # Lufttemperatur nach Heizungswaermetauscher Front
          signal TME_Temp_nach_Verdampfer_Front_XIX_Thermomanagement_01_XIX_HCP5_CANFD01: start 180, 10 bit, little-endian, data-type-policy=OVERRIDE, i-signal-type=PRIMITIVE, init-value=1022, base-type=BT_TME_Temp_nach_Verdampfer_Front, invalid-value=Invalid_TME_Temp_nach_Verdampfer_Front_XIX_Thermomanagement_01_XIX_HCP5_CANFD01:1023, compu {phys=raw*0.1-20 for raw 0..900, 1022=Cx3fe_Init (CM_TME_Temp_nach_Verdampfer_Front_Cx3fe_Init), 1023=Cx3ff_Fehler (CM_TME_Temp_nach_Verdampfer_Front_Cx3ff_Fehler); unit Unit_DegreCelsi}, range phys -20..70 Unit_DegreCelsi, raw 0..1023, unit=Unit_DegreCelsi, transfer-property=PENDING  # Lufttemperatur nach Frontverdampfer
          signal TME_Temp_nach_HVH_Heizk1_1_XIX_Thermomanagement_01_XIX_HCP5_CANFD01: start 190, 10 bit, little-endian, data-type-policy=OVERRIDE, i-signal-type=PRIMITIVE, init-value=1022, base-type=BT_TME_Temp_nach_HVH_Heizk1_1, invalid-value=Invalid_TME_Temp_nach_HVH_Heizk1_1_XIX_Thermomanagement_01_XIX_HCP5_CANFD01:1023, compu {phys=raw*0.2-40 for raw 0..1021, 1022=Cx3fe_Init (CM_TME_Temp_nach_HVH_Heizk1_1_Cx3fe_Init), 1023=Cx3ff_Fehler (CM_TME_Temp_nach_HVH_Heizk1_1_Cx3ff_Fehler); unit Unit_DegreCelsi}, range phys -40..164.2 Unit_DegreCelsi, raw 0..1023, unit=Unit_DegreCelsi, transfer-property=PENDING  # Lufttemperatur nach Heizungswaermetauscher Front
          signal TME_Temp_nach_HVH_Heizk1_2_XIX_Thermomanagement_01_XIX_HCP5_CANFD01: start 200, 10 bit, little-endian, data-type-policy=OVERRIDE, i-signal-type=PRIMITIVE, init-value=1022, base-type=BT_TME_Temp_nach_HVH_Heizk1_2, invalid-value=Invalid_TME_Temp_nach_HVH_Heizk1_2_XIX_Thermomanagement_01_XIX_HCP5_CANFD01:1023, compu {phys=raw*0.2-40 for raw 0..1021, 1022=Cx3fe_Init (CM_TME_Temp_nach_HVH_Heizk1_2_Cx3fe_Init), 1023=Cx3ff_Fehler (CM_TME_Temp_nach_HVH_Heizk1_2_Cx3ff_Fehler); unit Unit_DegreCelsi}, range phys -40..164.2 Unit_DegreCelsi, raw 0..1023, unit=Unit_DegreCelsi, transfer-property=PENDING  # Lufttemperatur nach Heizungswaermetauscher Front
          signal TME_Temp_nach_HVH_Heizk2_1_XIX_Thermomanagement_01_XIX_HCP5_CANFD01: start 210, 10 bit, little-endian, data-type-policy=OVERRIDE, i-signal-type=PRIMITIVE, init-value=1022, base-type=BT_TME_Temp_nach_HVH_Heizk2_1, invalid-value=Invalid_TME_Temp_nach_HVH_Heizk2_1_XIX_Thermomanagement_01_XIX_HCP5_CANFD01:1023, compu {phys=raw*0.2-40 for raw 0..1021, 1022=Cx3fe_Init (CM_TME_Temp_nach_HVH_Heizk2_1_Cx3fe_Init), 1023=Cx3ff_Fehler (CM_TME_Temp_nach_HVH_Heizk2_1_Cx3ff_Fehler); unit Unit_DegreCelsi}, range phys -40..164.2 Unit_DegreCelsi, raw 0..1023, unit=Unit_DegreCelsi, transfer-property=PENDING  # Lufttemperatur nach Heizungswaermetauscher Front
          signal TME_Temp_nach_HVH_Heizk2_2_XIX_Thermomanagement_01_XIX_HCP5_CANFD01: start 220, 10 bit, little-endian, data-type-policy=OVERRIDE, i-signal-type=PRIMITIVE, init-value=1022, base-type=BT_TME_Temp_nach_HVH_Heizk2_2, invalid-value=Invalid_TME_Temp_nach_HVH_Heizk2_2_XIX_Thermomanagement_01_XIX_HCP5_CANFD01:1023, compu {phys=raw*0.2-40 for raw 0..1021, 1022=Cx3fe_Init (CM_TME_Temp_nach_HVH_Heizk2_2_Cx3fe_Init), 1023=Cx3ff_Fehler (CM_TME_Temp_nach_HVH_Heizk2_2_Cx3ff_Fehler); unit Unit_DegreCelsi}, range phys -40..164.2 Unit_DegreCelsi, raw 0..1023, unit=Unit_DegreCelsi, transfer-property=PENDING  # Lufttemperatur nach Heizungswaermetauscher Front
          signal TME_Temp_nach_HVH_Heizk3_1_XIX_Thermomanagement_01_XIX_HCP5_CANFD01: start 230, 10 bit, little-endian, data-type-policy=OVERRIDE, i-signal-type=PRIMITIVE, init-value=1022, base-type=BT_TME_Temp_nach_HVH_Heizk3_1, invalid-value=Invalid_TME_Temp_nach_HVH_Heizk3_1_XIX_Thermomanagement_01_XIX_HCP5_CANFD01:1023, compu {phys=raw*0.2-40 for raw 0..1021, 1022=Cx3fe_Init (CM_TME_Temp_nach_HVH_Heizk3_1_Cx3fe_Init), 1023=Cx3ff_Fehler (CM_TME_Temp_nach_HVH_Heizk3_1_Cx3ff_Fehler); unit Unit_DegreCelsi}, range phys -40..164.2 Unit_DegreCelsi, raw 0..1023, unit=Unit_DegreCelsi, transfer-property=PENDING  # Lufttemperatur nach Heizungswaermetauscher Front
          signal TME_Temp_nach_HVH_Heizk3_2_XIX_Thermomanagement_01_XIX_HCP5_CANFD01: start 240, 10 bit, little-endian, data-type-policy=OVERRIDE, i-signal-type=PRIMITIVE, init-value=1022, base-type=BT_TME_Temp_nach_HVH_Heizk3_2, invalid-value=Invalid_TME_Temp_nach_HVH_Heizk3_2_XIX_Thermomanagement_01_XIX_HCP5_CANFD01:1023, compu {phys=raw*0.2-40 for raw 0..1021, 1022=Cx3fe_Init (CM_TME_Temp_nach_HVH_Heizk3_2_Cx3fe_Init), 1023=Cx3ff_Fehler (CM_TME_Temp_nach_HVH_Heizk3_2_Cx3ff_Fehler); unit Unit_DegreCelsi}, range phys -40..164.2 Unit_DegreCelsi, raw 0..1023, unit=Unit_DegreCelsi, transfer-property=PENDING  # Lufttemperatur nach Heizungswaermetauscher Front
          signal TME_Temp_nach_HVH_Heizk4_1_XIX_Thermomanagement_01_XIX_HCP5_CANFD01: start 250, 10 bit, little-endian, data-type-policy=OVERRIDE, i-signal-type=PRIMITIVE, init-value=1022, base-type=BT_TME_Temp_nach_HVH_Heizk4_1, invalid-value=Invalid_TME_Temp_nach_HVH_Heizk4_1_XIX_Thermomanagement_01_XIX_HCP5_CANFD01:1023, compu {phys=raw*0.2-40 for raw 0..1021, 1022=Cx3fe_Init (CM_TME_Temp_nach_HVH_Heizk4_1_Cx3fe_Init), 1023=Cx3ff_Fehler (CM_TME_Temp_nach_HVH_Heizk4_1_Cx3ff_Fehler); unit Unit_DegreCelsi}, range phys -40..164.2 Unit_DegreCelsi, raw 0..1023, unit=Unit_DegreCelsi, transfer-property=PENDING  # Lufttemperatur nach Heizungswaermetauscher Front
          signal TME_Temp_nach_HVH_Heizk4_2_XIX_Thermomanagement_01_XIX_HCP5_CANFD01: start 260, 10 bit, little-endian, data-type-policy=OVERRIDE, i-signal-type=PRIMITIVE, init-value=1022, base-type=BT_TME_Temp_nach_HVH_Heizk4_2, invalid-value=Invalid_TME_Temp_nach_HVH_Heizk4_2_XIX_Thermomanagement_01_XIX_HCP5_CANFD01:1023, compu {phys=raw*0.2-40 for raw 0..1021, 1022=Cx3fe_Init (CM_TME_Temp_nach_HVH_Heizk4_2_Cx3fe_Init), 1023=Cx3ff_Fehler (CM_TME_Temp_nach_HVH_Heizk4_2_Cx3ff_Fehler); unit Unit_DegreCelsi}, range phys -40..164.2 Unit_DegreCelsi, raw 0..1023, unit=Unit_DegreCelsi, transfer-property=PENDING  # Lufttemperatur nach Heizungswaermetauscher Front
          signal TME_HVEM_Minleistung_XIX_Thermomanagement_01_XIX_HCP5_CANFD01: start 270, 9 bit, little-endian, data-type-policy=OVERRIDE, i-signal-type=PRIMITIVE, init-value=510, base-type=BT_TME_HVEM_Minleistung, invalid-value=Invalid_TME_HVEM_Minleistung_XIX_Thermomanagement_01_XIX_HCP5_CANFD01:511, compu {phys=raw*100 for raw 0..509, 510=Cx1fe_Init (CM_TME_HVEM_Minleistung_Cx1fe_Init), 511=Cx1ff_Fehler (CM_TME_HVEM_Minleistung_Cx1ff_Fehler); unit Unit_Watt}, range phys 0..50900 Unit_Watt, raw 0..511, unit=Unit_Watt, transfer-property=PENDING  # Angeforderte MinLeistung der TME an das HVEM
          signal TME_HVEM_Wunschleistung_XIX_Thermomanagement_01_XIX_HCP5_CANFD01: start 279, 9 bit, little-endian, data-type-policy=OVERRIDE, i-signal-type=PRIMITIVE, init-value=510, base-type=BT_TME_HVEM_Wunschleistung, invalid-value=Invalid_TME_HVEM_Wunschleistung_XIX_Thermomanagement_01_XIX_HCP5_CANFD01:511, compu {phys=raw*100 for raw 0..509, 510=Cx1fe_Init (CM_TME_HVEM_Wunschleistung_Cx1fe_Init), 511=Cx1ff_Fehler (CM_TME_HVEM_Wunschleistung_Cx1ff_Fehler); unit Unit_Watt}, range phys 0..50900 Unit_Watt, raw 0..511, unit=Unit_Watt, transfer-property=PENDING  # Angeforderte Leistung der TME an das HVEM
          signal TME_OBD_Lampe_Anf_XIX_Thermomanagement_01_XIX_HCP5_CANFD01: start 288, 1 bit, little-endian, data-type-policy=OVERRIDE, i-signal-type=PRIMITIVE, init-value=0, base-type=BT_TME_OBD_Lampe_Anf, compu {0=Cx0_kein_MIL_Request (CM_TME_OBD_Lampe_Anf_Cx0_kein_MIL_Request), 1=Cx1_MIL_Request (CM_TME_OBD_Lampe_Anf_Cx1_MIL_Request)}, range raw 0..1, transfer-property=PENDING  # MIL-Request durch TME-Steuergerät
          signal TME_Therm_IstLeistung_HVBatterie_XIX_Thermomanagement_01_XIX_HCP5_CANFD01: start 289, 9 bit, little-endian, data-type-policy=OVERRIDE, i-signal-type=PRIMITIVE, init-value=510, base-type=BT_TME_Therm_IstLeistung_HVBatterie, invalid-value=Invalid_TME_Therm_IstLeistung_HVBatterie_XIX_Thermomanagement_01_XIX_HCP5_CANFD01:511, compu {phys=raw*100-25500 for raw 0..509, 510=Cx1fe_Init (CM_TME_Therm_IstLeistung_HVBatterie_Cx1fe_Init), 511=Cx1ff_Fehler (CM_TME_Therm_IstLeistung_HVBatterie_Cx1ff_Fehler); unit Unit_Watt}, range phys -25500..25400 Unit_Watt, raw 0..511, unit=Unit_Watt, transfer-property=PENDING, to BMC_HV(timeout 1 s)  # aktuelle thermische Leistung über HV-Batterie(positiv - Wärmeeintrag, negativ - Wärmeentzug)
          signal TME_HVEM_Rekuleistung_XIX_Thermomanagement_01_XIX_HCP5_CANFD01: start 298, 9 bit, little-endian, data-type-policy=OVERRIDE, i-signal-type=PRIMITIVE, init-value=510, base-type=BT_TME_HVEM_Rekuleistung, invalid-value=Invalid_TME_HVEM_Rekuleistung_XIX_Thermomanagement_01_XIX_HCP5_CANFD01:511, compu {phys=raw*100 for raw 0..509, 510=Cx1fe_Init (CM_TME_HVEM_Rekuleistung_Cx1fe_Init), 511=Cx1ff_Fehler (CM_TME_HVEM_Rekuleistung_Cx1ff_Fehler); unit Unit_Watt}, range phys 0..50900 Unit_Watt, raw 0..511, unit=Unit_Watt, transfer-property=PENDING  # HV-Istleistung seitens Thermoamanagement, die als Rekuleistung verwendet werden kann
          signal TME_HV_IstLeistung_EKK_XIX_Thermomanagement_01_XIX_HCP5_CANFD01: start 307, 7 bit, little-endian, data-type-policy=OVERRIDE, i-signal-type=PRIMITIVE, init-value=126, base-type=BT_TME_HV_IstLeistung_EKK, invalid-value=Invalid_TME_HV_IstLeistung_EKK_XIX_Thermomanagement_01_XIX_HCP5_CANFD01:127, compu {phys=raw*100 for raw 0..125, 126=Cx7e_Init (CM_TME_HV_IstLeistung_EKK_Cx7e_Init), 127=Cx7f_Fehler (CM_TME_HV_IstLeistung_EKK_Cx7f_Fehler); unit Unit_Watt}, range phys 0..12500 Unit_Watt, raw 0..127, unit=Unit_Watt, transfer-property=PENDING  # aktuelle elektrische Leistung HV-Kältemittelverdichter
          signal TME_HV_IstLeistung_HVHL_XIX_Thermomanagement_01_XIX_HCP5_CANFD01: start 314, 7 bit, little-endian, data-type-policy=OVERRIDE, i-signal-type=PRIMITIVE, init-value=126, base-type=BT_TME_HV_IstLeistung_HVHL, invalid-value=Invalid_TME_HV_IstLeistung_HVHL_XIX_Thermomanagement_01_XIX_HCP5_CANFD01:127, compu {phys=raw*100 for raw 0..125, 126=Cx7e_Init (CM_TME_HV_IstLeistung_HVHL_Cx7e_Init), 127=Cx7f_Fehler (CM_TME_HV_IstLeistung_HVHL_Cx7f_Fehler); unit Unit_Watt}, range phys 0..12500 Unit_Watt, raw 0..127, unit=Unit_Watt, transfer-property=PENDING  # aktuelle elektrische HV-Leistung HV-Luftheizer
          signal TME_LED_STK_XIX_Thermomanagement_01_XIX_HCP5_CANFD01: start 321, 3 bit, little-endian, data-type-policy=OVERRIDE, i-signal-type=PRIMITIVE, init-value=6, base-type=BT_TME_LED_STK, compu {0=Cx0_LED_aus (CM_TME_LED_STK_Cx0_LED_aus), 1=Cx1_LED_ein (CM_TME_LED_STK_Cx1_LED_ein), 2=Cx2_LED_blinken (CM_TME_LED_STK_Cx2_LED_blinken), 3=Cx3_Funktion_gesperrt_LED_aus (CM_TME_LED_STK_Cx3_Funktion_gesperrt_LED_aus), 6=Cx6_Init (CM_TME_LED_STK_Cx6_Init)}, range raw 0..6, transfer-property=TRIGGERED-ON-CHANGE  # Funktionsbeleuchtung Standklimatisierungstaste
          signal TME_LED_STK_Timer_XIX_Thermomanagement_01_XIX_HCP5_CANFD01: start 324, 3 bit, little-endian, data-type-policy=OVERRIDE, i-signal-type=PRIMITIVE, init-value=6, base-type=BT_TME_LED_STK_Timer, compu {0=Cx0_LED_aus (CM_TME_LED_STK_Timer_Cx0_LED_aus), 1=Cx1_LED_ein (CM_TME_LED_STK_Timer_Cx1_LED_ein), 2=Cx2_LED_blinken (CM_TME_LED_STK_Timer_Cx2_LED_blinken), 3=Cx3_Funktion_gesperrt_LED_aus (CM_TME_LED_STK_Timer_Cx3_Funktion_gesperrt_LED_aus), 6=Cx6_Init (CM_TME_LED_STK_Timer_Cx6_Init)}, range raw 0..6, transfer-property=TRIGGERED-ON-CHANGE  # Funktionsbeleuchtung Standklimatisierungstaste fuer Timer Symbol
          signal TME_HV_IstLeistung_BTL_XIX_Thermomanagement_01_XIX_HCP5_CANFD01: start 327, 9 bit, little-endian, data-type-policy=OVERRIDE, i-signal-type=PRIMITIVE, init-value=510, base-type=BT_TME_HV_IstLeistung_BTL, invalid-value=Invalid_TME_HV_IstLeistung_BTL_XIX_Thermomanagement_01_XIX_HCP5_CANFD01:511, compu {phys=raw*50 for raw 0..509, 510=Cx1fe_Init (CM_TME_HV_IstLeistung_BTL_Cx1fe_Init), 511=Cx1ff_Fehler (CM_TME_HV_IstLeistung_BTL_Cx1ff_Fehler); unit Unit_Watt}, range phys 0..25450 Unit_Watt, raw 0..511, unit=Unit_Watt, transfer-property=PENDING  # aktuelle elektrische HV-Leistung für Bauteilkonditionierung
          signal TME_HV_IstLeistung_Komfort_XIX_Thermomanagement_01_XIX_HCP5_CANFD01: start 336, 9 bit, little-endian, data-type-policy=OVERRIDE, i-signal-type=PRIMITIVE, init-value=510, base-type=BT_TME_HV_IstLeistung_Komfort, invalid-value=Invalid_TME_HV_IstLeistung_Komfort_XIX_Thermomanagement_01_XIX_HCP5_CANFD01:511, compu {phys=raw*50 for raw 0..509, 510=Cx1fe_Init (CM_TME_HV_IstLeistung_Komfort_Cx1fe_Init), 511=Cx1ff_Fehler (CM_TME_HV_IstLeistung_Komfort_Cx1ff_Fehler); unit Unit_Watt}, range phys 0..25450 Unit_Watt, raw 0..511, unit=Unit_Watt, transfer-property=PENDING  # aktuelle elektrische HV-Leistung für Innenraumklimatisierung
          signal TME_eKMV_Istmodus_XIX_Thermomanagement_01_XIX_HCP5_CANFD01: start 345, 3 bit, little-endian, data-type-policy=OVERRIDE, i-signal-type=PRIMITIVE, init-value=7, base-type=BT_TME_eKMV_Istmodus, invalid-value=Invalid_TME_eKMV_Istmodus_XIX_Thermomanagement_01_XIX_HCP5_CANFD01:5, compu {0=Cx0_Standby (CM_TME_eKMV_Istmodus_Cx0_Standby), 1=Cx1_Regelung_aktiv (CM_TME_eKMV_Istmodus_Cx1_Regelung_aktiv), 2=Cx2_Freigabe_ausgesetzt (CM_TME_eKMV_Istmodus_Cx2_Freigabe_ausgesetzt), 5=Cx5_Fehler (CM_TME_eKMV_Istmodus_Cx5_Fehler), 7=Cx7_Init (CM_TME_eKMV_Istmodus_Cx7_Init)}, range raw 0..7, transfer-property=PENDING  # aktuelle IstModus des eKMV
          signal TME_eKMV_Spannung_XIX_Thermomanagement_01_XIX_HCP5_CANFD01: start 348, 9 bit, little-endian, data-type-policy=OVERRIDE, i-signal-type=PRIMITIVE, init-value=510, base-type=BT_TME_eKMV_Spannung, invalid-value=Invalid_TME_eKMV_Spannung_XIX_Thermomanagement_01_XIX_HCP5_CANFD01:511, compu {phys=raw*0.2 for raw 0..509, 510=Cx1fe_Init (CM_TME_eKMV_Spannung_Cx1fe_Init), 511=Cx1ff_Fehler (CM_TME_eKMV_Spannung_Cx1ff_Fehler); unit Unit_Volt}, range phys 0..101.8 Unit_Volt, raw 0..511, unit=Unit_Volt, transfer-property=PENDING  # Gemessene Spannung des eKMV
          signal TME_eKMV_Strom_XIX_Thermomanagement_01_XIX_HCP5_CANFD01: start 357, 8 bit, little-endian, data-type-policy=OVERRIDE, i-signal-type=PRIMITIVE, init-value=254, base-type=BT_TME_eKMV_Strom, invalid-value=Invalid_TME_eKMV_Strom_XIX_Thermomanagement_01_XIX_HCP5_CANFD01:255, compu {phys=raw*0.75 for raw 0..253, 254=Cxfe_Init (CM_TME_eKMV_Strom_Cxfe_Init), 255=Cxff_Fehler (CM_TME_eKMV_Strom_Cxff_Fehler); unit Unit_Amper}, range phys 0..189.75 Unit_Amper, raw 0..255, unit=Unit_Amper, transfer-property=PENDING  # Gemessener Strom des eKMV
          signal TME_HVEM_Abschaltleistung_XIX_Thermomanagement_01_XIX_HCP5_CANFD01: start 365, 9 bit, little-endian, data-type-policy=OVERRIDE, i-signal-type=PRIMITIVE, init-value=510, base-type=BT_TME_HVEM_Abschaltleistung, invalid-value=Invalid_TME_HVEM_Abschaltleistung_XIX_Thermomanagement_01_XIX_HCP5_CANFD01:511, compu {phys=raw*50 for raw 0..509, 510=Cx1fe_Init (CM_TME_HVEM_Abschaltleistung_Cx1fe_Init), 511=Cx1ff_Fehler (CM_TME_HVEM_Abschaltleistung_Cx1ff_Fehler); unit Unit_Watt}, range phys 0..25450 Unit_Watt, raw 0..511, unit=Unit_Watt, transfer-property=PENDING  # mögliche Abschaltleistung seitens TME im Fall Kickdown/Launch control
          signal TME_MSF_Stufe_XIX_Thermomanagement_01_XIX_HCP5_CANFD01: start 374, 2 bit, little-endian, data-type-policy=OVERRIDE, i-signal-type=PRIMITIVE, init-value=0, base-type=BT_TME_MSF_Stufe, compu {0=Cx0_Init (CM_TME_MSF_Stufe_Cx0_Init), 1=Cx1_Stufe_1 (CM_TME_MSF_Stufe_Cx1_Stufe_1) (Stufe 1), 2=Cx2_Stufe_2 (CM_TME_MSF_Stufe_Cx2_Stufe_2) (Stufe 2), 3=Cx3_reserve (CM_TME_MSF_Stufe_Cx3_reserve)}, range raw 0..3, transfer-property=PENDING  # Leistungsstufe in der Mindestschubfunktion seitens TME
          signal TME_MVEM_MinLeistung_XIX_Thermomanagement_01_XIX_HCP5_CANFD01: start 376, 8 bit, little-endian, data-type-policy=OVERRIDE, i-signal-type=PRIMITIVE, init-value=254, base-type=BT_TME_MVEM_MinLeistung, invalid-value=Invalid_TME_MVEM_MinLeistung_XIX_Thermomanagement_01_XIX_HCP5_CANFD01:255, compu {phys=raw*50 for raw 0..253, 254=Cxfe_Init (CM_TME_MVEM_MinLeistung_Cxfe_Init), 255=Cxff_Fehler (CM_TME_MVEM_MinLeistung_Cxff_Fehler); unit Unit_Watt}, range phys 0..12650 Unit_Watt, raw 0..255, unit=Unit_Watt, transfer-property=PENDING  # MV Leistungsbedarf des TME-Systemes für Kllimatisierung/Batteriekühlung
          signal TME_MVEM_Wunschleistung_XIX_Thermomanagement_01_XIX_HCP5_CANFD01: start 384, 8 bit, little-endian, data-type-policy=OVERRIDE, i-signal-type=PRIMITIVE, init-value=254, base-type=BT_TME_MVEM_Wunschleistung, invalid-value=Invalid_TME_MVEM_Wunschleistung_XIX_Thermomanagement_01_XIX_HCP5_CANFD01:255, compu {phys=raw*50 for raw 0..253, 254=Cxfe_Init (CM_TME_MVEM_Wunschleistung_Cxfe_Init), 255=Cxff_Fehler (CM_TME_MVEM_Wunschleistung_Cxff_Fehler); unit Unit_Watt}, range phys 0..12650 Unit_Watt, raw 0..255, unit=Unit_Watt, transfer-property=PENDING  # MV Wunschleistung des TME-Systemes für Kllimatisierung
          signal TME_MVH_L_Istmodus_XIX_Thermomanagement_01_XIX_HCP5_CANFD01: start 392, 3 bit, little-endian, data-type-policy=OVERRIDE, i-signal-type=PRIMITIVE, init-value=7, base-type=BT_TME_MVH_L_Istmodus, invalid-value=Invalid_TME_MVH_L_Istmodus_XIX_Thermomanagement_01_XIX_HCP5_CANFD01:5, compu {0=Cx0_Standby (CM_TME_MVH_L_Istmodus_Cx0_Standby), 1=Cx1_Regelung_aktiv (CM_TME_MVH_L_Istmodus_Cx1_Regelung_aktiv), 2=Cx2_Freigabe_ausgesetzt (CM_TME_MVH_L_Istmodus_Cx2_Freigabe_ausgesetzt), 5=Cx5_Fehler (CM_TME_MVH_L_Istmodus_Cx5_Fehler), 7=Cx7_Init (CM_TME_MVH_L_Istmodus_Cx7_Init)}, range raw 0..7, transfer-property=PENDING  # aktueller Ist-Modus des MVH_L
          signal TME_MVH_L_Spannung_XIX_Thermomanagement_01_XIX_HCP5_CANFD01: start 395, 8 bit, little-endian, data-type-policy=OVERRIDE, i-signal-type=PRIMITIVE, init-value=254, base-type=BT_TME_MVH_L_Spannung, invalid-value=Invalid_TME_MVH_L_Spannung_XIX_Thermomanagement_01_XIX_HCP5_CANFD01:255, compu {phys=raw*0.25 for raw 0..253, 254=Cxfe_Init (CM_TME_MVH_L_Spannung_Cxfe_Init), 255=Cxff_Fehler (CM_TME_MVH_L_Spannung_Cxff_Fehler); unit Unit_Volt}, range phys 0..63.25 Unit_Volt, raw 0..255, unit=Unit_Volt, transfer-property=PENDING  # Gemessene Spannung des MVH_L
          signal TME_MVH_L_Strom_XIX_Thermomanagement_01_XIX_HCP5_CANFD01: start 403, 9 bit, little-endian, data-type-policy=OVERRIDE, i-signal-type=PRIMITIVE, init-value=510, base-type=BT_TME_MVH_L_Strom, invalid-value=Invalid_TME_MVH_L_Strom_XIX_Thermomanagement_01_XIX_HCP5_CANFD01:511, compu {phys=raw*0.25 for raw 0..509, 510=Cx1fe_Init (CM_TME_MVH_L_Strom_Cx1fe_Init), 511=Cx1ff_Fehler (CM_TME_MVH_L_Strom_Cx1ff_Fehler); unit Unit_Amper}, range phys 0..127.25 Unit_Amper, raw 0..511, unit=Unit_Amper, transfer-property=PENDING  # Gemessener Strom des MVH_L
          signal TME_ZR_Anforderung_XIX_Thermomanagement_01_XIX_HCP5_CANFD01: start 412, 2 bit, little-endian, data-type-policy=OVERRIDE, i-signal-type=PRIMITIVE, init-value=0, base-type=BT_TME_ZR_Anforderung, compu {0=Cx0_Init (CM_TME_ZR_Anforderung_Cx0_Init), 1=Cx1_Inaktiv (CM_TME_ZR_Anforderung_Cx1_Inaktiv), 2=Cx2_Aktiv (CM_TME_ZR_Anforderung_Cx2_Aktiv), 3=Cx3_Reseviert (CM_TME_ZR_Anforderung_Cx3_Reseviert)}, range raw 0..3, transfer-property=PENDING  # Anforderung an MIB die Displays zu aktivieren
          signal TME_HV_Anf_XIX_Thermomanagement_01_XIX_HCP5_CANFD01: start 414, 2 bit, little-endian, data-type-policy=OVERRIDE, i-signal-type=PRIMITIVE, init-value=0, base-type=BT_TME_HV_Anf, compu {0=Cx0_Init (CM_TME_HV_Anf_Cx0_Init), 1=Cx1_HV_Netz_nicht_angefordet (CM_TME_HV_Anf_Cx1_HV_Netz_nicht_angefordet), 2=Cx2_HV_Netz_Stufe_1_angefordert (CM_TME_HV_Anf_Cx2_HV_Netz_Stufe_1_angefordert), 3=Cx3_HV_Netz_Stufe_2_angefordert (CM_TME_HV_Anf_Cx3_HV_Netz_Stufe_2_angefordert)}, range raw 0..3, transfer-property=PENDING  # Anforderung "HV-Netz aktivieren" wegen Innenraumkonditionierung mit HV-Komponente
          signal TME_HVEM_Vorhaltleistung_XIX_Thermomanagement_01_XIX_HCP5_CANFD01: start 416, 10 bit, little-endian, data-type-policy=OVERRIDE, i-signal-type=PRIMITIVE, init-value=1022, base-type=BT_TME_HVEM_Vorhaltleistung, invalid-value=Invalid_TME_HVEM_Vorhaltleistung_XIX_Thermomanagement_01_XIX_HCP5_CANFD01:1023, compu {phys=raw*100 for raw 0..1021, 1022=Cx3fe_Init (CM_TME_HVEM_Vorhaltleistung_Cx3fe_Init), 1023=Cx3ff_Fehler (CM_TME_HVEM_Vorhaltleistung_Cx3ff_Fehler); unit Unit_Watt}, range phys 0..102100 Unit_Watt, raw 0..1023, unit=Unit_Watt, transfer-property=PENDING  # Seitens Thermomanagement benötigter Leistungsvorhalt von HV-System
          signal TME_PTC_stufig_Status_XIX_Thermomanagement_01_XIX_HCP5_CANFD01: start 426, 3 bit, little-endian, data-type-policy=OVERRIDE, i-signal-type=PRIMITIVE, init-value=6, base-type=BT_TME_PTC_stufig_Status, invalid-value=Invalid_TME_PTC_stufig_Status_XIX_Thermomanagement_01_XIX_HCP5_CANFD01:7, compu {0=Cx0_Aus (CM_TME_PTC_stufig_Status_Cx0_Aus), 1=Cx1_Stufe_1_aktiv (CM_TME_PTC_stufig_Status_Cx1_Stufe_1_aktiv), 2=Cx2_Stufe_2_aktiv (CM_TME_PTC_stufig_Status_Cx2_Stufe_2_aktiv), 3=Cx3_Stufe_3_aktiv (CM_TME_PTC_stufig_Status_Cx3_Stufe_3_aktiv), 6=Cx6_Init_oder_nicht_verbaut (CM_TME_PTC_stufig_Status_Cx6_Init_oder_nicht_verbaut), 7=Cx7_Fehler (CM_TME_PTC_stufig_Status_Cx7_Fehler)}, range raw 0..7, transfer-property=PENDING  # Status von 12V_PTC_Stufig
          signal TME_EKK_HVK_Fehler_AE_XIX_Thermomanagement_01_XIX_HCP5_CANFD01: start 429, 2 bit, little-endian, data-type-policy=OVERRIDE, i-signal-type=PRIMITIVE, init-value=3, base-type=BT_TME_EKK_HVK_Fehler_AE, compu {0=Cx0_kein_Fehler_AE (CM_TME_EKK_HVK_Fehler_AE_Cx0_kein_Fehler_AE), 1=Cx1_Fehler_AE (CM_TME_EKK_HVK_Fehler_AE_Cx1_Fehler_AE), 3=Cx3_Init (CM_TME_EKK_HVK_Fehler_AE_Cx3_Init)}, range raw 0..3, transfer-property=TRIGGERED-ON-CHANGE  # Fehlerstatus aktive Entladung EKK
          signal TME_Anforderung_Heizkreispumpe_XIX_Thermomanagement_01_XIX_HCP5_CANFD01: start 431, 7 bit, little-endian, data-type-policy=OVERRIDE, i-signal-type=PRIMITIVE, init-value=126, base-type=BT_TME_Anforderung_Heizkreispumpe, invalid-value=Invalid_TME_Anforderung_Heizkreispumpe_XIX_Thermomanagement_01_XIX_HCP5_CANFD01:127, compu {phys=raw for raw 0..100, 126=Cx7e_Init (CM_TME_Anforderung_Heizkreispumpe_Cx7e_Init), 127=Cx7f_Fehler (CM_TME_Anforderung_Heizkreispumpe_Cx7f_Fehler); unit Unit_PerCent}, range phys 0..100 Unit_PerCent, raw 0..127, unit=Unit_PerCent, transfer-property=PENDING  # Anforderung Heizkreispumpe für Diagnose T-Sensor
          signal TME_Heizanforderung_Innenraum_XIX_Thermomanagement_01_XIX_HCP5_CANFD01: start 438, 2 bit, little-endian, data-type-policy=OVERRIDE, i-signal-type=PRIMITIVE, init-value=0, base-type=BT_TME_Heizanforderung_Innenraum, compu {0=Cx0_kein_Heizbedarf (CM_TME_Heizanforderung_Innenraum_Cx0_kein_Heizbedarf), 1=Cx1_kleiner_Heizbedarf (CM_TME_Heizanforderung_Innenraum_Cx1_kleiner_Heizbedarf), 2=Cx2_mittlerer_Heizbedarf (CM_TME_Heizanforderung_Innenraum_Cx2_mittlerer_Heizbedarf), 3=Cx3_max_Heizbedarf (CM_TME_Heizanforderung_Innenraum_Cx3_max_Heizbedarf)}, range raw 0..3, transfer-property=PENDING  # Anforderung an VKM bei Heizbedarf des Innenraums
          signal TME_Kompressorlastmoment_XIX_Thermomanagement_01_XIX_HCP5_CANFD01: start 440, 8 bit, little-endian, data-type-policy=OVERRIDE, i-signal-type=PRIMITIVE, init-value=0, base-type=BT_TME_Kompressorlastmoment, invalid-value=Invalid_TME_Kompressorlastmoment_XIX_Thermomanagement_01_XIX_HCP5_CANFD01:255, compu {phys=raw*0.25 for raw 0..254, 255=Cxff_Fehler (CM_TME_Kompressorlastmoment_Cxff_Fehler); unit Unit_NewtoMeter}, range phys 0..63.5 Unit_NewtoMeter, raw 0..255, unit=Unit_NewtoMeter, transfer-property=PENDING  # Aktuelles Lastmoment des Klimakompressors bezogen auf die Kurbelwelle
          signal TME_Antriebszustand_Anf_XIX_Thermomanagement_01_XIX_HCP5_CANFD01: start 448, 3 bit, little-endian, data-type-policy=OVERRIDE, i-signal-type=PRIMITIVE, init-value=0, base-type=BT_TME_Antriebszustand_Anf, invalid-value=Invalid_TME_Antriebszustand_Anf_XIX_Thermomanagement_01_XIX_HCP5_CANFD01:7, compu {0=Cx0_keine_Anforderung (CM_TME_Antriebszustand_Anf_Cx0_keine_Anforderung) (keine Anforderung), 1=Cx1_Antriebszustand_1 (CM_TME_Antriebszustand_Anf_Cx1_Antriebszustand_1) (Antriebszustand 1), 2=Cx2_Antriebszustand_2 (CM_TME_Antriebszustand_Anf_Cx2_Antriebszustand_2) (Antriebszustand 2), 3=Cx3_Antriebszustand_3 (CM_TME_Antriebszustand_Anf_Cx3_Antriebszustand_3) (Antriebszustand 3), 4=Cx4_Antriebszustand_4 (CM_TME_Antriebszustand_Anf_Cx4_Antriebszustand_4) (Antriebszustand 4), 5=Cx5_Antriebszustand_5 (CM_TME_Antriebszustand_Anf_Cx5_Antriebszustand_5) (Antriebszustand 5), 6=Cx6_Antriebszustand_6 (CM_TME_Antriebszustand_Anf_Cx6_Antriebszustand_6) (Antriebszustand 6), 7=Cx7_Fehler (CM_TME_Antriebszustand_Anf_Cx7_Fehler)}, range raw 0..7, transfer-property=PENDING  # Antriebszustandsanforderung von Thermomanagement an VKM
          signal TME_Batt_Kond_status_XIX_Thermomanagement_01_XIX_HCP5_CANFD01: start 451, 1 bit, little-endian, data-type-policy=OVERRIDE, i-signal-type=PRIMITIVE, init-value=0, base-type=BT_TME_Batt_Kond_status, compu {0=Cx0_inaktiv (CM_TME_Batt_Kond_status_Cx0_inaktiv), 1=Cx1_aktiv (CM_TME_Batt_Kond_status_Cx1_aktiv)}, range raw 0..1, transfer-property=PENDING  # Status der Vorkonditionierung der Batterie
          signal TME_Klima_Heizleistung_reduziert_XIX_Thermomanagement_01_XIX_HCP5_CANFD01: start 452, 1 bit, little-endian, data-type-policy=OVERRIDE, i-signal-type=PRIMITIVE, init-value=0, base-type=BT_TME_Klima_Heizleistung_reduziert, compu {0=Cx0_keine_Reduzierung (CM_TME_Klima_Heizleistung_reduziert_Cx0_keine_Reduzierung), 1=Cx1_Reduzierung_aktiv (CM_TME_Klima_Heizleistung_reduziert_Cx1_Reduzierung_aktiv)}, range raw 0..1, transfer-property=PENDING  # Status reduzierte Heizleistung für die Innenraumklimatisierung
          signal TME_Notbelueftung_Aktivierung_XIX_Thermomanagement_01_XIX_HCP5_CANFD01: start 453, 1 bit, little-endian, data-type-policy=OVERRIDE, i-signal-type=PRIMITIVE, init-value=0, base-type=BT_TME_Notbelueftung_Aktivierung, compu {0=Cx0_keine_Aktivierung (CM_TME_Notbelueftung_Aktivierung_Cx0_keine_Aktivierung), 1=Cx1_Aktivierung (CM_TME_Notbelueftung_Aktivierung_Cx1_Aktivierung)}, range raw 0..1, transfer-property=PENDING  # Anfoderung an Klima, die Notbelueftung zu aktivieren
          signal TME_Vorwarn_Komp_ein_XIX_Thermomanagement_01_XIX_HCP5_CANFD01: start 454, 1 bit, little-endian, data-type-policy=OVERRIDE, i-signal-type=PRIMITIVE, init-value=0, base-type=BT_TME_Vorwarn_Komp_ein, compu {0=Cx0_Kompressor_Aus (CM_TME_Vorwarn_Komp_ein_Cx0_Kompressor_Aus), 1=Cx1_Vorwarnung_Kompressor_Ein (CM_TME_Vorwarn_Komp_ein_Cx1_Vorwarnung_Kompressor_Ein)}, range raw 0..1, transfer-property=PENDING  # Vorwarnung an Motor zum Aufbau Momentenreserve bei kompressor_Ein
          signal TME_PTC_Leistung_Ist_XIX_Thermomanagement_01_XIX_HCP5_CANFD01: start 455, 9 bit, little-endian, data-type-policy=OVERRIDE, i-signal-type=PRIMITIVE, init-value=510, base-type=BT_TME_PTC_Leistung_Ist, invalid-value=Invalid_TME_PTC_Leistung_Ist_XIX_Thermomanagement_01_XIX_HCP5_CANFD01:511, compu {phys=raw*10 for raw 0..509, 510=Cx1fe_Init (CM_TME_PTC_Leistung_Ist_Cx1fe_Init), 511=Cx1ff_Fehler (CM_TME_PTC_Leistung_Ist_Cx1ff_Fehler); unit Unit_Watt}, range phys 0..5090 Unit_Watt, raw 0..511, unit=Unit_Watt, transfer-property=PENDING  # IST_Leistung von NV/MV PTC (LIN und Stufig)
          signal TME_DCDC_HV_Status_Kuehlung_XIX_Thermomanagement_01_XIX_HCP5_CANFD01: start 464, 2 bit, little-endian, data-type-policy=OVERRIDE, i-signal-type=PRIMITIVE, init-value=2, base-type=BT_TME_DCDC_HV_Status_Kuehlung, invalid-value=Invalid_TME_DCDC_HV_Status_Kuehlung_XIX_Thermomanagement_01_XIX_HCP5_CANFD01:1, compu {0=Cx0_kein_Fehler_AE (CM_TME_DCDC_HV_Status_Kuehlung_Cx0_kein_Fehler_AE), 1=Cx1_Fehler (CM_TME_DCDC_HV_Status_Kuehlung_Cx1_Fehler), 2=Cx2_InitWert_Init (CM_TME_DCDC_HV_Status_Kuehlung_Cx2_InitWert_Init)}, range raw 0..2, transfer-property=PENDING  # TME Fehlerstatus HV DCDC-Wandler Kühlung
          signal TME_NT_Kuehlmittel_Sensor_02_XIX_Thermomanagement_01_XIX_HCP5_CANFD01: start 466, 1 bit, little-endian, data-type-policy=OVERRIDE, i-signal-type=PRIMITIVE, init-value=0, base-type=BT_TME_NT_Kuehlmittel_Sensor_02, compu {0=Cx0_OK (CM_TME_NT_Kuehlmittel_Sensor_02_Cx0_OK), 1=Cx1_Kuehlmittel_unter_min (CM_TME_NT_Kuehlmittel_Sensor_02_Cx1_Kuehlmittel_unter_min)}, range raw 0..1, transfer-property=PENDING  # Signal der Sensorelektroden für die Kühlmittelreserve aktuell, entstört, bewertet (OK/Mangel)
          signal TME_Min_Leerlaufdrehzahl_XIX_Thermomanagement_01_XIX_HCP5_CANFD01: start 467, 7 bit, little-endian, data-type-policy=OVERRIDE, i-signal-type=PRIMITIVE, init-value=126, base-type=BT_TME_Min_Leerlaufdrehzahl, invalid-value=Invalid_TME_Min_Leerlaufdrehzahl_XIX_Thermomanagement_01_XIX_HCP5_CANFD01:127, compu {phys=raw*10+500 for raw 0..125, 126=Cx7e_Init (CM_TME_Min_Leerlaufdrehzahl_Cx7e_Init), 127=Cx7f_Fehler (CM_TME_Min_Leerlaufdrehzahl_Cx7f_Fehler); unit Unit_MinutInver}, range phys 500..1750 Unit_MinutInver, raw 0..127, unit=Unit_MinutInver, transfer-property=PENDING  # Minimale Motordrehzahl im Stand
          signal TME_HT_Kuehlmittel_Sensor_XIX_Thermomanagement_01_XIX_HCP5_CANFD01: start 474, 1 bit, little-endian, data-type-policy=OVERRIDE, i-signal-type=PRIMITIVE, init-value=0, base-type=BT_TME_HT_Kuehlmittel_Sensor, compu {0=Cx0_OK (CM_TME_HT_Kuehlmittel_Sensor_Cx0_OK), 1=Cx1_Kuehlmittel_unter_min (CM_TME_HT_Kuehlmittel_Sensor_Cx1_Kuehlmittel_unter_min)}, range raw 0..1, transfer-property=PENDING  # Signal der Sensorelektroden für die Kühlmittelreserve aktuell, entstört, bewertet (OK/Mangel)
          signal TME_Kuehlerluefter_Totalausfall_XIX_Thermomanagement_01_XIX_HCP5_CANFD01: start 475, 1 bit, little-endian, data-type-policy=OVERRIDE, i-signal-type=PRIMITIVE, init-value=0, base-type=BT_TME_Kuehlerluefter_Totalausfall, compu {0=Cx0_kein_Ausfall (CM_TME_Kuehlerluefter_Totalausfall_Cx0_kein_Ausfall), 1=Cx1_Ausfall (CM_TME_Kuehlerluefter_Totalausfall_Cx1_Ausfall)}, range raw 0..1, transfer-property=PENDING  # Totalausfall Kühlerlüfter
          signal TME_Kuehlerjalousie_Ausfall_XIX_Thermomanagement_01_XIX_HCP5_CANFD01: start 476, 1 bit, little-endian, data-type-policy=OVERRIDE, i-signal-type=PRIMITIVE, init-value=0, base-type=BT_TME_Kuehlerjalousie_Ausfall, compu {0=Cx0_kein_Ausfall (CM_TME_Kuehlerjalousie_Ausfall_Cx0_kein_Ausfall), 1=Cx1_Ausfall (CM_TME_Kuehlerjalousie_Ausfall_Cx1_Ausfall)}, range raw 0..1, transfer-property=PENDING  # Ausfall Kühlerjalousie
          signal TME_HV_IstLeistung_HVHW_XIX_Thermomanagement_01_XIX_HCP5_CANFD01: start 477, 7 bit, little-endian, data-type-policy=OVERRIDE, i-signal-type=PRIMITIVE, init-value=126, base-type=BT_TME_HV_IstLeistung_HVHW, invalid-value=Invalid_TME_HV_IstLeistung_HVHW_XIX_Thermomanagement_01_XIX_HCP5_CANFD01:127, compu {phys=raw*100 for raw 0..125, 126=Cx7e_InitWert (CM_TME_HV_IstLeistung_HVHW_Cx7e_InitWert), 127=Cx7f_Fehler (CM_TME_HV_IstLeistung_HVHW_Cx7f_Fehler); unit Unit_Watt}, range phys 0..12500 Unit_Watt, raw 0..127, unit=Unit_Watt, transfer-property=PENDING  # aktuelle HV-Leistung HV-Heizer Wasser
          signal TME_Temp_nach_Heizregister_XIX_Thermomanagement_01_XIX_HCP5_CANFD01: start 484, 10 bit, little-endian, data-type-policy=OVERRIDE, i-signal-type=PRIMITIVE, init-value=1022, base-type=BT_TME_Temp_nach_Heizregister, invalid-value=Invalid_TME_Temp_nach_Heizregister_XIX_Thermomanagement_01_XIX_HCP5_CANFD01:1023, compu {phys=raw*0.1-20 for raw 0..1020, 1021=Cx3fd_nicht_verfuegbar (CM_TME_Temp_nach_Heizregister_Cx3fd_nicht_verfuegbar) (nicht_verfügbar), 1022=Cx3fe_InitWert (CM_TME_Temp_nach_Heizregister_Cx3fe_InitWert), 1023=Cx3ff_Fehler (CM_TME_Temp_nach_Heizregister_Cx3ff_Fehler); unit Unit_DegreCelsi}, range phys -20..82 Unit_DegreCelsi, raw 0..1023, unit=Unit_DegreCelsi, transfer-property=PENDING  # Determined air temperature after damper register
          signal TME_HVHW_Verbauinfo_XIX_Thermomanagement_01_XIX_HCP5_CANFD01: start 494, 2 bit, little-endian, data-type-policy=OVERRIDE, i-signal-type=PRIMITIVE, init-value=0, base-type=BT_TME_HVHW_Verbauinfo, compu {0=Cx0_InitWert (CM_TME_HVHW_Verbauinfo_Cx0_InitWert), 1=Cx1_nicht_verbaut (CM_TME_HVHW_Verbauinfo_Cx1_nicht_verbaut), 2=Cx2_verbaut (CM_TME_HVHW_Verbauinfo_Cx2_verbaut)}, range raw 0..2, transfer-property=PENDING  # Verbauinfo des Hochvolt-Heizer Luft
          signal TME_HVHL_Verbauinfo_XIX_Thermomanagement_01_XIX_HCP5_CANFD01: start 496, 2 bit, little-endian, data-type-policy=OVERRIDE, i-signal-type=PRIMITIVE, init-value=0, base-type=BT_TME_HVHL_Verbauinfo, compu {0=Cx0_InitWert (CM_TME_HVHL_Verbauinfo_Cx0_InitWert), 1=Cx1_nicht_verbaut (CM_TME_HVHL_Verbauinfo_Cx1_nicht_verbaut), 2=Cx2_verbaut (CM_TME_HVHL_Verbauinfo_Cx2_verbaut)}, range raw 0..2, transfer-property=PENDING  # Verbauinformation für den HV-Heizer Luft
          signal TME_MVH_L_Verbauinfo_XIX_Thermomanagement_01_XIX_HCP5_CANFD01: start 498, 2 bit, little-endian, data-type-policy=OVERRIDE, i-signal-type=PRIMITIVE, init-value=0, base-type=BT_TME_MVH_L_Verbauinfo, compu {0=Cx0_InitWert (CM_TME_MVH_L_Verbauinfo_Cx0_InitWert), 1=Cx1_nicht_verbaut (CM_TME_MVH_L_Verbauinfo_Cx1_nicht_verbaut), 2=Cx2_verbaut (CM_TME_MVH_L_Verbauinfo_Cx2_verbaut)}, range raw 0..2, transfer-property=PENDING  # Verbauinformation für den MV-Heizer Luft
          signal TME_ETV_IstVolumenstrom_XIX_Thermomanagement_01_XIX_HCP5_CANFD01: start 500, 9 bit, little-endian, data-type-policy=OVERRIDE, i-signal-type=PRIMITIVE, init-value=510, base-type=BT_TME_ETV_IstVolumenstrom, invalid-value=Invalid_TME_ETV_IstVolumenstrom_XIX_Thermomanagement_01_XIX_HCP5_CANFD01:511, compu {phys=raw*0.1 for raw 0..300, 510=Cx1fe_Init (CM_TME_ETV_IstVolumenstrom_Cx1fe_Init), 511=Cx1ff_Fehler (CM_TME_ETV_IstVolumenstrom_Cx1ff_Fehler); unit Unit_LiterPerMinut}, range phys 0..30 Unit_LiterPerMinut, raw 0..511, unit=Unit_LiterPerMinut, transfer-property=PENDING  # Ist-Volumenstrom Kühlkreis am eTV
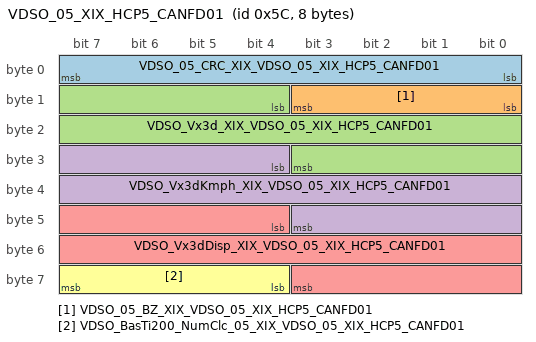
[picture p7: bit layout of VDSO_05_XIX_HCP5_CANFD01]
      frame VDSO_05_XIX_HCP5_CANFD01: id 0x5C, to BMC_HV, frame-length=8, can-addressing-mode=STANDARD, can-frame-rx-behavior=CAN-FD, can-frame-tx-behavior=CAN-FD
        pdu VDSO_05_XIX_HCP5_CANFD01: length=8, transmission-mode-true-timing=cyclic-timing={time-offset=0, time-period=0.05}, unused-bit-pattern=0
          signal VDSO_05_CRC_XIX_VDSO_05_XIX_HCP5_CANFD01: start 0, 8 bit, little-endian, data-type-policy=OVERRIDE, i-signal-type=PRIMITIVE, init-value=0, base-type=BT_VDSO_05_CRC, compu {phys=raw for raw 0..255}, range phys 0..255, raw 0..255, transfer-property=PENDING  # Für MLB: Berechnung siehe Lastenheft "Kommunikationsabsicherung für FlexRay und CAN" Ab MQB und MLBevo: Berechnung siehe Lastenheft "End-to-End Kommunikationsabsicherung" Endwerte siehe Begleitdokument "S-PDU Kennungsfolgen"
          signal VDSO_05_BZ_XIX_VDSO_05_XIX_HCP5_CANFD01: start 8, 4 bit, little-endian, data-type-policy=OVERRIDE, i-signal-type=PRIMITIVE, init-value=0, base-type=BT_VDSO_05_BZ, compu {phys=raw for raw 0..15}, range phys 0..15, raw 0..15, transfer-property=PENDING  # 4bit Botschaftszähler, wird mit jeder Sendebotschaft inkrementiert
          signal VDSO_Vx3d_XIX_VDSO_05_XIX_HCP5_CANFD01: start 12, 16 bit, little-endian, data-type-policy=OVERRIDE, i-signal-type=PRIMITIVE, init-value=65534, base-type=BT_VDSO_Vx3d, invalid-value=Invalid_VDSO_Vx3d_XIX_VDSO_05_XIX_HCP5_CANFD01:65535, compu {phys=raw*0.0039-127.7874 for raw 0..65533, 65534=Cxfffe_Init (CM_VDSO_Vx3d_Cxfffe_Init), 65535=Cxffff_Fehler (CM_VDSO_Vx3d_Cxffff_Fehler); unit Unit_MeterPerSecon}, range phys -127.7874..127.7913 Unit_MeterPerSecon, raw 0..65535, unit=Unit_MeterPerSecon, transfer-property=PENDING, to BMC_HV(timeout 0.5 s)  # Geschwindigkeitssignal vom ABS/ASR oder ESP. Mittelwert der angetriebenen Räder. Bei MSR oder ABS Eingriffen wird die ABS-Referenzgeschwindigkeit für >= 200ms eingespiegelt (Zeit wird mit Aktiv-Flanke der Funktionsbits getriggert) MQB: Bei Frontantrieb und gesteuertem Allrad (Haldex) Mittelwert der Vorderräder.
          signal VDSO_Vx3dKmph_XIX_VDSO_05_XIX_HCP5_CANFD01: start 28, 16 bit, little-endian, data-type-policy=OVERRIDE, i-signal-type=PRIMITIVE, init-value=65534, base-type=BT_VDSO_Vx3dKmph, invalid-value=Invalid_VDSO_Vx3dKmph_XIX_VDSO_05_XIX_HCP5_CANFD01:65535, compu {phys=raw*0.014-458.724 for raw 0..65533, 65534=Cxfffe_Init (CM_VDSO_Vx3dKmph_Cxfffe_Init), 65535=Cxffff_Fehler (CM_VDSO_Vx3dKmph_Cxffff_Fehler); unit Unit_KiloMeterPerHour}, range phys -458.724..458.738 Unit_KiloMeterPerHour, raw 0..65535, unit=Unit_KiloMeterPerHour, transfer-property=PENDING  # Longitudinal velocity estimated at the centre of rear axle. Estimation requires 3D IMU.
          signal VDSO_Vx3dDisp_XIX_VDSO_05_XIX_HCP5_CANFD01: start 44, 16 bit, little-endian, data-type-policy=OVERRIDE, i-signal-type=PRIMITIVE, init-value=65534, base-type=BT_VDSO_Vx3dDisp, invalid-value=Invalid_VDSO_Vx3dDisp_XIX_VDSO_05_XIX_HCP5_CANFD01:65535, compu {phys=raw*0.0039-127.7874 for raw 0..65533, 65534=Cxfffe_Init (CM_VDSO_Vx3dDisp_Cxfffe_Init), 65535=Cxffff_Fehler (CM_VDSO_Vx3dDisp_Cxffff_Fehler); unit Unit_MeterPerSecon}, range phys -127.7874..127.7913 Unit_MeterPerSecon, raw 0..65535, unit=Unit_MeterPerSecon, transfer-property=PENDING  # VDSO_Vx3d incl. additional scaling to meet official regulations (Typ approval. NCAP eg)
          signal VDSO_BasTi200_NumClc_05_XIX_VDSO_05_XIX_HCP5_CANFD01: start 60, 4 bit, little-endian, data-type-policy=OVERRIDE, i-signal-type=PRIMITIVE, base-type=BT_VDSO_BasTi200_NumClc_05, compu {phys=raw for raw 0..15; unit Unit_None}, range phys 0..15 Unit_None, raw 0..15, unit=Unit_None, transfer-property=PENDING  # CalculationNumber of the VDSO 200 Runnable to enable PDU-TLT merge in receiver ECU
      frame WFS_02_XIX_HCP5_CANFD01: id 0x1A555446, to BMC_HV, frame-length=32, can-addressing-mode=EXTENDED, can-frame-rx-behavior=CAN-FD, can-frame-tx-behavior=CAN-FD
        pdu WFS_02_XIX_HCP5_CANFD01: length=28, minimum-delay=0.05, transmission-mode-true-timing={cyclic-timing={time-offset=0, time-period=0.4}, event-controlled-timing={number-of-repetitions=0, repetition-period=0}}, unused-bit-pattern=0
          signal WFS_02_CRC_XIX_WFS_02_XIX_HCP5_CANFD01: start 0, 8 bit, little-endian, data-type-policy=OVERRIDE, i-signal-type=PRIMITIVE, init-value=0, base-type=BT_WFS_02_CRC, compu {phys=raw for raw 0..255}, range phys 0..255, raw 0..255, transfer-property=PENDING  # Für MLB: Berechnung siehe Lastenheft "Kommunikationsabsicherung für FlexRay und CAN" Ab MQB und MLBevo: Berechnung siehe Lastenheft "End-to-End Kommunikationsabsicherung" Endwerte siehe Begleitdokument "S-PDU Kennungsfolgen"
          signal WFS_02_BZ_XIX_WFS_02_XIX_HCP5_CANFD01: start 8, 4 bit, little-endian, data-type-policy=OVERRIDE, i-signal-type=PRIMITIVE, init-value=0, base-type=BT_WFS_02_BZ, compu {phys=raw for raw 0..15}, range phys 0..15, raw 0..15, transfer-property=PENDING
          signal WFS_ID_Geb_autorisiert_in_Kl15_XIX_WFS_02_XIX_HCP5_CANFD01: start 12, 1 bit, little-endian, data-type-policy=OVERRIDE, i-signal-type=PRIMITIVE, init-value=0, base-type=BT_WFS_ID_Geb_autorisiert_in_Kl15, compu {0=Cx0_nicht_authorisiert_in_Kl15 (CM_WFS_ID_Geb_autorisiert_in_Kl15_Cx0_nicht_authorisiert_in_Kl15), 1=Cx1_authorisiert_in_Kl15 (CM_WFS_ID_Geb_autorisiert_in_Kl15_Cx1_authorisiert_in_Kl15)}, range raw 0..1, transfer-property=TRIGGERED-ON-CHANGE-WITHOUT-REPETITION  # Authorisierung des Schlüssels im aktiven Klemme-15-Zyklus
          signal WFS_ID_Geb_steckt_XIX_WFS_02_XIX_HCP5_CANFD01: start 13, 1 bit, little-endian, data-type-policy=OVERRIDE, i-signal-type=PRIMITIVE, init-value=0, base-type=BT_WFS_ID_Geb_steckt, compu {0=Cx0_kein_Schluessel_im_Zuendschloss (CM_WFS_ID_Geb_steckt_Cx0_kein_Schluessel_im_Zuendschloss), 1=Cx1_Schluessel_steckt_im_Zuendschloss (CM_WFS_ID_Geb_steckt_Cx1_Schluessel_steckt_im_Zuendschloss) (Schluessel steckt im Zuendschloss)}, range raw 0..1, transfer-property=TRIGGERED-ON-CHANGE-WITHOUT-REPETITION  # Schluessel (ID-Geber) im Zuendschloss
          signal WFS_ID_Geb_autorisiert_XIX_WFS_02_XIX_HCP5_CANFD01: start 14, 1 bit, little-endian, data-type-policy=OVERRIDE, i-signal-type=PRIMITIVE, init-value=0, base-type=BT_WFS_ID_Geb_autorisiert, compu {0=Cx0_Schluessel_nicht_authorisiert (CM_WFS_ID_Geb_autorisiert_Cx0_Schluessel_nicht_authorisiert), 1=Cx1_Schluessel_authorisiert (CM_WFS_ID_Geb_autorisiert_Cx1_Schluessel_authorisiert)}, range raw 0..1, transfer-property=TRIGGERED-ON-CHANGE-WITHOUT-REPETITION  # Authorisierung Schluessel (ID-Geber)
          signal WFS_Safe_XIX_WFS_02_XIX_HCP5_CANFD01: start 15, 1 bit, little-endian, data-type-policy=OVERRIDE, i-signal-type=PRIMITIVE, init-value=0, base-type=BT_WFS_Safe, compu {0=Cx0_Init (CM_WFS_Safe_Cx0_Init), 1=Cx1_WFS_nicht_deaktiviert (CM_WFS_Safe_Cx1_WFS_nicht_deaktiviert) (WFS nicht deaktiviert)}, range raw 0..1, transfer-property=TRIGGERED-ON-CHANGE-WITHOUT-REPETITION  # Status WFS
          signal VIN_1_XIX_WFS_02_XIX_HCP5_CANFD01: start 16, 8 bit, little-endian, data-type-policy=OVERRIDE, i-signal-type=PRIMITIVE, init-value=45, base-type=BT_VIN_1, compu {phys=raw for raw 0..255}, range phys 0..255, raw 0..255, transfer-property=PENDING, to BMC_HV(timeout 4 s)  # Initwert: 0x2D bei Fahrzeugen mit Wegfahrsperrengeneration >= 5 0x58 bei Fahrzeugen mit Wegfahrsperrengeneration < 5 (z.B. WFS-4)
          signal VIN_2_XIX_WFS_02_XIX_HCP5_CANFD01: start 24, 8 bit, little-endian, data-type-policy=OVERRIDE, i-signal-type=PRIMITIVE, init-value=45, base-type=BT_VIN_2, compu {phys=raw for raw 0..255}, range phys 0..255, raw 0..255, transfer-property=PENDING, to BMC_HV(timeout 4 s)  # Initwert: 0x2D bei Fahrzeugen mit Wegfahrsperrengeneration >= 5 0x58 bei Fahrzeugen mit Wegfahrsperrengeneration < 5 (z.B. WFS-4)
          signal VIN_3_XIX_WFS_02_XIX_HCP5_CANFD01: start 32, 8 bit, little-endian, data-type-policy=OVERRIDE, i-signal-type=PRIMITIVE, init-value=45, base-type=BT_VIN_3, compu {phys=raw for raw 0..255}, range phys 0..255, raw 0..255, transfer-property=PENDING, to BMC_HV(timeout 4 s)  # Initwert: 0x2D bei Fahrzeugen mit Wegfahrsperrengeneration >= 5 0x58 bei Fahrzeugen mit Wegfahrsperrengeneration < 5 (z.B. WFS-4)
          signal VIN_4_XIX_WFS_02_XIX_HCP5_CANFD01: start 40, 8 bit, little-endian, data-type-policy=OVERRIDE, i-signal-type=PRIMITIVE, init-value=45, base-type=BT_VIN_4, compu {phys=raw for raw 0..255}, range phys 0..255, raw 0..255, transfer-property=PENDING, to BMC_HV(timeout 4 s)  # Initwert: 0x2D bei Fahrzeugen mit Wegfahrsperrengeneration >= 5 0x58 bei Fahrzeugen mit Wegfahrsperrengeneration < 5 (z.B. WFS-4)
          signal VIN_5_XIX_WFS_02_XIX_HCP5_CANFD01: start 48, 8 bit, little-endian, data-type-policy=OVERRIDE, i-signal-type=PRIMITIVE, init-value=45, base-type=BT_VIN_5, compu {phys=raw for raw 0..255}, range phys 0..255, raw 0..255, transfer-property=PENDING, to BMC_HV(timeout 4 s)  # Initwert: 0x2D bei Fahrzeugen mit Wegfahrsperrengeneration >= 5 0x58 bei Fahrzeugen mit Wegfahrsperrengeneration < 5 (z.B. WFS-4)
          signal VIN_6_XIX_WFS_02_XIX_HCP5_CANFD01: start 56, 8 bit, little-endian, data-type-policy=OVERRIDE, i-signal-type=PRIMITIVE, init-value=45, base-type=BT_VIN_6, compu {phys=raw for raw 0..255}, range phys 0..255, raw 0..255, transfer-property=PENDING, to BMC_HV(timeout 4 s)  # Initwert: 0x2D bei Fahrzeugen mit Wegfahrsperrengeneration >= 5 0x58 bei Fahrzeugen mit Wegfahrsperrengeneration < 5 (z.B. WFS-4)
          signal VIN_7_XIX_WFS_02_XIX_HCP5_CANFD01: start 64, 8 bit, little-endian, data-type-policy=OVERRIDE, i-signal-type=PRIMITIVE, init-value=45, base-type=BT_VIN_7, compu {phys=raw for raw 0..255}, range phys 0..255, raw 0..255, transfer-property=PENDING, to BMC_HV(timeout 4 s)  # Initwert: 0x2D bei Fahrzeugen mit Wegfahrsperrengeneration >= 5 0x58 bei Fahrzeugen mit Wegfahrsperrengeneration < 5 (z.B. WFS-4)
          signal VIN_8_XIX_WFS_02_XIX_HCP5_CANFD01: start 72, 8 bit, little-endian, data-type-policy=OVERRIDE, i-signal-type=PRIMITIVE, init-value=45, base-type=BT_VIN_8, compu {phys=raw for raw 0..255}, range phys 0..255, raw 0..255, transfer-property=PENDING, to BMC_HV(timeout 4 s)  # Initwert: 0x2D bei Fahrzeugen mit Wegfahrsperrengeneration >= 5 0x58 bei Fahrzeugen mit Wegfahrsperrengeneration < 5 (z.B. WFS-4)
          signal VIN_9_XIX_WFS_02_XIX_HCP5_CANFD01: start 80, 8 bit, little-endian, data-type-policy=OVERRIDE, i-signal-type=PRIMITIVE, init-value=45, base-type=BT_VIN_9, compu {phys=raw for raw 0..255}, range phys 0..255, raw 0..255, transfer-property=PENDING, to BMC_HV(timeout 4 s)  # Initwert: 0x2D bei Fahrzeugen mit Wegfahrsperrengeneration >= 5 0x58 bei Fahrzeugen mit Wegfahrsperrengeneration < 5 (z.B. WFS-4)
          signal VIN_10_XIX_WFS_02_XIX_HCP5_CANFD01: start 88, 8 bit, little-endian, data-type-policy=OVERRIDE, i-signal-type=PRIMITIVE, init-value=45, base-type=BT_VIN_10, compu {phys=raw for raw 0..255}, range phys 0..255, raw 0..255, transfer-property=PENDING, to BMC_HV(timeout 4 s)  # Initwert: 0x2D bei Fahrzeugen mit Wegfahrsperrengeneration >= 5 0x58 bei Fahrzeugen mit Wegfahrsperrengeneration < 5 (z.B. WFS-4)
          signal VIN_11_XIX_WFS_02_XIX_HCP5_CANFD01: start 96, 8 bit, little-endian, data-type-policy=OVERRIDE, i-signal-type=PRIMITIVE, init-value=45, base-type=BT_VIN_11, compu {phys=raw for raw 0..255}, range phys 0..255, raw 0..255, transfer-property=PENDING, to BMC_HV(timeout 4 s)  # Initwert: 0x2D bei Fahrzeugen mit Wegfahrsperrengeneration >= 5 0x58 bei Fahrzeugen mit Wegfahrsperrengeneration < 5 (z.B. WFS-4)
          signal VIN_12_XIX_WFS_02_XIX_HCP5_CANFD01: start 104, 8 bit, little-endian, data-type-policy=OVERRIDE, i-signal-type=PRIMITIVE, init-value=45, base-type=BT_VIN_12, compu {phys=raw for raw 0..255}, range phys 0..255, raw 0..255, transfer-property=PENDING, to BMC_HV(timeout 4 s)  # Initwert: 0x2D bei Fahrzeugen mit Wegfahrsperrengeneration >= 5 0x58 bei Fahrzeugen mit Wegfahrsperrengeneration < 5 (z.B. WFS-4)
          signal VIN_13_XIX_WFS_02_XIX_HCP5_CANFD01: start 112, 8 bit, little-endian, data-type-policy=OVERRIDE, i-signal-type=PRIMITIVE, init-value=45, base-type=BT_VIN_13, compu {phys=raw for raw 0..255}, range phys 0..255, raw 0..255, transfer-property=PENDING, to BMC_HV(timeout 4 s)  # Initwert: 0x2D bei Fahrzeugen mit Wegfahrsperrengeneration >= 5 0x58 bei Fahrzeugen mit Wegfahrsperrengeneration < 5 (z.B. WFS-4)
          signal VIN_14_XIX_WFS_02_XIX_HCP5_CANFD01: start 120, 8 bit, little-endian, data-type-policy=OVERRIDE, i-signal-type=PRIMITIVE, init-value=45, base-type=BT_VIN_14, compu {phys=raw for raw 0..255}, range phys 0..255, raw 0..255, transfer-property=PENDING, to BMC_HV(timeout 4 s)  # Initwert: 0x2D bei Fahrzeugen mit Wegfahrsperrengeneration >= 5 0x58 bei Fahrzeugen mit Wegfahrsperrengeneration < 5 (z.B. WFS-4)
          signal VIN_15_XIX_WFS_02_XIX_HCP5_CANFD01: start 128, 8 bit, little-endian, data-type-policy=OVERRIDE, i-signal-type=PRIMITIVE, init-value=45, base-type=BT_VIN_15, compu {phys=raw for raw 0..255}, range phys 0..255, raw 0..255, transfer-property=PENDING, to BMC_HV(timeout 4 s)  # Initwert: 0x2D bei Fahrzeugen mit Wegfahrsperrengeneration >= 5 0x58 bei Fahrzeugen mit Wegfahrsperrengeneration < 5 (z.B. WFS-4)
          signal VIN_16_XIX_WFS_02_XIX_HCP5_CANFD01: start 136, 8 bit, little-endian, data-type-policy=OVERRIDE, i-signal-type=PRIMITIVE, init-value=45, base-type=BT_VIN_16, compu {phys=raw for raw 0..255}, range phys 0..255, raw 0..255, transfer-property=PENDING, to BMC_HV(timeout 4 s)  # Initwert: 0x2D bei Fahrzeugen mit Wegfahrsperrengeneration >= 5 0x58 bei Fahrzeugen mit Wegfahrsperrengeneration < 5 (z.B. WFS-4)
          signal VIN_17_XIX_WFS_02_XIX_HCP5_CANFD01: start 144, 8 bit, little-endian, data-type-policy=OVERRIDE, i-signal-type=PRIMITIVE, init-value=45, base-type=BT_VIN_17, compu {phys=raw for raw 0..255}, range phys 0..255, raw 0..255, transfer-property=PENDING, to BMC_HV(timeout 4 s)  # Initwert: 0x2D bei Fahrzeugen mit Wegfahrsperrengeneration >= 5 0x58 bei Fahrzeugen mit Wegfahrsperrengeneration < 5 (z.B. WFS-4)
          signal WFS_Schluessel_Soll_XIX_WFS_02_XIX_HCP5_CANFD01: start 152, 4 bit, little-endian, data-type-policy=OVERRIDE, i-signal-type=PRIMITIVE, init-value=0, base-type=BT_WFS_Schluessel_Soll, compu {phys=raw for raw 0..8; unit Unit_None}, range phys 0..8 Unit_None, raw 0..8, unit=Unit_None, transfer-property=TRIGGERED-ON-CHANGE-WITHOUT-REPETITION  # Sollwert der zu lernenden Schluessel
          signal WFS_Schluessel_Ist_XIX_WFS_02_XIX_HCP5_CANFD01: start 156, 4 bit, little-endian, data-type-policy=OVERRIDE, i-signal-type=PRIMITIVE, init-value=0, base-type=BT_WFS_Schluessel_Ist, compu {phys=raw for raw 0..8; unit Unit_None}, range phys 0..8 Unit_None, raw 0..8, unit=Unit_None, transfer-property=TRIGGERED-ON-CHANGE-WITHOUT-REPETITION  # Istwert der gelernten Schluessel
          signal WFS_Schluessel_Fahrberecht_XIX_WFS_02_XIX_HCP5_CANFD01: start 160, 4 bit, little-endian, data-type-policy=OVERRIDE, i-signal-type=PRIMITIVE, init-value=0, base-type=BT_WFS_Schluessel_Fahrberecht, compu {0=Cx0_kein_authorisierter_Schluessel_erkannt (CM_WFS_Schluessel_Fahrberecht_Cx0_kein_authorisierter_Schluessel_erkannt) (kein authorisierter Schluessel erkannt), 1=Cx1_aktive_Funkschluessel_Nr_01 (CM_WFS_Schluessel_Fahrberecht_Cx1_aktive_Funkschluessel_Nr_01), 2=Cx2_aktive_Funkschluessel_Nr_02 (CM_WFS_Schluessel_Fahrberecht_Cx2_aktive_Funkschluessel_Nr_02), 3=Cx3_aktive_Funkschluessel_Nr_03 (CM_WFS_Schluessel_Fahrberecht_Cx3_aktive_Funkschluessel_Nr_03), 4=Cx4_aktive_Funkschluessel_Nr_04 (CM_WFS_Schluessel_Fahrberecht_Cx4_aktive_Funkschluessel_Nr_04), 5=Cx5_aktive_Funkschluessel_Nr_05 (CM_WFS_Schluessel_Fahrberecht_Cx5_aktive_Funkschluessel_Nr_05), 6=Cx6_aktive_Funkschluessel_Nr_06 (CM_WFS_Schluessel_Fahrberecht_Cx6_aktive_Funkschluessel_Nr_06), 7=Cx7_aktive_Funkschluessel_Nr_07 (CM_WFS_Schluessel_Fahrberecht_Cx7_aktive_Funkschluessel_Nr_07), 8=Cx8_aktive_Funkschluessel_Nr_08 (CM_WFS_Schluessel_Fahrberecht_Cx8_aktive_Funkschluessel_Nr_08), 9=Cx9_ungueltig_09 (CM_WFS_Schluessel_Fahrberecht_Cx9_ungueltig_09), 10=Cxa_ungueltig_10 (CM_WFS_Schluessel_Fahrberecht_Cxa_ungueltig_10), 11=Cxb_ungueltig_11 (CM_WFS_Schluessel_Fahrberecht_Cxb_ungueltig_11), 12=Cxc_ungueltig_12 (CM_WFS_Schluessel_Fahrberecht_Cxc_ungueltig_12), 13=Cxd_ungueltig_13 (CM_WFS_Schluessel_Fahrberecht_Cxd_ungueltig_13), 14=Cxe_ungueltig_14 (CM_WFS_Schluessel_Fahrberecht_Cxe_ungueltig_14), 15=Cxf_digitaler_Schluessel_aktiv (CM_WFS_Schluessel_Fahrberecht_Cxf_digitaler_Schluessel_aktiv)}, range raw 0..15, transfer-property=TRIGGERED-ON-CHANGE-WITHOUT-REPETITION  # Schlüsselnummer Fahrberechtigung 0 = ungueltig, xxxx = Schluessel-Nr.
          signal WFS_Fahrerhinweise_XIX_WFS_02_XIX_HCP5_CANFD01: start 164, 2 bit, little-endian, data-type-policy=OVERRIDE, i-signal-type=PRIMITIVE, init-value=0, base-type=BT_WFS_Fahrerhinweise, compu {0=Cx0_Keine_Anzeigeanforderung (CM_WFS_Fahrerhinweise_Cx0_Keine_Anzeigeanforderung), 1=Cx1_Schuessel_Auth_niO (CM_WFS_Fahrerhinweise_Cx1_Schuessel_Auth_niO), 2=Cx2_Notlauf_aktiv (CM_WFS_Fahrerhinweise_Cx2_Notlauf_aktiv), 3=Cx3_Schluessel_Kessy_nicht_gefunden (CM_WFS_Fahrerhinweise_Cx3_Schluessel_Kessy_nicht_gefunden)}, range raw 0..3, transfer-property=PENDING  # Meldungen, Fahrer- und Warnhinweise der Wegfahrsperre
          signal WFS_Parken_Status_XIX_WFS_02_XIX_HCP5_CANFD01: start 166, 2 bit, little-endian, data-type-policy=OVERRIDE, i-signal-type=PRIMITIVE, init-value=0, base-type=BT_WFS_Parken_Status, compu {0=Cx0_Limitierung_inaktiv (CM_WFS_Parken_Status_Cx0_Limitierung_inaktiv), 1=Cx1_Limitierung_aktiv (CM_WFS_Parken_Status_Cx1_Limitierung_aktiv), 2=Cx2_Abbruch (CM_WFS_Parken_Status_Cx2_Abbruch)}, range raw 0..2, transfer-property=TRIGGERED-ON-CHANGE-WITHOUT-REPETITION  # Schnittstelle zwischen WFS und ZFAS für das Pilotierte Parken um in Richtung ZFAS den Status der WFS im BCM2 zu kommunizieren
          signal WFS_Klemmenfreigabe_XIX_WFS_02_XIX_HCP5_CANFD01: start 169, 1 bit, little-endian, data-type-policy=OVERRIDE, i-signal-type=PRIMITIVE, init-value=0, base-type=BT_WFS_Klemmenfreigabe, compu {0=Cx0_keine_Freigabe (CM_WFS_Klemmenfreigabe_Cx0_keine_Freigabe), 1=Cx1_Freigabe (CM_WFS_Klemmenfreigabe_Cx1_Freigabe)}, range raw 0..1, transfer-property=TRIGGERED-ON-CHANGE-WITHOUT-REPETITION  # Freigabe von der WFS zum Einschalten der Klemme 15 und Klemme S
          signal WFS_ELV_authorisiert_XIX_WFS_02_XIX_HCP5_CANFD01: start 170, 1 bit, little-endian, data-type-policy=OVERRIDE, i-signal-type=PRIMITIVE, init-value=0, base-type=BT_WFS_ELV_authorisiert, compu {0=Cx0_ELV_nicht_authorisiert (CM_WFS_ELV_authorisiert_Cx0_ELV_nicht_authorisiert), 1=Cx1_ELV_authorisiert (CM_WFS_ELV_authorisiert_Cx1_ELV_authorisiert)}, range raw 0..1, transfer-property=PENDING  # Authorisierung der elektrischen Lenkungsverriegelung an der WFS
          signal WFS_Betrieb_Lesespule_XIX_WFS_02_XIX_HCP5_CANFD01: start 171, 1 bit, little-endian, data-type-policy=OVERRIDE, i-signal-type=PRIMITIVE, init-value=0, base-type=BT_WFS_Betrieb_Lesespule, compu {0=Cx0_keine_Schluesselkomm_Lesespule (CM_WFS_Betrieb_Lesespule_Cx0_keine_Schluesselkomm_Lesespule), 1=Cx1_Schluesselkomm_Lesespule (CM_WFS_Betrieb_Lesespule_Cx1_Schluesselkomm_Lesespule)}, range raw 0..1, transfer-property=PENDING  # Schlüsselkommunikation über die Lesespule
          signal WFS_LF_Aktiv_XIX_WFS_02_XIX_HCP5_CANFD01: start 172, 1 bit, little-endian, data-type-policy=OVERRIDE, i-signal-type=PRIMITIVE, init-value=0, base-type=BT_WFS_LF_Aktiv, compu {0=Cx0_Funktempfang_nicht_aktiv (CM_WFS_LF_Aktiv_Cx0_Funktempfang_nicht_aktiv), 1=Cx1_LF_Funkempfang_aktiv (CM_WFS_LF_Aktiv_Cx1_LF_Funkempfang_aktiv)}, range raw 0..1, transfer-property=PENDING  # LF Schluesselkommunikation
          signal WFS_LZ_02_XIX_WFS_02_XIX_HCP5_CANFD01: start 173, 4 bit, little-endian, data-type-policy=OVERRIDE, i-signal-type=PRIMITIVE, init-value=0, base-type=BT_WFS_LZ_02, invalid-value=Invalid_WFS_LZ_02_XIX_WFS_02_XIX_HCP5_CANFD01:9, compu {0=Cx0_Lieferant_Init (CM_WFS_LZ_02_Cx0_Lieferant_Init) (Lieferant/Init), 1=Cx1_fabrikneu (CM_WFS_LZ_02_Cx1_fabrikneu), 2=Cx2_angelernt (CM_WFS_LZ_02_Cx2_angelernt), 3=Cx3_Schluessel_lernen_Kundendienst (CM_WFS_LZ_02_Cx3_Schluessel_lernen_Kundendienst), 4=Cx4_Schluessel_lernen_Produktion (CM_WFS_LZ_02_Cx4_Schluessel_lernen_Produktion), 8=Cx8_WFS_temporaer_nicht_verfuegbar (CM_WFS_LZ_02_Cx8_WFS_temporaer_nicht_verfuegbar), 9=Cx9_Fehler (CM_WFS_LZ_02_Cx9_Fehler)}, range raw 0..9, transfer-property=TRIGGERED-ON-CHANGE-WITHOUT-REPETITION  # Inbetriebnahme/Anlernzustand der Wegfahrsperre
          signal IMMO_Display_XIX_WFS_02_XIX_HCP5_CANFD01: start 177, 2 bit, little-endian, data-type-policy=OVERRIDE, i-signal-type=PRIMITIVE, init-value=0, base-type=BT_IMMO_Display, invalid-value=Invalid_IMMO_Display_XIX_WFS_02_XIX_HCP5_CANFD01:2, compu {0=Cx0_keine_Anzeige (CM_IMMO_Display_Cx0_keine_Anzeige) (keine Anzeige), 1=Cx1_Anzeige (CM_IMMO_Display_Cx1_Anzeige), 2=Cx2_Fehler (CM_IMMO_Display_Cx2_Fehler)}, range raw 0..2, transfer-property=TRIGGERED-ON-CHANGE-WITHOUT-REPETITION  # Signal zur Steuerung der WFS-Anzeige im Kombi (Service)
          signal IMMO_ClampPermStatus_XIX_WFS_02_XIX_HCP5_CANFD01: start 179, 4 bit, little-endian, data-type-policy=OVERRIDE, i-signal-type=PRIMITIVE, init-value=15, base-type=BT_IMMO_ClampPermStatus, compu {0=Cx0_keine_Freigabe (CM_IMMO_ClampPermStatus_Cx0_keine_Freigabe), 1=Cx1_Normale_Freigabe (CM_IMMO_ClampPermStatus_Cx1_Normale_Freigabe), 3=Cx3_Diagnose_Freigabe (CM_IMMO_ClampPermStatus_Cx3_Diagnose_Freigabe), 5=Cx5_RemoteDrive_Freigabe_Leistungsbereitstellung_mit_Vortrieb (CM_IMMO_ClampPermStatus_Cx5_RemoteDrive_Freigabe_Leistungsbereitstellung_mit_Vortrieb), 9=Cx9_RemoteStart_Freigabe_Leistungsbereitstellung (CM_IMMO_ClampPermStatus_Cx9_RemoteStart_Freigabe_Leistungsbereitstellung), 14=Cxe_Busy (CM_IMMO_ClampPermStatus_Cxe_Busy), 15=Cxf_Init (CM_IMMO_ClampPermStatus_Cxf_Init)}, range raw 0..15, transfer-property=TRIGGERED-ON-CHANGE-WITHOUT-REPETITION  # Antwortsignal der WFS an die Klemmensteuerung zur Klemmenfreigabe
      frame XCP_BJB_CRO_01_XIX_HCP5_CANFD01: id 0x18FCD000, to BMC_HV, frame-length=8, can-addressing-mode=EXTENDED, can-frame-rx-behavior=CAN-FD, can-frame-tx-behavior=CAN-FD
        user defined pdu CDD_XCP_BJB_CRO_01_XIX_HCP5_CANFD01: length=8, cdd-type=EID
      frame XCP_BJB_DTO_01_XIX_HCP5_CANFD01: id 0x18FCD001, from BMC_HV, frame-length=8, can-addressing-mode=EXTENDED, can-frame-rx-behavior=CAN-FD, can-frame-tx-behavior=CAN-FD
        user defined pdu CDD_XCP_BJB_DTO_01_XIX_HCP5_CANFD01: length=8, cdd-type=EID
      frame XCP_Hybrid_01_CRO_01_FD_XIX_HCP5_CANFD01: id 0x1BFC6700, to BMC_HV, frame-length=64, can-addressing-mode=EXTENDED, can-frame-rx-behavior=CAN-FD, can-frame-tx-behavior=CAN-FD
        general purpose i pdu XCP_Hybrid_01_CRO_01_FD_XIX_HCP5_CANFD01: category=XCP, length=64
